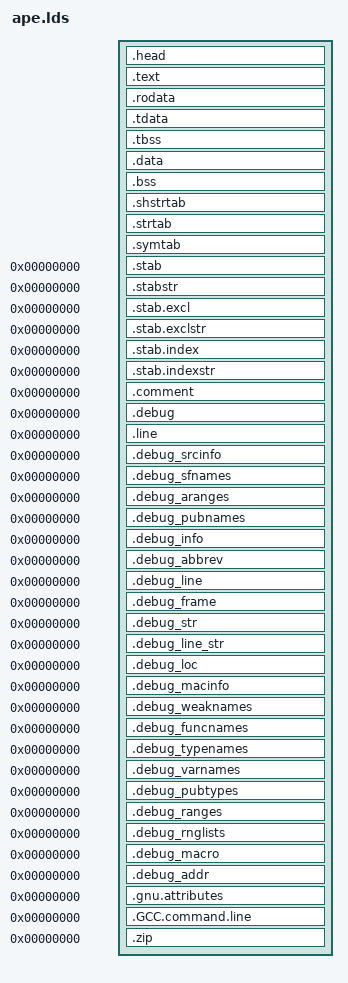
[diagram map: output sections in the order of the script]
ENTRY(_start)
PHDRS {
  Head 1 FLAGS(1|4);
  Cod 1 FLAGS(1|4);
  Rom 1 FLAGS(4);
  Tls 7 FLAGS(2|4);
  Ram 1 FLAGS(2|4);
  stack 0x6474e551 FLAGS(2|4);
}
SECTIONS {
  .head SEGMENT_START("text-segment", 0x400000) + 0 : AT(0x2000) {
    __executable_start = .;
    KEEP(*(.head))
    KEEP(*(.apesh))
    KEEP(*(.text.head))
    . = ALIGN(. != 0 ? 8 : 0);
    ape_phdrs = .;
    KEEP(*(.elf.phdrs))
    ape_phdrs_end = .;
    KEEP(*(.emushprologue))
    KEEP(*(.emush))
    KEEP(*(.emushepilogue))
    . = ALIGN(. != 0 ? 8 : 0);
    ape_note = .;
    KEEP(*(.note.openbsd.ident))
    KEEP(*(.note.netbsd.ident))
    ape_note_end = .;
    KEEP(*(.pe.header))
    ape_pe_sections = .;
    KEEP(*(.pe.sections))
    ape_pe_sections_end = .;
    KEEP(*(.macho))
    . = ALIGN(. != 0 ? 8 : 0);
    ape_macho_end = .;
    KEEP(*(.ape.loader))
    . = ALIGN(. != 0 ? 1 : 0);
    KEEP(*(.ape.pad.head))
    . = ALIGN(. != 0 ? (((255 & 4) == 4) || ((255 & 2) == 2) ? CONSTANT(COMMONPAGESIZE) : 16) : 0);
    _ehead = .;
  } :Head
  .text . : {
    BYTE(0x90)
    *(.text.real)
    KEEP(*(SORT_BY_NAME(.sort.text.real.*)))
    _ereal = .;
    . += 1;
    *(.start)
    KEEP(*(.initprologue))
    KEEP(*(SORT_BY_NAME(.init.*)))
    KEEP(*(.init))
    KEEP(*(.initepilogue))
    KEEP(*(.pltprologue))
    *(.plt)
    KEEP(*(.pltepilogue))
    KEEP(*(.pltgotprologue))
    *(.plt.got)
    KEEP(*(.pltgotepilogue))
    *(.text.startup .text.startup.*)
    *(.text.exit .text.exit.*)
    *(.text.unlikely .text.*_unlikely .text.unlikely.*)
    *(SORT_BY_ALIGNMENT(.text.antiquity))
    *(SORT_BY_ALIGNMENT(.text.antiquity.*))
    KEEP(*(.textwindowsprologue))
    *(.text.windows)
    KEEP(*(.textwindowsepilogue))
    KEEP(*(.blink))
    *(SORT_BY_ALIGNMENT(.text.modernity))
    *(SORT_BY_ALIGNMENT(.text.modernity.*))
    *(SORT_BY_ALIGNMENT(.text.hot))
    *(SORT_BY_ALIGNMENT(.text.hot.*))
    KEEP(*(.keep.text))
    *(.text .stub .text.*)
    KEEP(*(SORT_BY_NAME(.sort.text.*)))
    KEEP(*(.ape.pad.test));
    *(.test.unlikely)
    *(.test .test.*)
    KEEP(*(.ape.pad.privileged));
    . = ALIGN(__privileged_end > __privileged_start ? CONSTANT(COMMONPAGESIZE) : 0);
    __privileged_start = .;
    *(.privileged)
    __privileged_end = .;
    KEEP(*(.ape.pad.text))
    . = ALIGN(. != 0 ? CONSTANT(COMMONPAGESIZE) : 0);
  } :Cod
  .rodata . : {
    KEEP(*(.rodata.pytab.0));
    KEEP(*(.rodata.pytab.1));
    KEEP(*(.rodata.pytab.2));
    *(.rodata .rodata.*)
    *(.ubsan.types)
    *(.ubsan.data)
    KEEP(*(.commentprologue))
    KEEP(*(.comment))
    KEEP(*(.commentepilogue))
    KEEP(*(.idata.ro));
    KEEP(*(SORT_BY_NAME(.idata.ro.*)))
    KEEP(*(.initroprologue))
    KEEP(*(SORT_BY_NAME(.initro.*)))
    KEEP(*(.initroepilogue))
    KEEP(*(SORT_BY_NAME(.sort.rodata.*)))
    . = ALIGN(. != 0 ? CONSTANT(COMMONPAGESIZE) : 0);
  } :Rom
  .tdata . : {
    _tdata_start = .;
    *(SORT_BY_ALIGNMENT(.tdata))
    *(SORT_BY_ALIGNMENT(.tdata.*))
    _tdata_end = .;
    KEEP(*(.ape.pad.rodata))
    . = ALIGN(. != 0 ? CONSTANT(COMMONPAGESIZE) : 0);
    _etext = .;
    PROVIDE(etext = .);
  } :Tls :Rom
  . = ALIGN(CONSTANT(COMMONPAGESIZE));
  .tbss : {
    _tbss_start = .;
    *(SORT_BY_ALIGNMENT(.tbss))
    *(SORT_BY_ALIGNMENT(.tbss.*))
    KEEP(*(.fstls))
    _tbss_end = .;
  } :Tls
  .data . : {
    KEEP(*(SORT_BY_NAME(.piro.data.sort.iat.*)))
    KEEP(*(.dataprologue))
    *(.data .data.*)
    *(.PyRuntime)
    *(.subrs)
    KEEP(*(SORT_BY_NAME(.sort.data.*)))
    . += . > 0 ? 1 : 0;
    KEEP(*(.gotprologue))
    *(.got)
    KEEP(*(.gotepilogue))
    KEEP(*(.gotpltprologue))
    *(.got.plt)
    KEEP(*(.gotpltepilogue))
    . = ALIGN(. != 0 ? 8 : 0);
    __init_array_start = .;
    KEEP(*(SORT_BY_INIT_PRIORITY(.init_array.*)
           SORT_BY_INIT_PRIORITY(.ctors.*)))
    KEEP(*(.ctors))
    KEEP(*(.init_array))
    KEEP(*(.preinit_array))
    __init_array_end = .;
    . = ALIGN(. != 0 ? 8 : 0);
    __fini_array_start = .;
    KEEP(*(SORT_BY_INIT_PRIORITY(.fini_array.*)
           SORT_BY_INIT_PRIORITY(.dtors.*)))
    KEEP(*(.fini_array))
    KEEP(*(.dtors))
    __fini_array_end = .;
    . = ALIGN(. != 0 ? 8 : 0);
    KEEP(*(SORT_BY_NAME(.piro.relo.sort.*)))
    . = ALIGN(. != 0 ? 8 : 0);
    KEEP(*(SORT_BY_NAME(.piro.data.sort.*)))
    KEEP(*(.piro.pad.data))
    KEEP(*(.dataepilogue))
    . = ALIGN(. != 0 ? CONSTANT(COMMONPAGESIZE) : 0);
    _edata = .;
    PROVIDE(edata = .);
    _ezip = .;
  } :Ram
  . = ALIGN(CONSTANT(COMMONPAGESIZE));
  .bss : {
    KEEP(*(.bssprologue))
    KEEP(*(SORT_BY_NAME(.piro.bss.init.*)))
    *(.piro.bss)
    KEEP(*(SORT_BY_NAME(.piro.bss.sort.*)))
    __piro_end = .;
    . += . > 0 ? 1 : 0;
    *(SORT_BY_ALIGNMENT(.bss))
    *(SORT_BY_ALIGNMENT(.bss.*))
    *(COMMON)
    KEEP(*(SORT_BY_NAME(.sort.bss.*)))
    KEEP(*(.bssepilogue))
    . = ALIGN(. != 0 ? CONSTANT(COMMONPAGESIZE) : 0);
  } :Ram
  . = ALIGN(CONSTANT(COMMONPAGESIZE));
  _end = .;
  PROVIDE(end = .);
  .shstrtab : { *(.shstrtab) }
  .strtab : { *(.strtab) }
  .symtab : { *(.symtab) }
  .stab 0 : { *(.stab) }
  .stabstr 0 : { *(.stabstr) }
  .stab.excl 0 : { *(.stab.excl) }
  .stab.exclstr 0 : { *(.stab.exclstr) }
  .stab.index 0 : { *(.stab.index) }
  .stab.indexstr 0 : { *(.stab.indexstr) }
  .comment 0 : { *(.comment) }
  .debug 0 : { *(.debug) }
  .line 0 : { *(.line) }
  .debug_srcinfo 0 : { *(.debug_srcinfo) }
  .debug_sfnames 0 : { *(.debug_sfnames) }
  .debug_aranges 0 : { *(.debug_aranges) }
  .debug_pubnames 0 : { *(.debug_pubnames) }
  .debug_info 0 : { *(.debug_info .gnu.linkonce.wi.*) }
  .debug_abbrev 0 : { *(.debug_abbrev) }
  .debug_line 0 : { *(.debug_line .debug_line.* .debug_line_end ) }
  .debug_frame 0 : { *(.debug_frame) }
  .debug_str 0 : { *(.debug_str) }
  .debug_line_str 0 : { *(.debug_line_str) }
  .debug_loc 0 : { *(.debug_loc) }
  .debug_macinfo 0 : { *(.debug_macinfo) }
  .debug_weaknames 0 : { *(.debug_weaknames) }
  .debug_funcnames 0 : { *(.debug_funcnames) }
  .debug_typenames 0 : { *(.debug_typenames) }
  .debug_varnames 0 : { *(.debug_varnames) }
  .debug_pubtypes 0 : { *(.debug_pubtypes) }
  .debug_ranges 0 : { *(.debug_ranges) }
  .debug_rnglists 0 : { *(.debug_rnglists) }
  .debug_macro 0 : { *(.debug_macro) }
  .debug_addr 0 : { *(.debug_addr) }
  .gnu.attributes 0 : { KEEP(*(.gnu.attributes)) }
  .GCC.command.line 0 : { *(.GCC.command.line) }
  .zip 0 : {
    KEEP(*(.zip.file))
    __zip_cdir_start = .;
    KEEP(*(.zip.cdir))
    __zip_cdir_size = . - __zip_cdir_start;
    KEEP(*(.zip.eocd))
  }
  /DISCARD/ : {
    *(__patchable_function_entries)
    *(__mcount_loc)
    *(.discard)
    *(.yoink)
  }
}
ape_pe_filealignment = 512;
ape_pe_sectionalignment = 4096;
ape_pe_sizeofheaders = SIZEOF(.head);
ape_pe_sizeofimage = (((_end - __executable_start) + (ape_pe_sectionalignment)-1) & -(ape_pe_sectionalignment));
HIDDEN(ape_elf_entry = (_start)); HIDDEN(ape_elf_entry_bcs0 = (((((((_start) >> ((0)*8)) >> 0)&0x7) + 0x30) << 24) | ((((((_start) >> ((0)*8)) >> 3)&0x7) + 0x30) << 16) | (((((((_start) >> ((0)*8))&0xff) >> 6)&0x7) + 0x30) << 8) | 0x5c)); HIDDEN(ape_elf_entry_bcs1 = (((((((_start) >> ((1)*8)) >> 0)&0x7) + 0x30) << 24) | ((((((_start) >> ((1)*8)) >> 3)&0x7) + 0x30) << 16) | (((((((_start) >> ((1)*8))&0xff) >> 6)&0x7) + 0x30) << 8) | 0x5c)); HIDDEN(ape_elf_entry_bcs2 = (((((((_start) >> ((2)*8)) >> 0)&0x7) + 0x30) << 24) | ((((((_start) >> ((2)*8)) >> 3)&0x7) + 0x30) << 16) | (((((((_start) >> ((2)*8))&0xff) >> 6)&0x7) + 0x30) << 8) | 0x5c)); HIDDEN(ape_elf_entry_bcs3 = (((((((_start) >> ((3)*8)) >> 0)&0x7) + 0x30) << 24) | ((((((_start) >> ((3)*8)) >> 3)&0x7) + 0x30) << 16) | (((((((_start) >> ((3)*8))&0xff) >> 6)&0x7) + 0x30) << 8) | 0x5c)); HIDDEN(ape_elf_entry_bcs4 = (((((((_start) >> ((4)*8)) >> 0)&0x7) + 0x30) << 24) | ((((((_start) >> ((4)*8)) >> 3)&0x7) + 0x30) << 16) | (((((((_start) >> ((4)*8))&0xff) >> 6)&0x7) + 0x30) << 8) | 0x5c)); HIDDEN(ape_elf_entry_bcs5 = (((((((_start) >> ((5)*8)) >> 0)&0x7) + 0x30) << 24) | ((((((_start) >> ((5)*8)) >> 3)&0x7) + 0x30) << 16) | (((((((_start) >> ((5)*8))&0xff) >> 6)&0x7) + 0x30) << 8) | 0x5c)); HIDDEN(ape_elf_entry_bcs6 = (((((((_start) >> ((6)*8)) >> 0)&0x7) + 0x30) << 24) | ((((((_start) >> ((6)*8)) >> 3)&0x7) + 0x30) << 16) | (((((((_start) >> ((6)*8))&0xff) >> 6)&0x7) + 0x30) << 8) | 0x5c)); HIDDEN(ape_elf_entry_bcs7 = (((((((_start) >> ((7)*8)) >> 0)&0x7) + 0x30) << 24) | ((((((_start) >> ((7)*8)) >> 3)&0x7) + 0x30) << 16) | (((((((_start) >> ((7)*8))&0xff) >> 6)&0x7) + 0x30) << 8) | 0x5c));
HIDDEN(ape_elf_phoff = (((ape_phdrs) - (0x400000)))); HIDDEN(ape_elf_phoff_bcs0 = (((((((((ape_phdrs) - (0x400000))) >> ((0)*8)) >> 0)&0x7) + 0x30) << 24) | ((((((((ape_phdrs) - (0x400000))) >> ((0)*8)) >> 3)&0x7) + 0x30) << 16) | (((((((((ape_phdrs) - (0x400000))) >> ((0)*8))&0xff) >> 6)&0x7) + 0x30) << 8) | 0x5c)); HIDDEN(ape_elf_phoff_bcs1 = (((((((((ape_phdrs) - (0x400000))) >> ((1)*8)) >> 0)&0x7) + 0x30) << 24) | ((((((((ape_phdrs) - (0x400000))) >> ((1)*8)) >> 3)&0x7) + 0x30) << 16) | (((((((((ape_phdrs) - (0x400000))) >> ((1)*8))&0xff) >> 6)&0x7) + 0x30) << 8) | 0x5c)); HIDDEN(ape_elf_phoff_bcs2 = (((((((((ape_phdrs) - (0x400000))) >> ((2)*8)) >> 0)&0x7) + 0x30) << 24) | ((((((((ape_phdrs) - (0x400000))) >> ((2)*8)) >> 3)&0x7) + 0x30) << 16) | (((((((((ape_phdrs) - (0x400000))) >> ((2)*8))&0xff) >> 6)&0x7) + 0x30) << 8) | 0x5c)); HIDDEN(ape_elf_phoff_bcs3 = (((((((((ape_phdrs) - (0x400000))) >> ((3)*8)) >> 0)&0x7) + 0x30) << 24) | ((((((((ape_phdrs) - (0x400000))) >> ((3)*8)) >> 3)&0x7) + 0x30) << 16) | (((((((((ape_phdrs) - (0x400000))) >> ((3)*8))&0xff) >> 6)&0x7) + 0x30) << 8) | 0x5c)); HIDDEN(ape_elf_phoff_bcs4 = (((((((((ape_phdrs) - (0x400000))) >> ((4)*8)) >> 0)&0x7) + 0x30) << 24) | ((((((((ape_phdrs) - (0x400000))) >> ((4)*8)) >> 3)&0x7) + 0x30) << 16) | (((((((((ape_phdrs) - (0x400000))) >> ((4)*8))&0xff) >> 6)&0x7) + 0x30) << 8) | 0x5c)); HIDDEN(ape_elf_phoff_bcs5 = (((((((((ape_phdrs) - (0x400000))) >> ((5)*8)) >> 0)&0x7) + 0x30) << 24) | ((((((((ape_phdrs) - (0x400000))) >> ((5)*8)) >> 3)&0x7) + 0x30) << 16) | (((((((((ape_phdrs) - (0x400000))) >> ((5)*8))&0xff) >> 6)&0x7) + 0x30) << 8) | 0x5c)); HIDDEN(ape_elf_phoff_bcs6 = (((((((((ape_phdrs) - (0x400000))) >> ((6)*8)) >> 0)&0x7) + 0x30) << 24) | ((((((((ape_phdrs) - (0x400000))) >> ((6)*8)) >> 3)&0x7) + 0x30) << 16) | (((((((((ape_phdrs) - (0x400000))) >> ((6)*8))&0xff) >> 6)&0x7) + 0x30) << 8) | 0x5c)); HIDDEN(ape_elf_phoff_bcs7 = (((((((((ape_phdrs) - (0x400000))) >> ((7)*8)) >> 0)&0x7) + 0x30) << 24) | ((((((((ape_phdrs) - (0x400000))) >> ((7)*8)) >> 3)&0x7) + 0x30) << 16) | (((((((((ape_phdrs) - (0x400000))) >> ((7)*8))&0xff) >> 6)&0x7) + 0x30) << 8) | 0x5c));
HIDDEN(ape_elf_shoff = (0)); HIDDEN(ape_elf_shoff_bcs0 = (((((((0) >> ((0)*8)) >> 0)&0x7) + 0x30) << 24) | ((((((0) >> ((0)*8)) >> 3)&0x7) + 0x30) << 16) | (((((((0) >> ((0)*8))&0xff) >> 6)&0x7) + 0x30) << 8) | 0x5c)); HIDDEN(ape_elf_shoff_bcs1 = (((((((0) >> ((1)*8)) >> 0)&0x7) + 0x30) << 24) | ((((((0) >> ((1)*8)) >> 3)&0x7) + 0x30) << 16) | (((((((0) >> ((1)*8))&0xff) >> 6)&0x7) + 0x30) << 8) | 0x5c)); HIDDEN(ape_elf_shoff_bcs2 = (((((((0) >> ((2)*8)) >> 0)&0x7) + 0x30) << 24) | ((((((0) >> ((2)*8)) >> 3)&0x7) + 0x30) << 16) | (((((((0) >> ((2)*8))&0xff) >> 6)&0x7) + 0x30) << 8) | 0x5c)); HIDDEN(ape_elf_shoff_bcs3 = (((((((0) >> ((3)*8)) >> 0)&0x7) + 0x30) << 24) | ((((((0) >> ((3)*8)) >> 3)&0x7) + 0x30) << 16) | (((((((0) >> ((3)*8))&0xff) >> 6)&0x7) + 0x30) << 8) | 0x5c)); HIDDEN(ape_elf_shoff_bcs4 = (((((((0) >> ((4)*8)) >> 0)&0x7) + 0x30) << 24) | ((((((0) >> ((4)*8)) >> 3)&0x7) + 0x30) << 16) | (((((((0) >> ((4)*8))&0xff) >> 6)&0x7) + 0x30) << 8) | 0x5c)); HIDDEN(ape_elf_shoff_bcs5 = (((((((0) >> ((5)*8)) >> 0)&0x7) + 0x30) << 24) | ((((((0) >> ((5)*8)) >> 3)&0x7) + 0x30) << 16) | (((((((0) >> ((5)*8))&0xff) >> 6)&0x7) + 0x30) << 8) | 0x5c)); HIDDEN(ape_elf_shoff_bcs6 = (((((((0) >> ((6)*8)) >> 0)&0x7) + 0x30) << 24) | ((((((0) >> ((6)*8)) >> 3)&0x7) + 0x30) << 16) | (((((((0) >> ((6)*8))&0xff) >> 6)&0x7) + 0x30) << 8) | 0x5c)); HIDDEN(ape_elf_shoff_bcs7 = (((((((0) >> ((7)*8)) >> 0)&0x7) + 0x30) << 24) | ((((((0) >> ((7)*8)) >> 3)&0x7) + 0x30) << 16) | (((((((0) >> ((7)*8))&0xff) >> 6)&0x7) + 0x30) << 8) | 0x5c));
HIDDEN(ape_elf_phnum = ((ape_phdrs_end - ape_phdrs) / 56)); HIDDEN(ape_elf_phnum_bcs0 = ((((((((ape_phdrs_end - ape_phdrs) / 56) >> ((0)*8)) >> 0)&0x7) + 0x30) << 24) | (((((((ape_phdrs_end - ape_phdrs) / 56) >> ((0)*8)) >> 3)&0x7) + 0x30) << 16) | ((((((((ape_phdrs_end - ape_phdrs) / 56) >> ((0)*8))&0xff) >> 6)&0x7) + 0x30) << 8) | 0x5c)); HIDDEN(ape_elf_phnum_bcs1 = ((((((((ape_phdrs_end - ape_phdrs) / 56) >> ((1)*8)) >> 0)&0x7) + 0x30) << 24) | (((((((ape_phdrs_end - ape_phdrs) / 56) >> ((1)*8)) >> 3)&0x7) + 0x30) << 16) | ((((((((ape_phdrs_end - ape_phdrs) / 56) >> ((1)*8))&0xff) >> 6)&0x7) + 0x30) << 8) | 0x5c)); HIDDEN(ape_elf_phnum_bcs2 = ((((((((ape_phdrs_end - ape_phdrs) / 56) >> ((2)*8)) >> 0)&0x7) + 0x30) << 24) | (((((((ape_phdrs_end - ape_phdrs) / 56) >> ((2)*8)) >> 3)&0x7) + 0x30) << 16) | ((((((((ape_phdrs_end - ape_phdrs) / 56) >> ((2)*8))&0xff) >> 6)&0x7) + 0x30) << 8) | 0x5c)); HIDDEN(ape_elf_phnum_bcs3 = ((((((((ape_phdrs_end - ape_phdrs) / 56) >> ((3)*8)) >> 0)&0x7) + 0x30) << 24) | (((((((ape_phdrs_end - ape_phdrs) / 56) >> ((3)*8)) >> 3)&0x7) + 0x30) << 16) | ((((((((ape_phdrs_end - ape_phdrs) / 56) >> ((3)*8))&0xff) >> 6)&0x7) + 0x30) << 8) | 0x5c));
HIDDEN(ape_elf_shnum = (0)); HIDDEN(ape_elf_shnum_bcs0 = (((((((0) >> ((0)*8)) >> 0)&0x7) + 0x30) << 24) | ((((((0) >> ((0)*8)) >> 3)&0x7) + 0x30) << 16) | (((((((0) >> ((0)*8))&0xff) >> 6)&0x7) + 0x30) << 8) | 0x5c)); HIDDEN(ape_elf_shnum_bcs1 = (((((((0) >> ((1)*8)) >> 0)&0x7) + 0x30) << 24) | ((((((0) >> ((1)*8)) >> 3)&0x7) + 0x30) << 16) | (((((((0) >> ((1)*8))&0xff) >> 6)&0x7) + 0x30) << 8) | 0x5c)); HIDDEN(ape_elf_shnum_bcs2 = (((((((0) >> ((2)*8)) >> 0)&0x7) + 0x30) << 24) | ((((((0) >> ((2)*8)) >> 3)&0x7) + 0x30) << 16) | (((((((0) >> ((2)*8))&0xff) >> 6)&0x7) + 0x30) << 8) | 0x5c)); HIDDEN(ape_elf_shnum_bcs3 = (((((((0) >> ((3)*8)) >> 0)&0x7) + 0x30) << 24) | ((((((0) >> ((3)*8)) >> 3)&0x7) + 0x30) << 16) | (((((((0) >> ((3)*8))&0xff) >> 6)&0x7) + 0x30) << 8) | 0x5c));
HIDDEN(ape_elf_shstrndx = (0)); HIDDEN(ape_elf_shstrndx_bcs0 = (((((((0) >> ((0)*8)) >> 0)&0x7) + 0x30) << 24) | ((((((0) >> ((0)*8)) >> 3)&0x7) + 0x30) << 16) | (((((((0) >> ((0)*8))&0xff) >> 6)&0x7) + 0x30) << 8) | 0x5c)); HIDDEN(ape_elf_shstrndx_bcs1 = (((((((0) >> ((1)*8)) >> 0)&0x7) + 0x30) << 24) | ((((((0) >> ((1)*8)) >> 3)&0x7) + 0x30) << 16) | (((((((0) >> ((1)*8))&0xff) >> 6)&0x7) + 0x30) << 8) | 0x5c)); HIDDEN(ape_elf_shstrndx_bcs2 = (((((((0) >> ((2)*8)) >> 0)&0x7) + 0x30) << 24) | ((((((0) >> ((2)*8)) >> 3)&0x7) + 0x30) << 16) | (((((((0) >> ((2)*8))&0xff) >> 6)&0x7) + 0x30) << 8) | 0x5c)); HIDDEN(ape_elf_shstrndx_bcs3 = (((((((0) >> ((3)*8)) >> 0)&0x7) + 0x30) << 24) | ((((((0) >> ((3)*8)) >> 3)&0x7) + 0x30) << 16) | (((((((0) >> ((3)*8))&0xff) >> 6)&0x7) + 0x30) << 8) | 0x5c));
_tls_size = _tbss_end - _tdata_start;
_tdata_size = _tdata_end - _tdata_start;
_tbss_size = _tbss_end - _tbss_start;
_tbss_offset = _tbss_start - _tdata_start;
_tls_content = (_tdata_end - _tdata_start) + (_tbss_end - _tbss_start);
_tls_align = 1;
ape_cod_offset = 0;
ape_cod_vaddr = ADDR(.head);
ape_cod_paddr = LOADADDR(.head);
ape_cod_filesz = ADDR(.rodata) - ADDR(.head);
ape_cod_memsz = ape_cod_filesz;
ape_cod_align = CONSTANT(COMMONPAGESIZE);
ape_cod_rva = ((ape_cod_vaddr) - (0x400000));
ape_rom_vaddr = ADDR(.rodata);
ape_rom_offset = ape_rom_vaddr - __executable_start;
ape_rom_paddr = LOADADDR(.rodata);
ape_rom_filesz = ADDR(.tbss) - ADDR(.rodata);
ape_rom_memsz = ape_rom_filesz;
ape_rom_align = CONSTANT(COMMONPAGESIZE);
ape_rom_rva = ((ape_rom_vaddr) - (0x400000));
ape_ram_vaddr = ADDR(.data);
ape_ram_offset = ape_ram_vaddr - __executable_start;
ape_ram_paddr = LOADADDR(.data);
ape_ram_filesz = ADDR(.bss) - ADDR(.data);
ape_ram_memsz = _end - ADDR(.data);
ape_ram_align = CONSTANT(COMMONPAGESIZE);
ape_ram_rva = ((ape_ram_vaddr) - (0x400000));
ape_stack_pf = DEFINED(ape_stack_pf) ? ape_stack_pf : 4 | 2;
ape_stack_prot = ((4 & (ape_stack_pf)) >> 2 | (2 & (ape_stack_pf)) | (1 & (ape_stack_pf)) << 2);
ape_stack_offset = 0;
ape_stack_vaddr = DEFINED(ape_stack_vaddr) ? ape_stack_vaddr : 0x700000000000;
ape_stack_paddr = ape_ram_paddr + ape_ram_filesz;
ape_stack_filesz = 0;
ape_stack_memsz = DEFINED(ape_stack_memsz) ? ape_stack_memsz : 8 * 1024 * 1024;
ape_stack_align = DEFINED(ape_stack_align) ? ape_stack_align : 16;
ape_stack_round = -ape_stack_align;
ape_note_offset = ape_cod_offset + (ape_note - ape_cod_vaddr);
ape_note_filesz = ape_note_end - ape_note;
ape_note_memsz = ape_note_filesz;
ape_text_vaddr = ADDR(.text);
ape_text_offset = ape_text_vaddr - __executable_start;
ape_text_paddr = LOADADDR(.text);
ape_text_filesz = ADDR(.rodata) - ADDR(.text);
ape_text_memsz = ape_text_filesz;
ape_text_align = CONSTANT(COMMONPAGESIZE);
ape_text_rva = ((ape_text_vaddr) - (0x400000));
HIDDEN(ape_loader_dd_skip_bcs0 = (((DEFINED(ape_loader) ? ((ape_loader) - (0x400000)) / 64 : 0)) < 10000 ? (((((DEFINED(ape_loader) ? ((ape_loader) - (0x400000)) / 64 : 0) + (DEFINED(ape_loader) ? ((ape_loader) - (0x400000)) / 64 : 0) * 10000))) < 10000 ? 0x20202020 : (((DEFINED(ape_loader) ? ((ape_loader) - (0x400000)) / 64 : 0) + (DEFINED(ape_loader) ? ((ape_loader) - (0x400000)) / 64 : 0) * 10000)) < 100000 ? 0x20202030 + (((DEFINED(ape_loader) ? ((ape_loader) - (0x400000)) / 64 : 0) + (DEFINED(ape_loader) ? ((ape_loader) - (0x400000)) / 64 : 0) * 10000)) % 10 : (((DEFINED(ape_loader) ? ((ape_loader) - (0x400000)) / 64 : 0) + (DEFINED(ape_loader) ? ((ape_loader) - (0x400000)) / 64 : 0) * 10000)) < 1000000 ? 0x20203030 + ((((DEFINED(ape_loader) ? ((ape_loader) - (0x400000)) / 64 : 0) + (DEFINED(ape_loader) ? ((ape_loader) - (0x400000)) / 64 : 0) * 10000)) / 10) % 10 + (((DEFINED(ape_loader) ? ((ape_loader) - (0x400000)) / 64 : 0) + (DEFINED(ape_loader) ? ((ape_loader) - (0x400000)) / 64 : 0) * 10000)) % 10 * 0x100 : (((DEFINED(ape_loader) ? ((ape_loader) - (0x400000)) / 64 : 0) + (DEFINED(ape_loader) ? ((ape_loader) - (0x400000)) / 64 : 0) * 10000)) < 10000000 ? 0x20303030 + ((((DEFINED(ape_loader) ? ((ape_loader) - (0x400000)) / 64 : 0) + (DEFINED(ape_loader) ? ((ape_loader) - (0x400000)) / 64 : 0) * 10000)) / 100) % 10 + ((((DEFINED(ape_loader) ? ((ape_loader) - (0x400000)) / 64 : 0) + (DEFINED(ape_loader) ? ((ape_loader) - (0x400000)) / 64 : 0) * 10000)) / 10) % 10 * 0x100 + (((DEFINED(ape_loader) ? ((ape_loader) - (0x400000)) / 64 : 0) + (DEFINED(ape_loader) ? ((ape_loader) - (0x400000)) / 64 : 0) * 10000)) % 10 * 0x10000 : (((DEFINED(ape_loader) ? ((ape_loader) - (0x400000)) / 64 : 0) + (DEFINED(ape_loader) ? ((ape_loader) - (0x400000)) / 64 : 0) * 10000)) < 100000000 ? 0x30303030 + ((((DEFINED(ape_loader) ? ((ape_loader) - (0x400000)) / 64 : 0) + (DEFINED(ape_loader) ? ((ape_loader) - (0x400000)) / 64 : 0) * 10000)) / 1000) % 10 + ((((DEFINED(ape_loader) ? ((ape_loader) - (0x400000)) / 64 : 0) + (DEFINED(ape_loader) ? ((ape_loader) - (0x400000)) / 64 : 0) * 10000)) / 100) % 10 * 0x100 + ((((DEFINED(ape_loader) ? ((ape_loader) - (0x400000)) / 64 : 0) + (DEFINED(ape_loader) ? ((ape_loader) - (0x400000)) / 64 : 0) * 10000)) / 10) % 10 * 0x10000 + (((DEFINED(ape_loader) ? ((ape_loader) - (0x400000)) / 64 : 0) + (DEFINED(ape_loader) ? ((ape_loader) - (0x400000)) / 64 : 0) * 10000)) % 10 * 0x1000000 : 0xffffffffffffffff) | 0x10 : (DEFINED(ape_loader) ? ((ape_loader) - (0x400000)) / 64 : 0) < 100000 ? ((((((DEFINED(ape_loader) ? ((ape_loader) - (0x400000)) / 64 : 0) / 10) + ((DEFINED(ape_loader) ? ((ape_loader) - (0x400000)) / 64 : 0) / 10) * 10000))) < 10000 ? 0x20202020 : ((((DEFINED(ape_loader) ? ((ape_loader) - (0x400000)) / 64 : 0) / 10) + ((DEFINED(ape_loader) ? ((ape_loader) - (0x400000)) / 64 : 0) / 10) * 10000)) < 100000 ? 0x20202030 + ((((DEFINED(ape_loader) ? ((ape_loader) - (0x400000)) / 64 : 0) / 10) + ((DEFINED(ape_loader) ? ((ape_loader) - (0x400000)) / 64 : 0) / 10) * 10000)) % 10 : ((((DEFINED(ape_loader) ? ((ape_loader) - (0x400000)) / 64 : 0) / 10) + ((DEFINED(ape_loader) ? ((ape_loader) - (0x400000)) / 64 : 0) / 10) * 10000)) < 1000000 ? 0x20203030 + (((((DEFINED(ape_loader) ? ((ape_loader) - (0x400000)) / 64 : 0) / 10) + ((DEFINED(ape_loader) ? ((ape_loader) - (0x400000)) / 64 : 0) / 10) * 10000)) / 10) % 10 + ((((DEFINED(ape_loader) ? ((ape_loader) - (0x400000)) / 64 : 0) / 10) + ((DEFINED(ape_loader) ? ((ape_loader) - (0x400000)) / 64 : 0) / 10) * 10000)) % 10 * 0x100 : ((((DEFINED(ape_loader) ? ((ape_loader) - (0x400000)) / 64 : 0) / 10) + ((DEFINED(ape_loader) ? ((ape_loader) - (0x400000)) / 64 : 0) / 10) * 10000)) < 10000000 ? 0x20303030 + (((((DEFINED(ape_loader) ? ((ape_loader) - (0x400000)) / 64 : 0) / 10) + ((DEFINED(ape_loader) ? ((ape_loader) - (0x400000)) / 64 : 0) / 10) * 10000)) / 100) % 10 + (((((DEFINED(ape_loader) ? ((ape_loader) - (0x400000)) / 64 : 0) / 10) + ((DEFINED(ape_loader) ? ((ape_loader) - (0x400000)) / 64 : 0) / 10) * 10000)) / 10) % 10 * 0x100 + ((((DEFINED(ape_loader) ? ((ape_loader) - (0x400000)) / 64 : 0) / 10) + ((DEFINED(ape_loader) ? ((ape_loader) - (0x400000)) / 64 : 0) / 10) * 10000)) % 10 * 0x10000 : ((((DEFINED(ape_loader) ? ((ape_loader) - (0x400000)) / 64 : 0) / 10) + ((DEFINED(ape_loader) ? ((ape_loader) - (0x400000)) / 64 : 0) / 10) * 10000)) < 100000000 ? 0x30303030 + (((((DEFINED(ape_loader) ? ((ape_loader) - (0x400000)) / 64 : 0) / 10) + ((DEFINED(ape_loader) ? ((ape_loader) - (0x400000)) / 64 : 0) / 10) * 10000)) / 1000) % 10 + (((((DEFINED(ape_loader) ? ((ape_loader) - (0x400000)) / 64 : 0) / 10) + ((DEFINED(ape_loader) ? ((ape_loader) - (0x400000)) / 64 : 0) / 10) * 10000)) / 100) % 10 * 0x100 + (((((DEFINED(ape_loader) ? ((ape_loader) - (0x400000)) / 64 : 0) / 10) + ((DEFINED(ape_loader) ? ((ape_loader) - (0x400000)) / 64 : 0) / 10) * 10000)) / 10) % 10 * 0x10000 + ((((DEFINED(ape_loader) ? ((ape_loader) - (0x400000)) / 64 : 0) / 10) + ((DEFINED(ape_loader) ? ((ape_loader) - (0x400000)) / 64 : 0) / 10) * 10000)) % 10 * 0x1000000 : 0xffffffffffffffff) : (DEFINED(ape_loader) ? ((ape_loader) - (0x400000)) / 64 : 0) < 1000000 ? ((((((DEFINED(ape_loader) ? ((ape_loader) - (0x400000)) / 64 : 0) / 100) + ((DEFINED(ape_loader) ? ((ape_loader) - (0x400000)) / 64 : 0) / 100) * 10000))) < 10000 ? 0x20202020 : ((((DEFINED(ape_loader) ? ((ape_loader) - (0x400000)) / 64 : 0) / 100) + ((DEFINED(ape_loader) ? ((ape_loader) - (0x400000)) / 64 : 0) / 100) * 10000)) < 100000 ? 0x20202030 + ((((DEFINED(ape_loader) ? ((ape_loader) - (0x400000)) / 64 : 0) / 100) + ((DEFINED(ape_loader) ? ((ape_loader) - (0x400000)) / 64 : 0) / 100) * 10000)) % 10 : ((((DEFINED(ape_loader) ? ((ape_loader) - (0x400000)) / 64 : 0) / 100) + ((DEFINED(ape_loader) ? ((ape_loader) - (0x400000)) / 64 : 0) / 100) * 10000)) < 1000000 ? 0x20203030 + (((((DEFINED(ape_loader) ? ((ape_loader) - (0x400000)) / 64 : 0) / 100) + ((DEFINED(ape_loader) ? ((ape_loader) - (0x400000)) / 64 : 0) / 100) * 10000)) / 10) % 10 + ((((DEFINED(ape_loader) ? ((ape_loader) - (0x400000)) / 64 : 0) / 100) + ((DEFINED(ape_loader) ? ((ape_loader) - (0x400000)) / 64 : 0) / 100) * 10000)) % 10 * 0x100 : ((((DEFINED(ape_loader) ? ((ape_loader) - (0x400000)) / 64 : 0) / 100) + ((DEFINED(ape_loader) ? ((ape_loader) - (0x400000)) / 64 : 0) / 100) * 10000)) < 10000000 ? 0x20303030 + (((((DEFINED(ape_loader) ? ((ape_loader) - (0x400000)) / 64 : 0) / 100) + ((DEFINED(ape_loader) ? ((ape_loader) - (0x400000)) / 64 : 0) / 100) * 10000)) / 100) % 10 + (((((DEFINED(ape_loader) ? ((ape_loader) - (0x400000)) / 64 : 0) / 100) + ((DEFINED(ape_loader) ? ((ape_loader) - (0x400000)) / 64 : 0) / 100) * 10000)) / 10) % 10 * 0x100 + ((((DEFINED(ape_loader) ? ((ape_loader) - (0x400000)) / 64 : 0) / 100) + ((DEFINED(ape_loader) ? ((ape_loader) - (0x400000)) / 64 : 0) / 100) * 10000)) % 10 * 0x10000 : ((((DEFINED(ape_loader) ? ((ape_loader) - (0x400000)) / 64 : 0) / 100) + ((DEFINED(ape_loader) ? ((ape_loader) - (0x400000)) / 64 : 0) / 100) * 10000)) < 100000000 ? 0x30303030 + (((((DEFINED(ape_loader) ? ((ape_loader) - (0x400000)) / 64 : 0) / 100) + ((DEFINED(ape_loader) ? ((ape_loader) - (0x400000)) / 64 : 0) / 100) * 10000)) / 1000) % 10 + (((((DEFINED(ape_loader) ? ((ape_loader) - (0x400000)) / 64 : 0) / 100) + ((DEFINED(ape_loader) ? ((ape_loader) - (0x400000)) / 64 : 0) / 100) * 10000)) / 100) % 10 * 0x100 + (((((DEFINED(ape_loader) ? ((ape_loader) - (0x400000)) / 64 : 0) / 100) + ((DEFINED(ape_loader) ? ((ape_loader) - (0x400000)) / 64 : 0) / 100) * 10000)) / 10) % 10 * 0x10000 + ((((DEFINED(ape_loader) ? ((ape_loader) - (0x400000)) / 64 : 0) / 100) + ((DEFINED(ape_loader) ? ((ape_loader) - (0x400000)) / 64 : 0) / 100) * 10000)) % 10 * 0x1000000 : 0xffffffffffffffff) : (DEFINED(ape_loader) ? ((ape_loader) - (0x400000)) / 64 : 0) < 10000000 ? ((((((DEFINED(ape_loader) ? ((ape_loader) - (0x400000)) / 64 : 0) / 1000) + ((DEFINED(ape_loader) ? ((ape_loader) - (0x400000)) / 64 : 0) / 1000) * 10000))) < 10000 ? 0x20202020 : ((((DEFINED(ape_loader) ? ((ape_loader) - (0x400000)) / 64 : 0) / 1000) + ((DEFINED(ape_loader) ? ((ape_loader) - (0x400000)) / 64 : 0) / 1000) * 10000)) < 100000 ? 0x20202030 + ((((DEFINED(ape_loader) ? ((ape_loader) - (0x400000)) / 64 : 0) / 1000) + ((DEFINED(ape_loader) ? ((ape_loader) - (0x400000)) / 64 : 0) / 1000) * 10000)) % 10 : ((((DEFINED(ape_loader) ? ((ape_loader) - (0x400000)) / 64 : 0) / 1000) + ((DEFINED(ape_loader) ? ((ape_loader) - (0x400000)) / 64 : 0) / 1000) * 10000)) < 1000000 ? 0x20203030 + (((((DEFINED(ape_loader) ? ((ape_loader) - (0x400000)) / 64 : 0) / 1000) + ((DEFINED(ape_loader) ? ((ape_loader) - (0x400000)) / 64 : 0) / 1000) * 10000)) / 10) % 10 + ((((DEFINED(ape_loader) ? ((ape_loader) - (0x400000)) / 64 : 0) / 1000) + ((DEFINED(ape_loader) ? ((ape_loader) - (0x400000)) / 64 : 0) / 1000) * 10000)) % 10 * 0x100 : ((((DEFINED(ape_loader) ? ((ape_loader) - (0x400000)) / 64 : 0) / 1000) + ((DEFINED(ape_loader) ? ((ape_loader) - (0x400000)) / 64 : 0) / 1000) * 10000)) < 10000000 ? 0x20303030 + (((((DEFINED(ape_loader) ? ((ape_loader) - (0x400000)) / 64 : 0) / 1000) + ((DEFINED(ape_loader) ? ((ape_loader) - (0x400000)) / 64 : 0) / 1000) * 10000)) / 100) % 10 + (((((DEFINED(ape_loader) ? ((ape_loader) - (0x400000)) / 64 : 0) / 1000) + ((DEFINED(ape_loader) ? ((ape_loader) - (0x400000)) / 64 : 0) / 1000) * 10000)) / 10) % 10 * 0x100 + ((((DEFINED(ape_loader) ? ((ape_loader) - (0x400000)) / 64 : 0) / 1000) + ((DEFINED(ape_loader) ? ((ape_loader) - (0x400000)) / 64 : 0) / 1000) * 10000)) % 10 * 0x10000 : ((((DEFINED(ape_loader) ? ((ape_loader) - (0x400000)) / 64 : 0) / 1000) + ((DEFINED(ape_loader) ? ((ape_loader) - (0x400000)) / 64 : 0) / 1000) * 10000)) < 100000000 ? 0x30303030 + (((((DEFINED(ape_loader) ? ((ape_loader) - (0x400000)) / 64 : 0) / 1000) + ((DEFINED(ape_loader) ? ((ape_loader) - (0x400000)) / 64 : 0) / 1000) * 10000)) / 1000) % 10 + (((((DEFINED(ape_loader) ? ((ape_loader) - (0x400000)) / 64 : 0) / 1000) + ((DEFINED(ape_loader) ? ((ape_loader) - (0x400000)) / 64 : 0) / 1000) * 10000)) / 100) % 10 * 0x100 + (((((DEFINED(ape_loader) ? ((ape_loader) - (0x400000)) / 64 : 0) / 1000) + ((DEFINED(ape_loader) ? ((ape_loader) - (0x400000)) / 64 : 0) / 1000) * 10000)) / 10) % 10 * 0x10000 + ((((DEFINED(ape_loader) ? ((ape_loader) - (0x400000)) / 64 : 0) / 1000) + ((DEFINED(ape_loader) ? ((ape_loader) - (0x400000)) / 64 : 0) / 1000) * 10000)) % 10 * 0x1000000 : 0xffffffffffffffff) : (DEFINED(ape_loader) ? ((ape_loader) - (0x400000)) / 64 : 0) < 100000000 ? ((((((DEFINED(ape_loader) ? ((ape_loader) - (0x400000)) / 64 : 0) / 10000) + ((DEFINED(ape_loader) ? ((ape_loader) - (0x400000)) / 64 : 0) / 10000) * 10000))) < 10000 ? 0x20202020 : ((((DEFINED(ape_loader) ? ((ape_loader) - (0x400000)) / 64 : 0) / 10000) + ((DEFINED(ape_loader) ? ((ape_loader) - (0x400000)) / 64 : 0) / 10000) * 10000)) < 100000 ? 0x20202030 + ((((DEFINED(ape_loader) ? ((ape_loader) - (0x400000)) / 64 : 0) / 10000) + ((DEFINED(ape_loader) ? ((ape_loader) - (0x400000)) / 64 : 0) / 10000) * 10000)) % 10 : ((((DEFINED(ape_loader) ? ((ape_loader) - (0x400000)) / 64 : 0) / 10000) + ((DEFINED(ape_loader) ? ((ape_loader) - (0x400000)) / 64 : 0) / 10000) * 10000)) < 1000000 ? 0x20203030 + (((((DEFINED(ape_loader) ? ((ape_loader) - (0x400000)) / 64 : 0) / 10000) + ((DEFINED(ape_loader) ? ((ape_loader) - (0x400000)) / 64 : 0) / 10000) * 10000)) / 10) % 10 + ((((DEFINED(ape_loader) ? ((ape_loader) - (0x400000)) / 64 : 0) / 10000) + ((DEFINED(ape_loader) ? ((ape_loader) - (0x400000)) / 64 : 0) / 10000) * 10000)) % 10 * 0x100 : ((((DEFINED(ape_loader) ? ((ape_loader) - (0x400000)) / 64 : 0) / 10000) + ((DEFINED(ape_loader) ? ((ape_loader) - (0x400000)) / 64 : 0) / 10000) * 10000)) < 10000000 ? 0x20303030 + (((((DEFINED(ape_loader) ? ((ape_loader) - (0x400000)) / 64 : 0) / 10000) + ((DEFINED(ape_loader) ? ((ape_loader) - (0x400000)) / 64 : 0) / 10000) * 10000)) / 100) % 10 + (((((DEFINED(ape_loader) ? ((ape_loader) - (0x400000)) / 64 : 0) / 10000) + ((DEFINED(ape_loader) ? ((ape_loader) - (0x400000)) / 64 : 0) / 10000) * 10000)) / 10) % 10 * 0x100 + ((((DEFINED(ape_loader) ? ((ape_loader) - (0x400000)) / 64 : 0) / 10000) + ((DEFINED(ape_loader) ? ((ape_loader) - (0x400000)) / 64 : 0) / 10000) * 10000)) % 10 * 0x10000 : ((((DEFINED(ape_loader) ? ((ape_loader) - (0x400000)) / 64 : 0) / 10000) + ((DEFINED(ape_loader) ? ((ape_loader) - (0x400000)) / 64 : 0) / 10000) * 10000)) < 100000000 ? 0x30303030 + (((((DEFINED(ape_loader) ? ((ape_loader) - (0x400000)) / 64 : 0) / 10000) + ((DEFINED(ape_loader) ? ((ape_loader) - (0x400000)) / 64 : 0) / 10000) * 10000)) / 1000) % 10 + (((((DEFINED(ape_loader) ? ((ape_loader) - (0x400000)) / 64 : 0) / 10000) + ((DEFINED(ape_loader) ? ((ape_loader) - (0x400000)) / 64 : 0) / 10000) * 10000)) / 100) % 10 * 0x100 + (((((DEFINED(ape_loader) ? ((ape_loader) - (0x400000)) / 64 : 0) / 10000) + ((DEFINED(ape_loader) ? ((ape_loader) - (0x400000)) / 64 : 0) / 10000) * 10000)) / 10) % 10 * 0x10000 + ((((DEFINED(ape_loader) ? ((ape_loader) - (0x400000)) / 64 : 0) / 10000) + ((DEFINED(ape_loader) ? ((ape_loader) - (0x400000)) / 64 : 0) / 10000) * 10000)) % 10 * 0x1000000 : 0xffffffffffffffff) : 0xffffffffffffffff)); HIDDEN(ape_loader_dd_skip_bcs1 = (((DEFINED(ape_loader) ? ((ape_loader) - (0x400000)) / 64 : 0)) < 10000 ? 0x20202020 : (DEFINED(ape_loader) ? ((ape_loader) - (0x400000)) / 64 : 0) < 100000 ? 0x20202030 + (DEFINED(ape_loader) ? ((ape_loader) - (0x400000)) / 64 : 0) % 10 : (DEFINED(ape_loader) ? ((ape_loader) - (0x400000)) / 64 : 0) < 1000000 ? 0x20203030 + ((DEFINED(ape_loader) ? ((ape_loader) - (0x400000)) / 64 : 0) / 10) % 10 + (DEFINED(ape_loader) ? ((ape_loader) - (0x400000)) / 64 : 0) % 10 * 0x100 : (DEFINED(ape_loader) ? ((ape_loader) - (0x400000)) / 64 : 0) < 10000000 ? 0x20303030 + ((DEFINED(ape_loader) ? ((ape_loader) - (0x400000)) / 64 : 0) / 100) % 10 + ((DEFINED(ape_loader) ? ((ape_loader) - (0x400000)) / 64 : 0) / 10) % 10 * 0x100 + (DEFINED(ape_loader) ? ((ape_loader) - (0x400000)) / 64 : 0) % 10 * 0x10000 : (DEFINED(ape_loader) ? ((ape_loader) - (0x400000)) / 64 : 0) < 100000000 ? 0x30303030 + ((DEFINED(ape_loader) ? ((ape_loader) - (0x400000)) / 64 : 0) / 1000) % 10 + ((DEFINED(ape_loader) ? ((ape_loader) - (0x400000)) / 64 : 0) / 100) % 10 * 0x100 + ((DEFINED(ape_loader) ? ((ape_loader) - (0x400000)) / 64 : 0) / 10) % 10 * 0x10000 + (DEFINED(ape_loader) ? ((ape_loader) - (0x400000)) / 64 : 0) % 10 * 0x1000000 : 0xffffffffffffffff));
HIDDEN(ape_loader_dd_count_bcs0 = (((DEFINED(ape_loader_end) ? (((ape_loader_end - ape_loader) + (CONSTANT(COMMONPAGESIZE))-1) & -(CONSTANT(COMMONPAGESIZE))) / 64 : 0)) < 10000 ? (((((DEFINED(ape_loader_end) ? (((ape_loader_end - ape_loader) + (CONSTANT(COMMONPAGESIZE))-1) & -(CONSTANT(COMMONPAGESIZE))) / 64 : 0) + (DEFINED(ape_loader_end) ? (((ape_loader_end - ape_loader) + (CONSTANT(COMMONPAGESIZE))-1) & -(CONSTANT(COMMONPAGESIZE))) / 64 : 0) * 10000))) < 10000 ? 0x20202020 : (((DEFINED(ape_loader_end) ? (((ape_loader_end - ape_loader) + (CONSTANT(COMMONPAGESIZE))-1) & -(CONSTANT(COMMONPAGESIZE))) / 64 : 0) + (DEFINED(ape_loader_end) ? (((ape_loader_end - ape_loader) + (CONSTANT(COMMONPAGESIZE))-1) & -(CONSTANT(COMMONPAGESIZE))) / 64 : 0) * 10000)) < 100000 ? 0x20202030 + (((DEFINED(ape_loader_end) ? (((ape_loader_end - ape_loader) + (CONSTANT(COMMONPAGESIZE))-1) & -(CONSTANT(COMMONPAGESIZE))) / 64 : 0) + (DEFINED(ape_loader_end) ? (((ape_loader_end - ape_loader) + (CONSTANT(COMMONPAGESIZE))-1) & -(CONSTANT(COMMONPAGESIZE))) / 64 : 0) * 10000)) % 10 : (((DEFINED(ape_loader_end) ? (((ape_loader_end - ape_loader) + (CONSTANT(COMMONPAGESIZE))-1) & -(CONSTANT(COMMONPAGESIZE))) / 64 : 0) + (DEFINED(ape_loader_end) ? (((ape_loader_end - ape_loader) + (CONSTANT(COMMONPAGESIZE))-1) & -(CONSTANT(COMMONPAGESIZE))) / 64 : 0) * 10000)) < 1000000 ? 0x20203030 + ((((DEFINED(ape_loader_end) ? (((ape_loader_end - ape_loader) + (CONSTANT(COMMONPAGESIZE))-1) & -(CONSTANT(COMMONPAGESIZE))) / 64 : 0) + (DEFINED(ape_loader_end) ? (((ape_loader_end - ape_loader) + (CONSTANT(COMMONPAGESIZE))-1) & -(CONSTANT(COMMONPAGESIZE))) / 64 : 0) * 10000)) / 10) % 10 + (((DEFINED(ape_loader_end) ? (((ape_loader_end - ape_loader) + (CONSTANT(COMMONPAGESIZE))-1) & -(CONSTANT(COMMONPAGESIZE))) / 64 : 0) + (DEFINED(ape_loader_end) ? (((ape_loader_end - ape_loader) + (CONSTANT(COMMONPAGESIZE))-1) & -(CONSTANT(COMMONPAGESIZE))) / 64 : 0) * 10000)) % 10 * 0x100 : (((DEFINED(ape_loader_end) ? (((ape_loader_end - ape_loader) + (CONSTANT(COMMONPAGESIZE))-1) & -(CONSTANT(COMMONPAGESIZE))) / 64 : 0) + (DEFINED(ape_loader_end) ? (((ape_loader_end - ape_loader) + (CONSTANT(COMMONPAGESIZE))-1) & -(CONSTANT(COMMONPAGESIZE))) / 64 : 0) * 10000)) < 10000000 ? 0x20303030 + ((((DEFINED(ape_loader_end) ? (((ape_loader_end - ape_loader) + (CONSTANT(COMMONPAGESIZE))-1) & -(CONSTANT(COMMONPAGESIZE))) / 64 : 0) + (DEFINED(ape_loader_end) ? (((ape_loader_end - ape_loader) + (CONSTANT(COMMONPAGESIZE))-1) & -(CONSTANT(COMMONPAGESIZE))) / 64 : 0) * 10000)) / 100) % 10 + ((((DEFINED(ape_loader_end) ? (((ape_loader_end - ape_loader) + (CONSTANT(COMMONPAGESIZE))-1) & -(CONSTANT(COMMONPAGESIZE))) / 64 : 0) + (DEFINED(ape_loader_end) ? (((ape_loader_end - ape_loader) + (CONSTANT(COMMONPAGESIZE))-1) & -(CONSTANT(COMMONPAGESIZE))) / 64 : 0) * 10000)) / 10) % 10 * 0x100 + (((DEFINED(ape_loader_end) ? (((ape_loader_end - ape_loader) + (CONSTANT(COMMONPAGESIZE))-1) & -(CONSTANT(COMMONPAGESIZE))) / 64 : 0) + (DEFINED(ape_loader_end) ? (((ape_loader_end - ape_loader) + (CONSTANT(COMMONPAGESIZE))-1) & -(CONSTANT(COMMONPAGESIZE))) / 64 : 0) * 10000)) % 10 * 0x10000 : (((DEFINED(ape_loader_end) ? (((ape_loader_end - ape_loader) + (CONSTANT(COMMONPAGESIZE))-1) & -(CONSTANT(COMMONPAGESIZE))) / 64 : 0) + (DEFINED(ape_loader_end) ? (((ape_loader_end - ape_loader) + (CONSTANT(COMMONPAGESIZE))-1) & -(CONSTANT(COMMONPAGESIZE))) / 64 : 0) * 10000)) < 100000000 ? 0x30303030 + ((((DEFINED(ape_loader_end) ? (((ape_loader_end - ape_loader) + (CONSTANT(COMMONPAGESIZE))-1) & -(CONSTANT(COMMONPAGESIZE))) / 64 : 0) + (DEFINED(ape_loader_end) ? (((ape_loader_end - ape_loader) + (CONSTANT(COMMONPAGESIZE))-1) & -(CONSTANT(COMMONPAGESIZE))) / 64 : 0) * 10000)) / 1000) % 10 + ((((DEFINED(ape_loader_end) ? (((ape_loader_end - ape_loader) + (CONSTANT(COMMONPAGESIZE))-1) & -(CONSTANT(COMMONPAGESIZE))) / 64 : 0) + (DEFINED(ape_loader_end) ? (((ape_loader_end - ape_loader) + (CONSTANT(COMMONPAGESIZE))-1) & -(CONSTANT(COMMONPAGESIZE))) / 64 : 0) * 10000)) / 100) % 10 * 0x100 + ((((DEFINED(ape_loader_end) ? (((ape_loader_end - ape_loader) + (CONSTANT(COMMONPAGESIZE))-1) & -(CONSTANT(COMMONPAGESIZE))) / 64 : 0) + (DEFINED(ape_loader_end) ? (((ape_loader_end - ape_loader) + (CONSTANT(COMMONPAGESIZE))-1) & -(CONSTANT(COMMONPAGESIZE))) / 64 : 0) * 10000)) / 10) % 10 * 0x10000 + (((DEFINED(ape_loader_end) ? (((ape_loader_end - ape_loader) + (CONSTANT(COMMONPAGESIZE))-1) & -(CONSTANT(COMMONPAGESIZE))) / 64 : 0) + (DEFINED(ape_loader_end) ? (((ape_loader_end - ape_loader) + (CONSTANT(COMMONPAGESIZE))-1) & -(CONSTANT(COMMONPAGESIZE))) / 64 : 0) * 10000)) % 10 * 0x1000000 : 0xffffffffffffffff) | 0x10 : (DEFINED(ape_loader_end) ? (((ape_loader_end - ape_loader) + (CONSTANT(COMMONPAGESIZE))-1) & -(CONSTANT(COMMONPAGESIZE))) / 64 : 0) < 100000 ? ((((((DEFINED(ape_loader_end) ? (((ape_loader_end - ape_loader) + (CONSTANT(COMMONPAGESIZE))-1) & -(CONSTANT(COMMONPAGESIZE))) / 64 : 0) / 10) + ((DEFINED(ape_loader_end) ? (((ape_loader_end - ape_loader) + (CONSTANT(COMMONPAGESIZE))-1) & -(CONSTANT(COMMONPAGESIZE))) / 64 : 0) / 10) * 10000))) < 10000 ? 0x20202020 : ((((DEFINED(ape_loader_end) ? (((ape_loader_end - ape_loader) + (CONSTANT(COMMONPAGESIZE))-1) & -(CONSTANT(COMMONPAGESIZE))) / 64 : 0) / 10) + ((DEFINED(ape_loader_end) ? (((ape_loader_end - ape_loader) + (CONSTANT(COMMONPAGESIZE))-1) & -(CONSTANT(COMMONPAGESIZE))) / 64 : 0) / 10) * 10000)) < 100000 ? 0x20202030 + ((((DEFINED(ape_loader_end) ? (((ape_loader_end - ape_loader) + (CONSTANT(COMMONPAGESIZE))-1) & -(CONSTANT(COMMONPAGESIZE))) / 64 : 0) / 10) + ((DEFINED(ape_loader_end) ? (((ape_loader_end - ape_loader) + (CONSTANT(COMMONPAGESIZE))-1) & -(CONSTANT(COMMONPAGESIZE))) / 64 : 0) / 10) * 10000)) % 10 : ((((DEFINED(ape_loader_end) ? (((ape_loader_end - ape_loader) + (CONSTANT(COMMONPAGESIZE))-1) & -(CONSTANT(COMMONPAGESIZE))) / 64 : 0) / 10) + ((DEFINED(ape_loader_end) ? (((ape_loader_end - ape_loader) + (CONSTANT(COMMONPAGESIZE))-1) & -(CONSTANT(COMMONPAGESIZE))) / 64 : 0) / 10) * 10000)) < 1000000 ? 0x20203030 + (((((DEFINED(ape_loader_end) ? (((ape_loader_end - ape_loader) + (CONSTANT(COMMONPAGESIZE))-1) & -(CONSTANT(COMMONPAGESIZE))) / 64 : 0) / 10) + ((DEFINED(ape_loader_end) ? (((ape_loader_end - ape_loader) + (CONSTANT(COMMONPAGESIZE))-1) & -(CONSTANT(COMMONPAGESIZE))) / 64 : 0) / 10) * 10000)) / 10) % 10 + ((((DEFINED(ape_loader_end) ? (((ape_loader_end - ape_loader) + (CONSTANT(COMMONPAGESIZE))-1) & -(CONSTANT(COMMONPAGESIZE))) / 64 : 0) / 10) + ((DEFINED(ape_loader_end) ? (((ape_loader_end - ape_loader) + (CONSTANT(COMMONPAGESIZE))-1) & -(CONSTANT(COMMONPAGESIZE))) / 64 : 0) / 10) * 10000)) % 10 * 0x100 : ((((DEFINED(ape_loader_end) ? (((ape_loader_end - ape_loader) + (CONSTANT(COMMONPAGESIZE))-1) & -(CONSTANT(COMMONPAGESIZE))) / 64 : 0) / 10) + ((DEFINED(ape_loader_end) ? (((ape_loader_end - ape_loader) + (CONSTANT(COMMONPAGESIZE))-1) & -(CONSTANT(COMMONPAGESIZE))) / 64 : 0) / 10) * 10000)) < 10000000 ? 0x20303030 + (((((DEFINED(ape_loader_end) ? (((ape_loader_end - ape_loader) + (CONSTANT(COMMONPAGESIZE))-1) & -(CONSTANT(COMMONPAGESIZE))) / 64 : 0) / 10) + ((DEFINED(ape_loader_end) ? (((ape_loader_end - ape_loader) + (CONSTANT(COMMONPAGESIZE))-1) & -(CONSTANT(COMMONPAGESIZE))) / 64 : 0) / 10) * 10000)) / 100) % 10 + (((((DEFINED(ape_loader_end) ? (((ape_loader_end - ape_loader) + (CONSTANT(COMMONPAGESIZE))-1) & -(CONSTANT(COMMONPAGESIZE))) / 64 : 0) / 10) + ((DEFINED(ape_loader_end) ? (((ape_loader_end - ape_loader) + (CONSTANT(COMMONPAGESIZE))-1) & -(CONSTANT(COMMONPAGESIZE))) / 64 : 0) / 10) * 10000)) / 10) % 10 * 0x100 + ((((DEFINED(ape_loader_end) ? (((ape_loader_end - ape_loader) + (CONSTANT(COMMONPAGESIZE))-1) & -(CONSTANT(COMMONPAGESIZE))) / 64 : 0) / 10) + ((DEFINED(ape_loader_end) ? (((ape_loader_end - ape_loader) + (CONSTANT(COMMONPAGESIZE))-1) & -(CONSTANT(COMMONPAGESIZE))) / 64 : 0) / 10) * 10000)) % 10 * 0x10000 : ((((DEFINED(ape_loader_end) ? (((ape_loader_end - ape_loader) + (CONSTANT(COMMONPAGESIZE))-1) & -(CONSTANT(COMMONPAGESIZE))) / 64 : 0) / 10) + ((DEFINED(ape_loader_end) ? (((ape_loader_end - ape_loader) + (CONSTANT(COMMONPAGESIZE))-1) & -(CONSTANT(COMMONPAGESIZE))) / 64 : 0) / 10) * 10000)) < 100000000 ? 0x30303030 + (((((DEFINED(ape_loader_end) ? (((ape_loader_end - ape_loader) + (CONSTANT(COMMONPAGESIZE))-1) & -(CONSTANT(COMMONPAGESIZE))) / 64 : 0) / 10) + ((DEFINED(ape_loader_end) ? (((ape_loader_end - ape_loader) + (CONSTANT(COMMONPAGESIZE))-1) & -(CONSTANT(COMMONPAGESIZE))) / 64 : 0) / 10) * 10000)) / 1000) % 10 + (((((DEFINED(ape_loader_end) ? (((ape_loader_end - ape_loader) + (CONSTANT(COMMONPAGESIZE))-1) & -(CONSTANT(COMMONPAGESIZE))) / 64 : 0) / 10) + ((DEFINED(ape_loader_end) ? (((ape_loader_end - ape_loader) + (CONSTANT(COMMONPAGESIZE))-1) & -(CONSTANT(COMMONPAGESIZE))) / 64 : 0) / 10) * 10000)) / 100) % 10 * 0x100 + (((((DEFINED(ape_loader_end) ? (((ape_loader_end - ape_loader) + (CONSTANT(COMMONPAGESIZE))-1) & -(CONSTANT(COMMONPAGESIZE))) / 64 : 0) / 10) + ((DEFINED(ape_loader_end) ? (((ape_loader_end - ape_loader) + (CONSTANT(COMMONPAGESIZE))-1) & -(CONSTANT(COMMONPAGESIZE))) / 64 : 0) / 10) * 10000)) / 10) % 10 * 0x10000 + ((((DEFINED(ape_loader_end) ? (((ape_loader_end - ape_loader) + (CONSTANT(COMMONPAGESIZE))-1) & -(CONSTANT(COMMONPAGESIZE))) / 64 : 0) / 10) + ((DEFINED(ape_loader_end) ? (((ape_loader_end - ape_loader) + (CONSTANT(COMMONPAGESIZE))-1) & -(CONSTANT(COMMONPAGESIZE))) / 64 : 0) / 10) * 10000)) % 10 * 0x1000000 : 0xffffffffffffffff) : (DEFINED(ape_loader_end) ? (((ape_loader_end - ape_loader) + (CONSTANT(COMMONPAGESIZE))-1) & -(CONSTANT(COMMONPAGESIZE))) / 64 : 0) < 1000000 ? ((((((DEFINED(ape_loader_end) ? (((ape_loader_end - ape_loader) + (CONSTANT(COMMONPAGESIZE))-1) & -(CONSTANT(COMMONPAGESIZE))) / 64 : 0) / 100) + ((DEFINED(ape_loader_end) ? (((ape_loader_end - ape_loader) + (CONSTANT(COMMONPAGESIZE))-1) & -(CONSTANT(COMMONPAGESIZE))) / 64 : 0) / 100) * 10000))) < 10000 ? 0x20202020 : ((((DEFINED(ape_loader_end) ? (((ape_loader_end - ape_loader) + (CONSTANT(COMMONPAGESIZE))-1) & -(CONSTANT(COMMONPAGESIZE))) / 64 : 0) / 100) + ((DEFINED(ape_loader_end) ? (((ape_loader_end - ape_loader) + (CONSTANT(COMMONPAGESIZE))-1) & -(CONSTANT(COMMONPAGESIZE))) / 64 : 0) / 100) * 10000)) < 100000 ? 0x20202030 + ((((DEFINED(ape_loader_end) ? (((ape_loader_end - ape_loader) + (CONSTANT(COMMONPAGESIZE))-1) & -(CONSTANT(COMMONPAGESIZE))) / 64 : 0) / 100) + ((DEFINED(ape_loader_end) ? (((ape_loader_end - ape_loader) + (CONSTANT(COMMONPAGESIZE))-1) & -(CONSTANT(COMMONPAGESIZE))) / 64 : 0) / 100) * 10000)) % 10 : ((((DEFINED(ape_loader_end) ? (((ape_loader_end - ape_loader) + (CONSTANT(COMMONPAGESIZE))-1) & -(CONSTANT(COMMONPAGESIZE))) / 64 : 0) / 100) + ((DEFINED(ape_loader_end) ? (((ape_loader_end - ape_loader) + (CONSTANT(COMMONPAGESIZE))-1) & -(CONSTANT(COMMONPAGESIZE))) / 64 : 0) / 100) * 10000)) < 1000000 ? 0x20203030 + (((((DEFINED(ape_loader_end) ? (((ape_loader_end - ape_loader) + (CONSTANT(COMMONPAGESIZE))-1) & -(CONSTANT(COMMONPAGESIZE))) / 64 : 0) / 100) + ((DEFINED(ape_loader_end) ? (((ape_loader_end - ape_loader) + (CONSTANT(COMMONPAGESIZE))-1) & -(CONSTANT(COMMONPAGESIZE))) / 64 : 0) / 100) * 10000)) / 10) % 10 + ((((DEFINED(ape_loader_end) ? (((ape_loader_end - ape_loader) + (CONSTANT(COMMONPAGESIZE))-1) & -(CONSTANT(COMMONPAGESIZE))) / 64 : 0) / 100) + ((DEFINED(ape_loader_end) ? (((ape_loader_end - ape_loader) + (CONSTANT(COMMONPAGESIZE))-1) & -(CONSTANT(COMMONPAGESIZE))) / 64 : 0) / 100) * 10000)) % 10 * 0x100 : ((((DEFINED(ape_loader_end) ? (((ape_loader_end - ape_loader) + (CONSTANT(COMMONPAGESIZE))-1) & -(CONSTANT(COMMONPAGESIZE))) / 64 : 0) / 100) + ((DEFINED(ape_loader_end) ? (((ape_loader_end - ape_loader) + (CONSTANT(COMMONPAGESIZE))-1) & -(CONSTANT(COMMONPAGESIZE))) / 64 : 0) / 100) * 10000)) < 10000000 ? 0x20303030 + (((((DEFINED(ape_loader_end) ? (((ape_loader_end - ape_loader) + (CONSTANT(COMMONPAGESIZE))-1) & -(CONSTANT(COMMONPAGESIZE))) / 64 : 0) / 100) + ((DEFINED(ape_loader_end) ? (((ape_loader_end - ape_loader) + (CONSTANT(COMMONPAGESIZE))-1) & -(CONSTANT(COMMONPAGESIZE))) / 64 : 0) / 100) * 10000)) / 100) % 10 + (((((DEFINED(ape_loader_end) ? (((ape_loader_end - ape_loader) + (CONSTANT(COMMONPAGESIZE))-1) & -(CONSTANT(COMMONPAGESIZE))) / 64 : 0) / 100) + ((DEFINED(ape_loader_end) ? (((ape_loader_end - ape_loader) + (CONSTANT(COMMONPAGESIZE))-1) & -(CONSTANT(COMMONPAGESIZE))) / 64 : 0) / 100) * 10000)) / 10) % 10 * 0x100 + ((((DEFINED(ape_loader_end) ? (((ape_loader_end - ape_loader) + (CONSTANT(COMMONPAGESIZE))-1) & -(CONSTANT(COMMONPAGESIZE))) / 64 : 0) / 100) + ((DEFINED(ape_loader_end) ? (((ape_loader_end - ape_loader) + (CONSTANT(COMMONPAGESIZE))-1) & -(CONSTANT(COMMONPAGESIZE))) / 64 : 0) / 100) * 10000)) % 10 * 0x10000 : ((((DEFINED(ape_loader_end) ? (((ape_loader_end - ape_loader) + (CONSTANT(COMMONPAGESIZE))-1) & -(CONSTANT(COMMONPAGESIZE))) / 64 : 0) / 100) + ((DEFINED(ape_loader_end) ? (((ape_loader_end - ape_loader) + (CONSTANT(COMMONPAGESIZE))-1) & -(CONSTANT(COMMONPAGESIZE))) / 64 : 0) / 100) * 10000)) < 100000000 ? 0x30303030 + (((((DEFINED(ape_loader_end) ? (((ape_loader_end - ape_loader) + (CONSTANT(COMMONPAGESIZE))-1) & -(CONSTANT(COMMONPAGESIZE))) / 64 : 0) / 100) + ((DEFINED(ape_loader_end) ? (((ape_loader_end - ape_loader) + (CONSTANT(COMMONPAGESIZE))-1) & -(CONSTANT(COMMONPAGESIZE))) / 64 : 0) / 100) * 10000)) / 1000) % 10 + (((((DEFINED(ape_loader_end) ? (((ape_loader_end - ape_loader) + (CONSTANT(COMMONPAGESIZE))-1) & -(CONSTANT(COMMONPAGESIZE))) / 64 : 0) / 100) + ((DEFINED(ape_loader_end) ? (((ape_loader_end - ape_loader) + (CONSTANT(COMMONPAGESIZE))-1) & -(CONSTANT(COMMONPAGESIZE))) / 64 : 0) / 100) * 10000)) / 100) % 10 * 0x100 + (((((DEFINED(ape_loader_end) ? (((ape_loader_end - ape_loader) + (CONSTANT(COMMONPAGESIZE))-1) & -(CONSTANT(COMMONPAGESIZE))) / 64 : 0) / 100) + ((DEFINED(ape_loader_end) ? (((ape_loader_end - ape_loader) + (CONSTANT(COMMONPAGESIZE))-1) & -(CONSTANT(COMMONPAGESIZE))) / 64 : 0) / 100) * 10000)) / 10) % 10 * 0x10000 + ((((DEFINED(ape_loader_end) ? (((ape_loader_end - ape_loader) + (CONSTANT(COMMONPAGESIZE))-1) & -(CONSTANT(COMMONPAGESIZE))) / 64 : 0) / 100) + ((DEFINED(ape_loader_end) ? (((ape_loader_end - ape_loader) + (CONSTANT(COMMONPAGESIZE))-1) & -(CONSTANT(COMMONPAGESIZE))) / 64 : 0) / 100) * 10000)) % 10 * 0x1000000 : 0xffffffffffffffff) : (DEFINED(ape_loader_end) ? (((ape_loader_end - ape_loader) + (CONSTANT(COMMONPAGESIZE))-1) & -(CONSTANT(COMMONPAGESIZE))) / 64 : 0) < 10000000 ? ((((((DEFINED(ape_loader_end) ? (((ape_loader_end - ape_loader) + (CONSTANT(COMMONPAGESIZE))-1) & -(CONSTANT(COMMONPAGESIZE))) / 64 : 0) / 1000) + ((DEFINED(ape_loader_end) ? (((ape_loader_end - ape_loader) + (CONSTANT(COMMONPAGESIZE))-1) & -(CONSTANT(COMMONPAGESIZE))) / 64 : 0) / 1000) * 10000))) < 10000 ? 0x20202020 : ((((DEFINED(ape_loader_end) ? (((ape_loader_end - ape_loader) + (CONSTANT(COMMONPAGESIZE))-1) & -(CONSTANT(COMMONPAGESIZE))) / 64 : 0) / 1000) + ((DEFINED(ape_loader_end) ? (((ape_loader_end - ape_loader) + (CONSTANT(COMMONPAGESIZE))-1) & -(CONSTANT(COMMONPAGESIZE))) / 64 : 0) / 1000) * 10000)) < 100000 ? 0x20202030 + ((((DEFINED(ape_loader_end) ? (((ape_loader_end - ape_loader) + (CONSTANT(COMMONPAGESIZE))-1) & -(CONSTANT(COMMONPAGESIZE))) / 64 : 0) / 1000) + ((DEFINED(ape_loader_end) ? (((ape_loader_end - ape_loader) + (CONSTANT(COMMONPAGESIZE))-1) & -(CONSTANT(COMMONPAGESIZE))) / 64 : 0) / 1000) * 10000)) % 10 : ((((DEFINED(ape_loader_end) ? (((ape_loader_end - ape_loader) + (CONSTANT(COMMONPAGESIZE))-1) & -(CONSTANT(COMMONPAGESIZE))) / 64 : 0) / 1000) + ((DEFINED(ape_loader_end) ? (((ape_loader_end - ape_loader) + (CONSTANT(COMMONPAGESIZE))-1) & -(CONSTANT(COMMONPAGESIZE))) / 64 : 0) / 1000) * 10000)) < 1000000 ? 0x20203030 + (((((DEFINED(ape_loader_end) ? (((ape_loader_end - ape_loader) + (CONSTANT(COMMONPAGESIZE))-1) & -(CONSTANT(COMMONPAGESIZE))) / 64 : 0) / 1000) + ((DEFINED(ape_loader_end) ? (((ape_loader_end - ape_loader) + (CONSTANT(COMMONPAGESIZE))-1) & -(CONSTANT(COMMONPAGESIZE))) / 64 : 0) / 1000) * 10000)) / 10) % 10 + ((((DEFINED(ape_loader_end) ? (((ape_loader_end - ape_loader) + (CONSTANT(COMMONPAGESIZE))-1) & -(CONSTANT(COMMONPAGESIZE))) / 64 : 0) / 1000) + ((DEFINED(ape_loader_end) ? (((ape_loader_end - ape_loader) + (CONSTANT(COMMONPAGESIZE))-1) & -(CONSTANT(COMMONPAGESIZE))) / 64 : 0) / 1000) * 10000)) % 10 * 0x100 : ((((DEFINED(ape_loader_end) ? (((ape_loader_end - ape_loader) + (CONSTANT(COMMONPAGESIZE))-1) & -(CONSTANT(COMMONPAGESIZE))) / 64 : 0) / 1000) + ((DEFINED(ape_loader_end) ? (((ape_loader_end - ape_loader) + (CONSTANT(COMMONPAGESIZE))-1) & -(CONSTANT(COMMONPAGESIZE))) / 64 : 0) / 1000) * 10000)) < 10000000 ? 0x20303030 + (((((DEFINED(ape_loader_end) ? (((ape_loader_end - ape_loader) + (CONSTANT(COMMONPAGESIZE))-1) & -(CONSTANT(COMMONPAGESIZE))) / 64 : 0) / 1000) + ((DEFINED(ape_loader_end) ? (((ape_loader_end - ape_loader) + (CONSTANT(COMMONPAGESIZE))-1) & -(CONSTANT(COMMONPAGESIZE))) / 64 : 0) / 1000) * 10000)) / 100) % 10 + (((((DEFINED(ape_loader_end) ? (((ape_loader_end - ape_loader) + (CONSTANT(COMMONPAGESIZE))-1) & -(CONSTANT(COMMONPAGESIZE))) / 64 : 0) / 1000) + ((DEFINED(ape_loader_end) ? (((ape_loader_end - ape_loader) + (CONSTANT(COMMONPAGESIZE))-1) & -(CONSTANT(COMMONPAGESIZE))) / 64 : 0) / 1000) * 10000)) / 10) % 10 * 0x100 + ((((DEFINED(ape_loader_end) ? (((ape_loader_end - ape_loader) + (CONSTANT(COMMONPAGESIZE))-1) & -(CONSTANT(COMMONPAGESIZE))) / 64 : 0) / 1000) + ((DEFINED(ape_loader_end) ? (((ape_loader_end - ape_loader) + (CONSTANT(COMMONPAGESIZE))-1) & -(CONSTANT(COMMONPAGESIZE))) / 64 : 0) / 1000) * 10000)) % 10 * 0x10000 : ((((DEFINED(ape_loader_end) ? (((ape_loader_end - ape_loader) + (CONSTANT(COMMONPAGESIZE))-1) & -(CONSTANT(COMMONPAGESIZE))) / 64 : 0) / 1000) + ((DEFINED(ape_loader_end) ? (((ape_loader_end - ape_loader) + (CONSTANT(COMMONPAGESIZE))-1) & -(CONSTANT(COMMONPAGESIZE))) / 64 : 0) / 1000) * 10000)) < 100000000 ? 0x30303030 + (((((DEFINED(ape_loader_end) ? (((ape_loader_end - ape_loader) + (CONSTANT(COMMONPAGESIZE))-1) & -(CONSTANT(COMMONPAGESIZE))) / 64 : 0) / 1000) + ((DEFINED(ape_loader_end) ? (((ape_loader_end - ape_loader) + (CONSTANT(COMMONPAGESIZE))-1) & -(CONSTANT(COMMONPAGESIZE))) / 64 : 0) / 1000) * 10000)) / 1000) % 10 + (((((DEFINED(ape_loader_end) ? (((ape_loader_end - ape_loader) + (CONSTANT(COMMONPAGESIZE))-1) & -(CONSTANT(COMMONPAGESIZE))) / 64 : 0) / 1000) + ((DEFINED(ape_loader_end) ? (((ape_loader_end - ape_loader) + (CONSTANT(COMMONPAGESIZE))-1) & -(CONSTANT(COMMONPAGESIZE))) / 64 : 0) / 1000) * 10000)) / 100) % 10 * 0x100 + (((((DEFINED(ape_loader_end) ? (((ape_loader_end - ape_loader) + (CONSTANT(COMMONPAGESIZE))-1) & -(CONSTANT(COMMONPAGESIZE))) / 64 : 0) / 1000) + ((DEFINED(ape_loader_end) ? (((ape_loader_end - ape_loader) + (CONSTANT(COMMONPAGESIZE))-1) & -(CONSTANT(COMMONPAGESIZE))) / 64 : 0) / 1000) * 10000)) / 10) % 10 * 0x10000 + ((((DEFINED(ape_loader_end) ? (((ape_loader_end - ape_loader) + (CONSTANT(COMMONPAGESIZE))-1) & -(CONSTANT(COMMONPAGESIZE))) / 64 : 0) / 1000) + ((DEFINED(ape_loader_end) ? (((ape_loader_end - ape_loader) + (CONSTANT(COMMONPAGESIZE))-1) & -(CONSTANT(COMMONPAGESIZE))) / 64 : 0) / 1000) * 10000)) % 10 * 0x1000000 : 0xffffffffffffffff) : (DEFINED(ape_loader_end) ? (((ape_loader_end - ape_loader) + (CONSTANT(COMMONPAGESIZE))-1) & -(CONSTANT(COMMONPAGESIZE))) / 64 : 0) < 100000000 ? ((((((DEFINED(ape_loader_end) ? (((ape_loader_end - ape_loader) + (CONSTANT(COMMONPAGESIZE))-1) & -(CONSTANT(COMMONPAGESIZE))) / 64 : 0) / 10000) + ((DEFINED(ape_loader_end) ? (((ape_loader_end - ape_loader) + (CONSTANT(COMMONPAGESIZE))-1) & -(CONSTANT(COMMONPAGESIZE))) / 64 : 0) / 10000) * 10000))) < 10000 ? 0x20202020 : ((((DEFINED(ape_loader_end) ? (((ape_loader_end - ape_loader) + (CONSTANT(COMMONPAGESIZE))-1) & -(CONSTANT(COMMONPAGESIZE))) / 64 : 0) / 10000) + ((DEFINED(ape_loader_end) ? (((ape_loader_end - ape_loader) + (CONSTANT(COMMONPAGESIZE))-1) & -(CONSTANT(COMMONPAGESIZE))) / 64 : 0) / 10000) * 10000)) < 100000 ? 0x20202030 + ((((DEFINED(ape_loader_end) ? (((ape_loader_end - ape_loader) + (CONSTANT(COMMONPAGESIZE))-1) & -(CONSTANT(COMMONPAGESIZE))) / 64 : 0) / 10000) + ((DEFINED(ape_loader_end) ? (((ape_loader_end - ape_loader) + (CONSTANT(COMMONPAGESIZE))-1) & -(CONSTANT(COMMONPAGESIZE))) / 64 : 0) / 10000) * 10000)) % 10 : ((((DEFINED(ape_loader_end) ? (((ape_loader_end - ape_loader) + (CONSTANT(COMMONPAGESIZE))-1) & -(CONSTANT(COMMONPAGESIZE))) / 64 : 0) / 10000) + ((DEFINED(ape_loader_end) ? (((ape_loader_end - ape_loader) + (CONSTANT(COMMONPAGESIZE))-1) & -(CONSTANT(COMMONPAGESIZE))) / 64 : 0) / 10000) * 10000)) < 1000000 ? 0x20203030 + (((((DEFINED(ape_loader_end) ? (((ape_loader_end - ape_loader) + (CONSTANT(COMMONPAGESIZE))-1) & -(CONSTANT(COMMONPAGESIZE))) / 64 : 0) / 10000) + ((DEFINED(ape_loader_end) ? (((ape_loader_end - ape_loader) + (CONSTANT(COMMONPAGESIZE))-1) & -(CONSTANT(COMMONPAGESIZE))) / 64 : 0) / 10000) * 10000)) / 10) % 10 + ((((DEFINED(ape_loader_end) ? (((ape_loader_end - ape_loader) + (CONSTANT(COMMONPAGESIZE))-1) & -(CONSTANT(COMMONPAGESIZE))) / 64 : 0) / 10000) + ((DEFINED(ape_loader_end) ? (((ape_loader_end - ape_loader) + (CONSTANT(COMMONPAGESIZE))-1) & -(CONSTANT(COMMONPAGESIZE))) / 64 : 0) / 10000) * 10000)) % 10 * 0x100 : ((((DEFINED(ape_loader_end) ? (((ape_loader_end - ape_loader) + (CONSTANT(COMMONPAGESIZE))-1) & -(CONSTANT(COMMONPAGESIZE))) / 64 : 0) / 10000) + ((DEFINED(ape_loader_end) ? (((ape_loader_end - ape_loader) + (CONSTANT(COMMONPAGESIZE))-1) & -(CONSTANT(COMMONPAGESIZE))) / 64 : 0) / 10000) * 10000)) < 10000000 ? 0x20303030 + (((((DEFINED(ape_loader_end) ? (((ape_loader_end - ape_loader) + (CONSTANT(COMMONPAGESIZE))-1) & -(CONSTANT(COMMONPAGESIZE))) / 64 : 0) / 10000) + ((DEFINED(ape_loader_end) ? (((ape_loader_end - ape_loader) + (CONSTANT(COMMONPAGESIZE))-1) & -(CONSTANT(COMMONPAGESIZE))) / 64 : 0) / 10000) * 10000)) / 100) % 10 + (((((DEFINED(ape_loader_end) ? (((ape_loader_end - ape_loader) + (CONSTANT(COMMONPAGESIZE))-1) & -(CONSTANT(COMMONPAGESIZE))) / 64 : 0) / 10000) + ((DEFINED(ape_loader_end) ? (((ape_loader_end - ape_loader) + (CONSTANT(COMMONPAGESIZE))-1) & -(CONSTANT(COMMONPAGESIZE))) / 64 : 0) / 10000) * 10000)) / 10) % 10 * 0x100 + ((((DEFINED(ape_loader_end) ? (((ape_loader_end - ape_loader) + (CONSTANT(COMMONPAGESIZE))-1) & -(CONSTANT(COMMONPAGESIZE))) / 64 : 0) / 10000) + ((DEFINED(ape_loader_end) ? (((ape_loader_end - ape_loader) + (CONSTANT(COMMONPAGESIZE))-1) & -(CONSTANT(COMMONPAGESIZE))) / 64 : 0) / 10000) * 10000)) % 10 * 0x10000 : ((((DEFINED(ape_loader_end) ? (((ape_loader_end - ape_loader) + (CONSTANT(COMMONPAGESIZE))-1) & -(CONSTANT(COMMONPAGESIZE))) / 64 : 0) / 10000) + ((DEFINED(ape_loader_end) ? (((ape_loader_end - ape_loader) + (CONSTANT(COMMONPAGESIZE))-1) & -(CONSTANT(COMMONPAGESIZE))) / 64 : 0) / 10000) * 10000)) < 100000000 ? 0x30303030 + (((((DEFINED(ape_loader_end) ? (((ape_loader_end - ape_loader) + (CONSTANT(COMMONPAGESIZE))-1) & -(CONSTANT(COMMONPAGESIZE))) / 64 : 0) / 10000) + ((DEFINED(ape_loader_end) ? (((ape_loader_end - ape_loader) + (CONSTANT(COMMONPAGESIZE))-1) & -(CONSTANT(COMMONPAGESIZE))) / 64 : 0) / 10000) * 10000)) / 1000) % 10 + (((((DEFINED(ape_loader_end) ? (((ape_loader_end - ape_loader) + (CONSTANT(COMMONPAGESIZE))-1) & -(CONSTANT(COMMONPAGESIZE))) / 64 : 0) / 10000) + ((DEFINED(ape_loader_end) ? (((ape_loader_end - ape_loader) + (CONSTANT(COMMONPAGESIZE))-1) & -(CONSTANT(COMMONPAGESIZE))) / 64 : 0) / 10000) * 10000)) / 100) % 10 * 0x100 + (((((DEFINED(ape_loader_end) ? (((ape_loader_end - ape_loader) + (CONSTANT(COMMONPAGESIZE))-1) & -(CONSTANT(COMMONPAGESIZE))) / 64 : 0) / 10000) + ((DEFINED(ape_loader_end) ? (((ape_loader_end - ape_loader) + (CONSTANT(COMMONPAGESIZE))-1) & -(CONSTANT(COMMONPAGESIZE))) / 64 : 0) / 10000) * 10000)) / 10) % 10 * 0x10000 + ((((DEFINED(ape_loader_end) ? (((ape_loader_end - ape_loader) + (CONSTANT(COMMONPAGESIZE))-1) & -(CONSTANT(COMMONPAGESIZE))) / 64 : 0) / 10000) + ((DEFINED(ape_loader_end) ? (((ape_loader_end - ape_loader) + (CONSTANT(COMMONPAGESIZE))-1) & -(CONSTANT(COMMONPAGESIZE))) / 64 : 0) / 10000) * 10000)) % 10 * 0x1000000 : 0xffffffffffffffff) : 0xffffffffffffffff)); HIDDEN(ape_loader_dd_count_bcs1 = (((DEFINED(ape_loader_end) ? (((ape_loader_end - ape_loader) + (CONSTANT(COMMONPAGESIZE))-1) & -(CONSTANT(COMMONPAGESIZE))) / 64 : 0)) < 10000 ? 0x20202020 : (DEFINED(ape_loader_end) ? (((ape_loader_end - ape_loader) + (CONSTANT(COMMONPAGESIZE))-1) & -(CONSTANT(COMMONPAGESIZE))) / 64 : 0) < 100000 ? 0x20202030 + (DEFINED(ape_loader_end) ? (((ape_loader_end - ape_loader) + (CONSTANT(COMMONPAGESIZE))-1) & -(CONSTANT(COMMONPAGESIZE))) / 64 : 0) % 10 : (DEFINED(ape_loader_end) ? (((ape_loader_end - ape_loader) + (CONSTANT(COMMONPAGESIZE))-1) & -(CONSTANT(COMMONPAGESIZE))) / 64 : 0) < 1000000 ? 0x20203030 + ((DEFINED(ape_loader_end) ? (((ape_loader_end - ape_loader) + (CONSTANT(COMMONPAGESIZE))-1) & -(CONSTANT(COMMONPAGESIZE))) / 64 : 0) / 10) % 10 + (DEFINED(ape_loader_end) ? (((ape_loader_end - ape_loader) + (CONSTANT(COMMONPAGESIZE))-1) & -(CONSTANT(COMMONPAGESIZE))) / 64 : 0) % 10 * 0x100 : (DEFINED(ape_loader_end) ? (((ape_loader_end - ape_loader) + (CONSTANT(COMMONPAGESIZE))-1) & -(CONSTANT(COMMONPAGESIZE))) / 64 : 0) < 10000000 ? 0x20303030 + ((DEFINED(ape_loader_end) ? (((ape_loader_end - ape_loader) + (CONSTANT(COMMONPAGESIZE))-1) & -(CONSTANT(COMMONPAGESIZE))) / 64 : 0) / 100) % 10 + ((DEFINED(ape_loader_end) ? (((ape_loader_end - ape_loader) + (CONSTANT(COMMONPAGESIZE))-1) & -(CONSTANT(COMMONPAGESIZE))) / 64 : 0) / 10) % 10 * 0x100 + (DEFINED(ape_loader_end) ? (((ape_loader_end - ape_loader) + (CONSTANT(COMMONPAGESIZE))-1) & -(CONSTANT(COMMONPAGESIZE))) / 64 : 0) % 10 * 0x10000 : (DEFINED(ape_loader_end) ? (((ape_loader_end - ape_loader) + (CONSTANT(COMMONPAGESIZE))-1) & -(CONSTANT(COMMONPAGESIZE))) / 64 : 0) < 100000000 ? 0x30303030 + ((DEFINED(ape_loader_end) ? (((ape_loader_end - ape_loader) + (CONSTANT(COMMONPAGESIZE))-1) & -(CONSTANT(COMMONPAGESIZE))) / 64 : 0) / 1000) % 10 + ((DEFINED(ape_loader_end) ? (((ape_loader_end - ape_loader) + (CONSTANT(COMMONPAGESIZE))-1) & -(CONSTANT(COMMONPAGESIZE))) / 64 : 0) / 100) % 10 * 0x100 + ((DEFINED(ape_loader_end) ? (((ape_loader_end - ape_loader) + (CONSTANT(COMMONPAGESIZE))-1) & -(CONSTANT(COMMONPAGESIZE))) / 64 : 0) / 10) % 10 * 0x10000 + (DEFINED(ape_loader_end) ? (((ape_loader_end - ape_loader) + (CONSTANT(COMMONPAGESIZE))-1) & -(CONSTANT(COMMONPAGESIZE))) / 64 : 0) % 10 * 0x1000000 : 0xffffffffffffffff));
blink_linux_aarch64_quad = DEFINED(blink_linux_aarch64) ? ((((blink_linux_aarch64) - (0x400000)) < 1000000000 ? 32 : ((blink_linux_aarch64) - (0x400000)) / 1000000000 % 10 + 48) << 000 | (((blink_linux_aarch64) - (0x400000)) < 100000000 ? 32 : ((blink_linux_aarch64) - (0x400000)) / 100000000 % 10 + 48) << 010 | (((blink_linux_aarch64) - (0x400000)) < 10000000 ? 32 : ((blink_linux_aarch64) - (0x400000)) / 10000000 % 10 + 48) << 020 | (((blink_linux_aarch64) - (0x400000)) < 1000000 ? 32 : ((blink_linux_aarch64) - (0x400000)) / 1000000 % 10 + 48) << 030 | (((blink_linux_aarch64) - (0x400000)) < 100000 ? 32 : ((blink_linux_aarch64) - (0x400000)) / 100000 % 10 + 48) << 040 | (((blink_linux_aarch64) - (0x400000)) < 10000 ? 32 : ((blink_linux_aarch64) - (0x400000)) / 10000 % 10 + 48) << 050 | (((blink_linux_aarch64) - (0x400000)) < 1000 ? 32 : ((blink_linux_aarch64) - (0x400000)) / 1000 % 10 + 48) << 060 | (((blink_linux_aarch64) - (0x400000)) < 100 ? 32 : ((blink_linux_aarch64) - (0x400000)) / 100 % 10 + 48) << 070) : 0; blink_linux_aarch64_short = DEFINED(blink_linux_aarch64) ? ((((blink_linux_aarch64) - (0x400000)) < 10 ? 32 : ((blink_linux_aarch64) - (0x400000)) / 10 % 10 + 48) << 000 | (((blink_linux_aarch64) - (0x400000)) % 10 + 48) << 010) : 0;
blink_linux_aarch64_size_quad = DEFINED(blink_linux_aarch64_size) ? ((blink_linux_aarch64_size < 1000000000 ? 32 : blink_linux_aarch64_size / 1000000000 % 10 + 48) << 000 | (blink_linux_aarch64_size < 100000000 ? 32 : blink_linux_aarch64_size / 100000000 % 10 + 48) << 010 | (blink_linux_aarch64_size < 10000000 ? 32 : blink_linux_aarch64_size / 10000000 % 10 + 48) << 020 | (blink_linux_aarch64_size < 1000000 ? 32 : blink_linux_aarch64_size / 1000000 % 10 + 48) << 030 | (blink_linux_aarch64_size < 100000 ? 32 : blink_linux_aarch64_size / 100000 % 10 + 48) << 040 | (blink_linux_aarch64_size < 10000 ? 32 : blink_linux_aarch64_size / 10000 % 10 + 48) << 050 | (blink_linux_aarch64_size < 1000 ? 32 : blink_linux_aarch64_size / 1000 % 10 + 48) << 060 | (blink_linux_aarch64_size < 100 ? 32 : blink_linux_aarch64_size / 100 % 10 + 48) << 070) : 0; blink_linux_aarch64_size_short = DEFINED(blink_linux_aarch64_size) ? ((blink_linux_aarch64_size < 10 ? 32 : blink_linux_aarch64_size / 10 % 10 + 48) << 000 | (blink_linux_aarch64_size % 10 + 48) << 010) : 0;
blink_xnu_aarch64_quad = DEFINED(blink_xnu_aarch64) ? ((((blink_xnu_aarch64) - (0x400000)) < 1000000000 ? 32 : ((blink_xnu_aarch64) - (0x400000)) / 1000000000 % 10 + 48) << 000 | (((blink_xnu_aarch64) - (0x400000)) < 100000000 ? 32 : ((blink_xnu_aarch64) - (0x400000)) / 100000000 % 10 + 48) << 010 | (((blink_xnu_aarch64) - (0x400000)) < 10000000 ? 32 : ((blink_xnu_aarch64) - (0x400000)) / 10000000 % 10 + 48) << 020 | (((blink_xnu_aarch64) - (0x400000)) < 1000000 ? 32 : ((blink_xnu_aarch64) - (0x400000)) / 1000000 % 10 + 48) << 030 | (((blink_xnu_aarch64) - (0x400000)) < 100000 ? 32 : ((blink_xnu_aarch64) - (0x400000)) / 100000 % 10 + 48) << 040 | (((blink_xnu_aarch64) - (0x400000)) < 10000 ? 32 : ((blink_xnu_aarch64) - (0x400000)) / 10000 % 10 + 48) << 050 | (((blink_xnu_aarch64) - (0x400000)) < 1000 ? 32 : ((blink_xnu_aarch64) - (0x400000)) / 1000 % 10 + 48) << 060 | (((blink_xnu_aarch64) - (0x400000)) < 100 ? 32 : ((blink_xnu_aarch64) - (0x400000)) / 100 % 10 + 48) << 070) : 0; blink_xnu_aarch64_short = DEFINED(blink_xnu_aarch64) ? ((((blink_xnu_aarch64) - (0x400000)) < 10 ? 32 : ((blink_xnu_aarch64) - (0x400000)) / 10 % 10 + 48) << 000 | (((blink_xnu_aarch64) - (0x400000)) % 10 + 48) << 010) : 0;
blink_xnu_aarch64_size_quad = DEFINED(blink_xnu_aarch64_size) ? ((blink_xnu_aarch64_size < 1000000000 ? 32 : blink_xnu_aarch64_size / 1000000000 % 10 + 48) << 000 | (blink_xnu_aarch64_size < 100000000 ? 32 : blink_xnu_aarch64_size / 100000000 % 10 + 48) << 010 | (blink_xnu_aarch64_size < 10000000 ? 32 : blink_xnu_aarch64_size / 10000000 % 10 + 48) << 020 | (blink_xnu_aarch64_size < 1000000 ? 32 : blink_xnu_aarch64_size / 1000000 % 10 + 48) << 030 | (blink_xnu_aarch64_size < 100000 ? 32 : blink_xnu_aarch64_size / 100000 % 10 + 48) << 040 | (blink_xnu_aarch64_size < 10000 ? 32 : blink_xnu_aarch64_size / 10000 % 10 + 48) << 050 | (blink_xnu_aarch64_size < 1000 ? 32 : blink_xnu_aarch64_size / 1000 % 10 + 48) << 060 | (blink_xnu_aarch64_size < 100 ? 32 : blink_xnu_aarch64_size / 100 % 10 + 48) << 070) : 0; blink_xnu_aarch64_size_short = DEFINED(blink_xnu_aarch64_size) ? ((blink_xnu_aarch64_size < 10 ? 32 : blink_xnu_aarch64_size / 10 % 10 + 48) << 000 | (blink_xnu_aarch64_size % 10 + 48) << 010) : 0;
v_ape_realsectors = (((((((_ezip) - (0x400000))) + (512)-1) & -(512))) > (0x70000 - 0x2000) ? (0x70000 - 0x2000) : ((((((_ezip) - (0x400000))) + (512)-1) & -(512)))) / 512;
v_ape_realbytes = v_ape_realsectors * 512;
v_ape_realdwords = v_ape_realsectors * (512 / 4);
v_ape_allsectors = (((((_ezip) - (0x400000))) + (512)-1) & -(512)) / 512;
v_ape_allbytes = v_ape_allsectors * 512;
v_ape_highsectors = ((v_ape_allsectors - v_ape_realsectors) > (0xffff) ? (0xffff) : (v_ape_allsectors - v_ape_realsectors));
HIDDEN(_tss_desc_ent0 = (((_tss_end ? _tss_end - _tss - 1 : 0) << 0 & 0x000000000000ffff) | ((_tss) << 16 & 0x000000ffffff0000) | 0x89 << 40 | ((_tss_end ? _tss_end - _tss - 1 : 0) >> 16 << 48 & 0x000f000000000000) | 0x2 << 52 | ((_tss) >> 24 << 56 & 0xff00000000000000))); HIDDEN(_tss_desc_ent1 = ((_tss) >> 32 << 0 & 0x00000000ffffffff)); ASSERT((_tss_end ? _tss_end - _tss - 1 : 0) >= 0 && (_tss_end ? _tss_end - _tss - 1 : 0) <= 0xffff, "bare metal TSS is suspiciously fat");
ape_uuid1 = 88172645463325252;
ape_uuid2 = 88172645463325252;
ape_uuid1 = ((ape_uuid1 | (ape_elf_entry >> 12)) - (ape_uuid1 & (ape_elf_entry >> 12))); ape_uuid1 = ((ape_uuid1 | (ape_elf_entry << 25)) - (ape_uuid1 & (ape_elf_entry << 25))); ape_uuid1 = ((ape_uuid1 | (ape_elf_entry >> 27)) - (ape_uuid1 & (ape_elf_entry >> 27))); ape_uuid1 = (ape_uuid1 + (ape_elf_entry >> 000) & 0xFF) * 0x9e3779b9925d4c17; ape_uuid1 = (ape_uuid1 + (ape_elf_entry >> 010) & 0xFF) * 0x9e3779b9925d4c17; ape_uuid1 = (ape_uuid1 + (ape_elf_entry >> 020) & 0xFF) * 0x9e3779b9925d4c17; ape_uuid1 = (ape_uuid1 + (ape_elf_entry >> 030) & 0xFF) * 0x9e3779b9925d4c17; ape_uuid2 = ((ape_uuid2 | (ape_elf_entry >> 12)) - (ape_uuid2 & (ape_elf_entry >> 12))); ape_uuid2 = ((ape_uuid2 | (ape_elf_entry << 25)) - (ape_uuid2 & (ape_elf_entry << 25))); ape_uuid2 = ((ape_uuid2 | (ape_elf_entry >> 27)) - (ape_uuid2 & (ape_elf_entry >> 27))); ape_uuid2 = (ape_uuid2 + (ape_elf_entry >> 000) & 0xFF) * 0x9e3779b9925d4c17; ape_uuid2 = (ape_uuid2 + (ape_elf_entry >> 010) & 0xFF) * 0x9e3779b9925d4c17; ape_uuid2 = (ape_uuid2 + (ape_elf_entry >> 020) & 0xFF) * 0x9e3779b9925d4c17; ape_uuid2 = (ape_uuid2 + (ape_elf_entry >> 030) & 0xFF) * 0x9e3779b9925d4c17;
ape_uuid1 = ((ape_uuid1 | (ape_elf_phnum >> 12)) - (ape_uuid1 & (ape_elf_phnum >> 12))); ape_uuid1 = ((ape_uuid1 | (ape_elf_phnum << 25)) - (ape_uuid1 & (ape_elf_phnum << 25))); ape_uuid1 = ((ape_uuid1 | (ape_elf_phnum >> 27)) - (ape_uuid1 & (ape_elf_phnum >> 27))); ape_uuid1 = (ape_uuid1 + (ape_elf_phnum >> 000) & 0xFF) * 0x9e3779b9925d4c17; ape_uuid1 = (ape_uuid1 + (ape_elf_phnum >> 010) & 0xFF) * 0x9e3779b9925d4c17; ape_uuid1 = (ape_uuid1 + (ape_elf_phnum >> 020) & 0xFF) * 0x9e3779b9925d4c17; ape_uuid1 = (ape_uuid1 + (ape_elf_phnum >> 030) & 0xFF) * 0x9e3779b9925d4c17; ape_uuid2 = ((ape_uuid2 | (ape_elf_phnum >> 12)) - (ape_uuid2 & (ape_elf_phnum >> 12))); ape_uuid2 = ((ape_uuid2 | (ape_elf_phnum << 25)) - (ape_uuid2 & (ape_elf_phnum << 25))); ape_uuid2 = ((ape_uuid2 | (ape_elf_phnum >> 27)) - (ape_uuid2 & (ape_elf_phnum >> 27))); ape_uuid2 = (ape_uuid2 + (ape_elf_phnum >> 000) & 0xFF) * 0x9e3779b9925d4c17; ape_uuid2 = (ape_uuid2 + (ape_elf_phnum >> 010) & 0xFF) * 0x9e3779b9925d4c17; ape_uuid2 = (ape_uuid2 + (ape_elf_phnum >> 020) & 0xFF) * 0x9e3779b9925d4c17; ape_uuid2 = (ape_uuid2 + (ape_elf_phnum >> 030) & 0xFF) * 0x9e3779b9925d4c17;
ape_uuid1 = ((ape_uuid1 | (ape_elf_phoff >> 12)) - (ape_uuid1 & (ape_elf_phoff >> 12))); ape_uuid1 = ((ape_uuid1 | (ape_elf_phoff << 25)) - (ape_uuid1 & (ape_elf_phoff << 25))); ape_uuid1 = ((ape_uuid1 | (ape_elf_phoff >> 27)) - (ape_uuid1 & (ape_elf_phoff >> 27))); ape_uuid1 = (ape_uuid1 + (ape_elf_phoff >> 000) & 0xFF) * 0x9e3779b9925d4c17; ape_uuid1 = (ape_uuid1 + (ape_elf_phoff >> 010) & 0xFF) * 0x9e3779b9925d4c17; ape_uuid1 = (ape_uuid1 + (ape_elf_phoff >> 020) & 0xFF) * 0x9e3779b9925d4c17; ape_uuid1 = (ape_uuid1 + (ape_elf_phoff >> 030) & 0xFF) * 0x9e3779b9925d4c17; ape_uuid2 = ((ape_uuid2 | (ape_elf_phoff >> 12)) - (ape_uuid2 & (ape_elf_phoff >> 12))); ape_uuid2 = ((ape_uuid2 | (ape_elf_phoff << 25)) - (ape_uuid2 & (ape_elf_phoff << 25))); ape_uuid2 = ((ape_uuid2 | (ape_elf_phoff >> 27)) - (ape_uuid2 & (ape_elf_phoff >> 27))); ape_uuid2 = (ape_uuid2 + (ape_elf_phoff >> 000) & 0xFF) * 0x9e3779b9925d4c17; ape_uuid2 = (ape_uuid2 + (ape_elf_phoff >> 010) & 0xFF) * 0x9e3779b9925d4c17; ape_uuid2 = (ape_uuid2 + (ape_elf_phoff >> 020) & 0xFF) * 0x9e3779b9925d4c17; ape_uuid2 = (ape_uuid2 + (ape_elf_phoff >> 030) & 0xFF) * 0x9e3779b9925d4c17;
ape_uuid1 = ((ape_uuid1 | (ape_elf_shnum >> 12)) - (ape_uuid1 & (ape_elf_shnum >> 12))); ape_uuid1 = ((ape_uuid1 | (ape_elf_shnum << 25)) - (ape_uuid1 & (ape_elf_shnum << 25))); ape_uuid1 = ((ape_uuid1 | (ape_elf_shnum >> 27)) - (ape_uuid1 & (ape_elf_shnum >> 27))); ape_uuid1 = (ape_uuid1 + (ape_elf_shnum >> 000) & 0xFF) * 0x9e3779b9925d4c17; ape_uuid1 = (ape_uuid1 + (ape_elf_shnum >> 010) & 0xFF) * 0x9e3779b9925d4c17; ape_uuid1 = (ape_uuid1 + (ape_elf_shnum >> 020) & 0xFF) * 0x9e3779b9925d4c17; ape_uuid1 = (ape_uuid1 + (ape_elf_shnum >> 030) & 0xFF) * 0x9e3779b9925d4c17; ape_uuid2 = ((ape_uuid2 | (ape_elf_shnum >> 12)) - (ape_uuid2 & (ape_elf_shnum >> 12))); ape_uuid2 = ((ape_uuid2 | (ape_elf_shnum << 25)) - (ape_uuid2 & (ape_elf_shnum << 25))); ape_uuid2 = ((ape_uuid2 | (ape_elf_shnum >> 27)) - (ape_uuid2 & (ape_elf_shnum >> 27))); ape_uuid2 = (ape_uuid2 + (ape_elf_shnum >> 000) & 0xFF) * 0x9e3779b9925d4c17; ape_uuid2 = (ape_uuid2 + (ape_elf_shnum >> 010) & 0xFF) * 0x9e3779b9925d4c17; ape_uuid2 = (ape_uuid2 + (ape_elf_shnum >> 020) & 0xFF) * 0x9e3779b9925d4c17; ape_uuid2 = (ape_uuid2 + (ape_elf_shnum >> 030) & 0xFF) * 0x9e3779b9925d4c17;
ape_uuid1 = ((ape_uuid1 | (ape_elf_shoff >> 12)) - (ape_uuid1 & (ape_elf_shoff >> 12))); ape_uuid1 = ((ape_uuid1 | (ape_elf_shoff << 25)) - (ape_uuid1 & (ape_elf_shoff << 25))); ape_uuid1 = ((ape_uuid1 | (ape_elf_shoff >> 27)) - (ape_uuid1 & (ape_elf_shoff >> 27))); ape_uuid1 = (ape_uuid1 + (ape_elf_shoff >> 000) & 0xFF) * 0x9e3779b9925d4c17; ape_uuid1 = (ape_uuid1 + (ape_elf_shoff >> 010) & 0xFF) * 0x9e3779b9925d4c17; ape_uuid1 = (ape_uuid1 + (ape_elf_shoff >> 020) & 0xFF) * 0x9e3779b9925d4c17; ape_uuid1 = (ape_uuid1 + (ape_elf_shoff >> 030) & 0xFF) * 0x9e3779b9925d4c17; ape_uuid2 = ((ape_uuid2 | (ape_elf_shoff >> 12)) - (ape_uuid2 & (ape_elf_shoff >> 12))); ape_uuid2 = ((ape_uuid2 | (ape_elf_shoff << 25)) - (ape_uuid2 & (ape_elf_shoff << 25))); ape_uuid2 = ((ape_uuid2 | (ape_elf_shoff >> 27)) - (ape_uuid2 & (ape_elf_shoff >> 27))); ape_uuid2 = (ape_uuid2 + (ape_elf_shoff >> 000) & 0xFF) * 0x9e3779b9925d4c17; ape_uuid2 = (ape_uuid2 + (ape_elf_shoff >> 010) & 0xFF) * 0x9e3779b9925d4c17; ape_uuid2 = (ape_uuid2 + (ape_elf_shoff >> 020) & 0xFF) * 0x9e3779b9925d4c17; ape_uuid2 = (ape_uuid2 + (ape_elf_shoff >> 030) & 0xFF) * 0x9e3779b9925d4c17;
ape_uuid1 = ((ape_uuid1 | (ape_elf_shstrndx >> 12)) - (ape_uuid1 & (ape_elf_shstrndx >> 12))); ape_uuid1 = ((ape_uuid1 | (ape_elf_shstrndx << 25)) - (ape_uuid1 & (ape_elf_shstrndx << 25))); ape_uuid1 = ((ape_uuid1 | (ape_elf_shstrndx >> 27)) - (ape_uuid1 & (ape_elf_shstrndx >> 27))); ape_uuid1 = (ape_uuid1 + (ape_elf_shstrndx >> 000) & 0xFF) * 0x9e3779b9925d4c17; ape_uuid1 = (ape_uuid1 + (ape_elf_shstrndx >> 010) & 0xFF) * 0x9e3779b9925d4c17; ape_uuid1 = (ape_uuid1 + (ape_elf_shstrndx >> 020) & 0xFF) * 0x9e3779b9925d4c17; ape_uuid1 = (ape_uuid1 + (ape_elf_shstrndx >> 030) & 0xFF) * 0x9e3779b9925d4c17; ape_uuid2 = ((ape_uuid2 | (ape_elf_shstrndx >> 12)) - (ape_uuid2 & (ape_elf_shstrndx >> 12))); ape_uuid2 = ((ape_uuid2 | (ape_elf_shstrndx << 25)) - (ape_uuid2 & (ape_elf_shstrndx << 25))); ape_uuid2 = ((ape_uuid2 | (ape_elf_shstrndx >> 27)) - (ape_uuid2 & (ape_elf_shstrndx >> 27))); ape_uuid2 = (ape_uuid2 + (ape_elf_shstrndx >> 000) & 0xFF) * 0x9e3779b9925d4c17; ape_uuid2 = (ape_uuid2 + (ape_elf_shstrndx >> 010) & 0xFF) * 0x9e3779b9925d4c17; ape_uuid2 = (ape_uuid2 + (ape_elf_shstrndx >> 020) & 0xFF) * 0x9e3779b9925d4c17; ape_uuid2 = (ape_uuid2 + (ape_elf_shstrndx >> 030) & 0xFF) * 0x9e3779b9925d4c17;
ape_uuid1 = ((ape_uuid1 | (ape_macho_end >> 12)) - (ape_uuid1 & (ape_macho_end >> 12))); ape_uuid1 = ((ape_uuid1 | (ape_macho_end << 25)) - (ape_uuid1 & (ape_macho_end << 25))); ape_uuid1 = ((ape_uuid1 | (ape_macho_end >> 27)) - (ape_uuid1 & (ape_macho_end >> 27))); ape_uuid1 = (ape_uuid1 + (ape_macho_end >> 000) & 0xFF) * 0x9e3779b9925d4c17; ape_uuid1 = (ape_uuid1 + (ape_macho_end >> 010) & 0xFF) * 0x9e3779b9925d4c17; ape_uuid1 = (ape_uuid1 + (ape_macho_end >> 020) & 0xFF) * 0x9e3779b9925d4c17; ape_uuid1 = (ape_uuid1 + (ape_macho_end >> 030) & 0xFF) * 0x9e3779b9925d4c17; ape_uuid2 = ((ape_uuid2 | (ape_macho_end >> 12)) - (ape_uuid2 & (ape_macho_end >> 12))); ape_uuid2 = ((ape_uuid2 | (ape_macho_end << 25)) - (ape_uuid2 & (ape_macho_end << 25))); ape_uuid2 = ((ape_uuid2 | (ape_macho_end >> 27)) - (ape_uuid2 & (ape_macho_end >> 27))); ape_uuid2 = (ape_uuid2 + (ape_macho_end >> 000) & 0xFF) * 0x9e3779b9925d4c17; ape_uuid2 = (ape_uuid2 + (ape_macho_end >> 010) & 0xFF) * 0x9e3779b9925d4c17; ape_uuid2 = (ape_uuid2 + (ape_macho_end >> 020) & 0xFF) * 0x9e3779b9925d4c17; ape_uuid2 = (ape_uuid2 + (ape_macho_end >> 030) & 0xFF) * 0x9e3779b9925d4c17;
ape_uuid1 = ((ape_uuid1 | (ape_note >> 12)) - (ape_uuid1 & (ape_note >> 12))); ape_uuid1 = ((ape_uuid1 | (ape_note << 25)) - (ape_uuid1 & (ape_note << 25))); ape_uuid1 = ((ape_uuid1 | (ape_note >> 27)) - (ape_uuid1 & (ape_note >> 27))); ape_uuid1 = (ape_uuid1 + (ape_note >> 000) & 0xFF) * 0x9e3779b9925d4c17; ape_uuid1 = (ape_uuid1 + (ape_note >> 010) & 0xFF) * 0x9e3779b9925d4c17; ape_uuid1 = (ape_uuid1 + (ape_note >> 020) & 0xFF) * 0x9e3779b9925d4c17; ape_uuid1 = (ape_uuid1 + (ape_note >> 030) & 0xFF) * 0x9e3779b9925d4c17; ape_uuid2 = ((ape_uuid2 | (ape_note >> 12)) - (ape_uuid2 & (ape_note >> 12))); ape_uuid2 = ((ape_uuid2 | (ape_note << 25)) - (ape_uuid2 & (ape_note << 25))); ape_uuid2 = ((ape_uuid2 | (ape_note >> 27)) - (ape_uuid2 & (ape_note >> 27))); ape_uuid2 = (ape_uuid2 + (ape_note >> 000) & 0xFF) * 0x9e3779b9925d4c17; ape_uuid2 = (ape_uuid2 + (ape_note >> 010) & 0xFF) * 0x9e3779b9925d4c17; ape_uuid2 = (ape_uuid2 + (ape_note >> 020) & 0xFF) * 0x9e3779b9925d4c17; ape_uuid2 = (ape_uuid2 + (ape_note >> 030) & 0xFF) * 0x9e3779b9925d4c17;
ape_uuid1 = ((ape_uuid1 | (ape_note_end >> 12)) - (ape_uuid1 & (ape_note_end >> 12))); ape_uuid1 = ((ape_uuid1 | (ape_note_end << 25)) - (ape_uuid1 & (ape_note_end << 25))); ape_uuid1 = ((ape_uuid1 | (ape_note_end >> 27)) - (ape_uuid1 & (ape_note_end >> 27))); ape_uuid1 = (ape_uuid1 + (ape_note_end >> 000) & 0xFF) * 0x9e3779b9925d4c17; ape_uuid1 = (ape_uuid1 + (ape_note_end >> 010) & 0xFF) * 0x9e3779b9925d4c17; ape_uuid1 = (ape_uuid1 + (ape_note_end >> 020) & 0xFF) * 0x9e3779b9925d4c17; ape_uuid1 = (ape_uuid1 + (ape_note_end >> 030) & 0xFF) * 0x9e3779b9925d4c17; ape_uuid2 = ((ape_uuid2 | (ape_note_end >> 12)) - (ape_uuid2 & (ape_note_end >> 12))); ape_uuid2 = ((ape_uuid2 | (ape_note_end << 25)) - (ape_uuid2 & (ape_note_end << 25))); ape_uuid2 = ((ape_uuid2 | (ape_note_end >> 27)) - (ape_uuid2 & (ape_note_end >> 27))); ape_uuid2 = (ape_uuid2 + (ape_note_end >> 000) & 0xFF) * 0x9e3779b9925d4c17; ape_uuid2 = (ape_uuid2 + (ape_note_end >> 010) & 0xFF) * 0x9e3779b9925d4c17; ape_uuid2 = (ape_uuid2 + (ape_note_end >> 020) & 0xFF) * 0x9e3779b9925d4c17; ape_uuid2 = (ape_uuid2 + (ape_note_end >> 030) & 0xFF) * 0x9e3779b9925d4c17;
ape_uuid1 = ((ape_uuid1 | (ape_note_filesz >> 12)) - (ape_uuid1 & (ape_note_filesz >> 12))); ape_uuid1 = ((ape_uuid1 | (ape_note_filesz << 25)) - (ape_uuid1 & (ape_note_filesz << 25))); ape_uuid1 = ((ape_uuid1 | (ape_note_filesz >> 27)) - (ape_uuid1 & (ape_note_filesz >> 27))); ape_uuid1 = (ape_uuid1 + (ape_note_filesz >> 000) & 0xFF) * 0x9e3779b9925d4c17; ape_uuid1 = (ape_uuid1 + (ape_note_filesz >> 010) & 0xFF) * 0x9e3779b9925d4c17; ape_uuid1 = (ape_uuid1 + (ape_note_filesz >> 020) & 0xFF) * 0x9e3779b9925d4c17; ape_uuid1 = (ape_uuid1 + (ape_note_filesz >> 030) & 0xFF) * 0x9e3779b9925d4c17; ape_uuid2 = ((ape_uuid2 | (ape_note_filesz >> 12)) - (ape_uuid2 & (ape_note_filesz >> 12))); ape_uuid2 = ((ape_uuid2 | (ape_note_filesz << 25)) - (ape_uuid2 & (ape_note_filesz << 25))); ape_uuid2 = ((ape_uuid2 | (ape_note_filesz >> 27)) - (ape_uuid2 & (ape_note_filesz >> 27))); ape_uuid2 = (ape_uuid2 + (ape_note_filesz >> 000) & 0xFF) * 0x9e3779b9925d4c17; ape_uuid2 = (ape_uuid2 + (ape_note_filesz >> 010) & 0xFF) * 0x9e3779b9925d4c17; ape_uuid2 = (ape_uuid2 + (ape_note_filesz >> 020) & 0xFF) * 0x9e3779b9925d4c17; ape_uuid2 = (ape_uuid2 + (ape_note_filesz >> 030) & 0xFF) * 0x9e3779b9925d4c17;
ape_uuid1 = ((ape_uuid1 | (ape_note_memsz >> 12)) - (ape_uuid1 & (ape_note_memsz >> 12))); ape_uuid1 = ((ape_uuid1 | (ape_note_memsz << 25)) - (ape_uuid1 & (ape_note_memsz << 25))); ape_uuid1 = ((ape_uuid1 | (ape_note_memsz >> 27)) - (ape_uuid1 & (ape_note_memsz >> 27))); ape_uuid1 = (ape_uuid1 + (ape_note_memsz >> 000) & 0xFF) * 0x9e3779b9925d4c17; ape_uuid1 = (ape_uuid1 + (ape_note_memsz >> 010) & 0xFF) * 0x9e3779b9925d4c17; ape_uuid1 = (ape_uuid1 + (ape_note_memsz >> 020) & 0xFF) * 0x9e3779b9925d4c17; ape_uuid1 = (ape_uuid1 + (ape_note_memsz >> 030) & 0xFF) * 0x9e3779b9925d4c17; ape_uuid2 = ((ape_uuid2 | (ape_note_memsz >> 12)) - (ape_uuid2 & (ape_note_memsz >> 12))); ape_uuid2 = ((ape_uuid2 | (ape_note_memsz << 25)) - (ape_uuid2 & (ape_note_memsz << 25))); ape_uuid2 = ((ape_uuid2 | (ape_note_memsz >> 27)) - (ape_uuid2 & (ape_note_memsz >> 27))); ape_uuid2 = (ape_uuid2 + (ape_note_memsz >> 000) & 0xFF) * 0x9e3779b9925d4c17; ape_uuid2 = (ape_uuid2 + (ape_note_memsz >> 010) & 0xFF) * 0x9e3779b9925d4c17; ape_uuid2 = (ape_uuid2 + (ape_note_memsz >> 020) & 0xFF) * 0x9e3779b9925d4c17; ape_uuid2 = (ape_uuid2 + (ape_note_memsz >> 030) & 0xFF) * 0x9e3779b9925d4c17;
ape_uuid1 = ((ape_uuid1 | (ape_note_offset >> 12)) - (ape_uuid1 & (ape_note_offset >> 12))); ape_uuid1 = ((ape_uuid1 | (ape_note_offset << 25)) - (ape_uuid1 & (ape_note_offset << 25))); ape_uuid1 = ((ape_uuid1 | (ape_note_offset >> 27)) - (ape_uuid1 & (ape_note_offset >> 27))); ape_uuid1 = (ape_uuid1 + (ape_note_offset >> 000) & 0xFF) * 0x9e3779b9925d4c17; ape_uuid1 = (ape_uuid1 + (ape_note_offset >> 010) & 0xFF) * 0x9e3779b9925d4c17; ape_uuid1 = (ape_uuid1 + (ape_note_offset >> 020) & 0xFF) * 0x9e3779b9925d4c17; ape_uuid1 = (ape_uuid1 + (ape_note_offset >> 030) & 0xFF) * 0x9e3779b9925d4c17; ape_uuid2 = ((ape_uuid2 | (ape_note_offset >> 12)) - (ape_uuid2 & (ape_note_offset >> 12))); ape_uuid2 = ((ape_uuid2 | (ape_note_offset << 25)) - (ape_uuid2 & (ape_note_offset << 25))); ape_uuid2 = ((ape_uuid2 | (ape_note_offset >> 27)) - (ape_uuid2 & (ape_note_offset >> 27))); ape_uuid2 = (ape_uuid2 + (ape_note_offset >> 000) & 0xFF) * 0x9e3779b9925d4c17; ape_uuid2 = (ape_uuid2 + (ape_note_offset >> 010) & 0xFF) * 0x9e3779b9925d4c17; ape_uuid2 = (ape_uuid2 + (ape_note_offset >> 020) & 0xFF) * 0x9e3779b9925d4c17; ape_uuid2 = (ape_uuid2 + (ape_note_offset >> 030) & 0xFF) * 0x9e3779b9925d4c17;
ape_uuid1 = ((ape_uuid1 | (ape_ram_align >> 12)) - (ape_uuid1 & (ape_ram_align >> 12))); ape_uuid1 = ((ape_uuid1 | (ape_ram_align << 25)) - (ape_uuid1 & (ape_ram_align << 25))); ape_uuid1 = ((ape_uuid1 | (ape_ram_align >> 27)) - (ape_uuid1 & (ape_ram_align >> 27))); ape_uuid1 = (ape_uuid1 + (ape_ram_align >> 000) & 0xFF) * 0x9e3779b9925d4c17; ape_uuid1 = (ape_uuid1 + (ape_ram_align >> 010) & 0xFF) * 0x9e3779b9925d4c17; ape_uuid1 = (ape_uuid1 + (ape_ram_align >> 020) & 0xFF) * 0x9e3779b9925d4c17; ape_uuid1 = (ape_uuid1 + (ape_ram_align >> 030) & 0xFF) * 0x9e3779b9925d4c17; ape_uuid2 = ((ape_uuid2 | (ape_ram_align >> 12)) - (ape_uuid2 & (ape_ram_align >> 12))); ape_uuid2 = ((ape_uuid2 | (ape_ram_align << 25)) - (ape_uuid2 & (ape_ram_align << 25))); ape_uuid2 = ((ape_uuid2 | (ape_ram_align >> 27)) - (ape_uuid2 & (ape_ram_align >> 27))); ape_uuid2 = (ape_uuid2 + (ape_ram_align >> 000) & 0xFF) * 0x9e3779b9925d4c17; ape_uuid2 = (ape_uuid2 + (ape_ram_align >> 010) & 0xFF) * 0x9e3779b9925d4c17; ape_uuid2 = (ape_uuid2 + (ape_ram_align >> 020) & 0xFF) * 0x9e3779b9925d4c17; ape_uuid2 = (ape_uuid2 + (ape_ram_align >> 030) & 0xFF) * 0x9e3779b9925d4c17;
ape_uuid1 = ((ape_uuid1 | (ape_ram_filesz >> 12)) - (ape_uuid1 & (ape_ram_filesz >> 12))); ape_uuid1 = ((ape_uuid1 | (ape_ram_filesz << 25)) - (ape_uuid1 & (ape_ram_filesz << 25))); ape_uuid1 = ((ape_uuid1 | (ape_ram_filesz >> 27)) - (ape_uuid1 & (ape_ram_filesz >> 27))); ape_uuid1 = (ape_uuid1 + (ape_ram_filesz >> 000) & 0xFF) * 0x9e3779b9925d4c17; ape_uuid1 = (ape_uuid1 + (ape_ram_filesz >> 010) & 0xFF) * 0x9e3779b9925d4c17; ape_uuid1 = (ape_uuid1 + (ape_ram_filesz >> 020) & 0xFF) * 0x9e3779b9925d4c17; ape_uuid1 = (ape_uuid1 + (ape_ram_filesz >> 030) & 0xFF) * 0x9e3779b9925d4c17; ape_uuid2 = ((ape_uuid2 | (ape_ram_filesz >> 12)) - (ape_uuid2 & (ape_ram_filesz >> 12))); ape_uuid2 = ((ape_uuid2 | (ape_ram_filesz << 25)) - (ape_uuid2 & (ape_ram_filesz << 25))); ape_uuid2 = ((ape_uuid2 | (ape_ram_filesz >> 27)) - (ape_uuid2 & (ape_ram_filesz >> 27))); ape_uuid2 = (ape_uuid2 + (ape_ram_filesz >> 000) & 0xFF) * 0x9e3779b9925d4c17; ape_uuid2 = (ape_uuid2 + (ape_ram_filesz >> 010) & 0xFF) * 0x9e3779b9925d4c17; ape_uuid2 = (ape_uuid2 + (ape_ram_filesz >> 020) & 0xFF) * 0x9e3779b9925d4c17; ape_uuid2 = (ape_uuid2 + (ape_ram_filesz >> 030) & 0xFF) * 0x9e3779b9925d4c17;
ape_uuid1 = ((ape_uuid1 | (ape_ram_memsz >> 12)) - (ape_uuid1 & (ape_ram_memsz >> 12))); ape_uuid1 = ((ape_uuid1 | (ape_ram_memsz << 25)) - (ape_uuid1 & (ape_ram_memsz << 25))); ape_uuid1 = ((ape_uuid1 | (ape_ram_memsz >> 27)) - (ape_uuid1 & (ape_ram_memsz >> 27))); ape_uuid1 = (ape_uuid1 + (ape_ram_memsz >> 000) & 0xFF) * 0x9e3779b9925d4c17; ape_uuid1 = (ape_uuid1 + (ape_ram_memsz >> 010) & 0xFF) * 0x9e3779b9925d4c17; ape_uuid1 = (ape_uuid1 + (ape_ram_memsz >> 020) & 0xFF) * 0x9e3779b9925d4c17; ape_uuid1 = (ape_uuid1 + (ape_ram_memsz >> 030) & 0xFF) * 0x9e3779b9925d4c17; ape_uuid2 = ((ape_uuid2 | (ape_ram_memsz >> 12)) - (ape_uuid2 & (ape_ram_memsz >> 12))); ape_uuid2 = ((ape_uuid2 | (ape_ram_memsz << 25)) - (ape_uuid2 & (ape_ram_memsz << 25))); ape_uuid2 = ((ape_uuid2 | (ape_ram_memsz >> 27)) - (ape_uuid2 & (ape_ram_memsz >> 27))); ape_uuid2 = (ape_uuid2 + (ape_ram_memsz >> 000) & 0xFF) * 0x9e3779b9925d4c17; ape_uuid2 = (ape_uuid2 + (ape_ram_memsz >> 010) & 0xFF) * 0x9e3779b9925d4c17; ape_uuid2 = (ape_uuid2 + (ape_ram_memsz >> 020) & 0xFF) * 0x9e3779b9925d4c17; ape_uuid2 = (ape_uuid2 + (ape_ram_memsz >> 030) & 0xFF) * 0x9e3779b9925d4c17;
ape_uuid1 = ((ape_uuid1 | (ape_ram_offset >> 12)) - (ape_uuid1 & (ape_ram_offset >> 12))); ape_uuid1 = ((ape_uuid1 | (ape_ram_offset << 25)) - (ape_uuid1 & (ape_ram_offset << 25))); ape_uuid1 = ((ape_uuid1 | (ape_ram_offset >> 27)) - (ape_uuid1 & (ape_ram_offset >> 27))); ape_uuid1 = (ape_uuid1 + (ape_ram_offset >> 000) & 0xFF) * 0x9e3779b9925d4c17; ape_uuid1 = (ape_uuid1 + (ape_ram_offset >> 010) & 0xFF) * 0x9e3779b9925d4c17; ape_uuid1 = (ape_uuid1 + (ape_ram_offset >> 020) & 0xFF) * 0x9e3779b9925d4c17; ape_uuid1 = (ape_uuid1 + (ape_ram_offset >> 030) & 0xFF) * 0x9e3779b9925d4c17; ape_uuid2 = ((ape_uuid2 | (ape_ram_offset >> 12)) - (ape_uuid2 & (ape_ram_offset >> 12))); ape_uuid2 = ((ape_uuid2 | (ape_ram_offset << 25)) - (ape_uuid2 & (ape_ram_offset << 25))); ape_uuid2 = ((ape_uuid2 | (ape_ram_offset >> 27)) - (ape_uuid2 & (ape_ram_offset >> 27))); ape_uuid2 = (ape_uuid2 + (ape_ram_offset >> 000) & 0xFF) * 0x9e3779b9925d4c17; ape_uuid2 = (ape_uuid2 + (ape_ram_offset >> 010) & 0xFF) * 0x9e3779b9925d4c17; ape_uuid2 = (ape_uuid2 + (ape_ram_offset >> 020) & 0xFF) * 0x9e3779b9925d4c17; ape_uuid2 = (ape_uuid2 + (ape_ram_offset >> 030) & 0xFF) * 0x9e3779b9925d4c17;
ape_uuid1 = ((ape_uuid1 | (ape_ram_paddr >> 12)) - (ape_uuid1 & (ape_ram_paddr >> 12))); ape_uuid1 = ((ape_uuid1 | (ape_ram_paddr << 25)) - (ape_uuid1 & (ape_ram_paddr << 25))); ape_uuid1 = ((ape_uuid1 | (ape_ram_paddr >> 27)) - (ape_uuid1 & (ape_ram_paddr >> 27))); ape_uuid1 = (ape_uuid1 + (ape_ram_paddr >> 000) & 0xFF) * 0x9e3779b9925d4c17; ape_uuid1 = (ape_uuid1 + (ape_ram_paddr >> 010) & 0xFF) * 0x9e3779b9925d4c17; ape_uuid1 = (ape_uuid1 + (ape_ram_paddr >> 020) & 0xFF) * 0x9e3779b9925d4c17; ape_uuid1 = (ape_uuid1 + (ape_ram_paddr >> 030) & 0xFF) * 0x9e3779b9925d4c17; ape_uuid2 = ((ape_uuid2 | (ape_ram_paddr >> 12)) - (ape_uuid2 & (ape_ram_paddr >> 12))); ape_uuid2 = ((ape_uuid2 | (ape_ram_paddr << 25)) - (ape_uuid2 & (ape_ram_paddr << 25))); ape_uuid2 = ((ape_uuid2 | (ape_ram_paddr >> 27)) - (ape_uuid2 & (ape_ram_paddr >> 27))); ape_uuid2 = (ape_uuid2 + (ape_ram_paddr >> 000) & 0xFF) * 0x9e3779b9925d4c17; ape_uuid2 = (ape_uuid2 + (ape_ram_paddr >> 010) & 0xFF) * 0x9e3779b9925d4c17; ape_uuid2 = (ape_uuid2 + (ape_ram_paddr >> 020) & 0xFF) * 0x9e3779b9925d4c17; ape_uuid2 = (ape_uuid2 + (ape_ram_paddr >> 030) & 0xFF) * 0x9e3779b9925d4c17;
ape_uuid1 = ((ape_uuid1 | (ape_ram_rva >> 12)) - (ape_uuid1 & (ape_ram_rva >> 12))); ape_uuid1 = ((ape_uuid1 | (ape_ram_rva << 25)) - (ape_uuid1 & (ape_ram_rva << 25))); ape_uuid1 = ((ape_uuid1 | (ape_ram_rva >> 27)) - (ape_uuid1 & (ape_ram_rva >> 27))); ape_uuid1 = (ape_uuid1 + (ape_ram_rva >> 000) & 0xFF) * 0x9e3779b9925d4c17; ape_uuid1 = (ape_uuid1 + (ape_ram_rva >> 010) & 0xFF) * 0x9e3779b9925d4c17; ape_uuid1 = (ape_uuid1 + (ape_ram_rva >> 020) & 0xFF) * 0x9e3779b9925d4c17; ape_uuid1 = (ape_uuid1 + (ape_ram_rva >> 030) & 0xFF) * 0x9e3779b9925d4c17; ape_uuid2 = ((ape_uuid2 | (ape_ram_rva >> 12)) - (ape_uuid2 & (ape_ram_rva >> 12))); ape_uuid2 = ((ape_uuid2 | (ape_ram_rva << 25)) - (ape_uuid2 & (ape_ram_rva << 25))); ape_uuid2 = ((ape_uuid2 | (ape_ram_rva >> 27)) - (ape_uuid2 & (ape_ram_rva >> 27))); ape_uuid2 = (ape_uuid2 + (ape_ram_rva >> 000) & 0xFF) * 0x9e3779b9925d4c17; ape_uuid2 = (ape_uuid2 + (ape_ram_rva >> 010) & 0xFF) * 0x9e3779b9925d4c17; ape_uuid2 = (ape_uuid2 + (ape_ram_rva >> 020) & 0xFF) * 0x9e3779b9925d4c17; ape_uuid2 = (ape_uuid2 + (ape_ram_rva >> 030) & 0xFF) * 0x9e3779b9925d4c17;
ape_uuid1 = ((ape_uuid1 | (ape_ram_vaddr >> 12)) - (ape_uuid1 & (ape_ram_vaddr >> 12))); ape_uuid1 = ((ape_uuid1 | (ape_ram_vaddr << 25)) - (ape_uuid1 & (ape_ram_vaddr << 25))); ape_uuid1 = ((ape_uuid1 | (ape_ram_vaddr >> 27)) - (ape_uuid1 & (ape_ram_vaddr >> 27))); ape_uuid1 = (ape_uuid1 + (ape_ram_vaddr >> 000) & 0xFF) * 0x9e3779b9925d4c17; ape_uuid1 = (ape_uuid1 + (ape_ram_vaddr >> 010) & 0xFF) * 0x9e3779b9925d4c17; ape_uuid1 = (ape_uuid1 + (ape_ram_vaddr >> 020) & 0xFF) * 0x9e3779b9925d4c17; ape_uuid1 = (ape_uuid1 + (ape_ram_vaddr >> 030) & 0xFF) * 0x9e3779b9925d4c17; ape_uuid2 = ((ape_uuid2 | (ape_ram_vaddr >> 12)) - (ape_uuid2 & (ape_ram_vaddr >> 12))); ape_uuid2 = ((ape_uuid2 | (ape_ram_vaddr << 25)) - (ape_uuid2 & (ape_ram_vaddr << 25))); ape_uuid2 = ((ape_uuid2 | (ape_ram_vaddr >> 27)) - (ape_uuid2 & (ape_ram_vaddr >> 27))); ape_uuid2 = (ape_uuid2 + (ape_ram_vaddr >> 000) & 0xFF) * 0x9e3779b9925d4c17; ape_uuid2 = (ape_uuid2 + (ape_ram_vaddr >> 010) & 0xFF) * 0x9e3779b9925d4c17; ape_uuid2 = (ape_uuid2 + (ape_ram_vaddr >> 020) & 0xFF) * 0x9e3779b9925d4c17; ape_uuid2 = (ape_uuid2 + (ape_ram_vaddr >> 030) & 0xFF) * 0x9e3779b9925d4c17;
ape_uuid1 = ((ape_uuid1 | (ape_rom_align >> 12)) - (ape_uuid1 & (ape_rom_align >> 12))); ape_uuid1 = ((ape_uuid1 | (ape_rom_align << 25)) - (ape_uuid1 & (ape_rom_align << 25))); ape_uuid1 = ((ape_uuid1 | (ape_rom_align >> 27)) - (ape_uuid1 & (ape_rom_align >> 27))); ape_uuid1 = (ape_uuid1 + (ape_rom_align >> 000) & 0xFF) * 0x9e3779b9925d4c17; ape_uuid1 = (ape_uuid1 + (ape_rom_align >> 010) & 0xFF) * 0x9e3779b9925d4c17; ape_uuid1 = (ape_uuid1 + (ape_rom_align >> 020) & 0xFF) * 0x9e3779b9925d4c17; ape_uuid1 = (ape_uuid1 + (ape_rom_align >> 030) & 0xFF) * 0x9e3779b9925d4c17; ape_uuid2 = ((ape_uuid2 | (ape_rom_align >> 12)) - (ape_uuid2 & (ape_rom_align >> 12))); ape_uuid2 = ((ape_uuid2 | (ape_rom_align << 25)) - (ape_uuid2 & (ape_rom_align << 25))); ape_uuid2 = ((ape_uuid2 | (ape_rom_align >> 27)) - (ape_uuid2 & (ape_rom_align >> 27))); ape_uuid2 = (ape_uuid2 + (ape_rom_align >> 000) & 0xFF) * 0x9e3779b9925d4c17; ape_uuid2 = (ape_uuid2 + (ape_rom_align >> 010) & 0xFF) * 0x9e3779b9925d4c17; ape_uuid2 = (ape_uuid2 + (ape_rom_align >> 020) & 0xFF) * 0x9e3779b9925d4c17; ape_uuid2 = (ape_uuid2 + (ape_rom_align >> 030) & 0xFF) * 0x9e3779b9925d4c17;
ape_uuid1 = ((ape_uuid1 | (ape_rom_filesz >> 12)) - (ape_uuid1 & (ape_rom_filesz >> 12))); ape_uuid1 = ((ape_uuid1 | (ape_rom_filesz << 25)) - (ape_uuid1 & (ape_rom_filesz << 25))); ape_uuid1 = ((ape_uuid1 | (ape_rom_filesz >> 27)) - (ape_uuid1 & (ape_rom_filesz >> 27))); ape_uuid1 = (ape_uuid1 + (ape_rom_filesz >> 000) & 0xFF) * 0x9e3779b9925d4c17; ape_uuid1 = (ape_uuid1 + (ape_rom_filesz >> 010) & 0xFF) * 0x9e3779b9925d4c17; ape_uuid1 = (ape_uuid1 + (ape_rom_filesz >> 020) & 0xFF) * 0x9e3779b9925d4c17; ape_uuid1 = (ape_uuid1 + (ape_rom_filesz >> 030) & 0xFF) * 0x9e3779b9925d4c17; ape_uuid2 = ((ape_uuid2 | (ape_rom_filesz >> 12)) - (ape_uuid2 & (ape_rom_filesz >> 12))); ape_uuid2 = ((ape_uuid2 | (ape_rom_filesz << 25)) - (ape_uuid2 & (ape_rom_filesz << 25))); ape_uuid2 = ((ape_uuid2 | (ape_rom_filesz >> 27)) - (ape_uuid2 & (ape_rom_filesz >> 27))); ape_uuid2 = (ape_uuid2 + (ape_rom_filesz >> 000) & 0xFF) * 0x9e3779b9925d4c17; ape_uuid2 = (ape_uuid2 + (ape_rom_filesz >> 010) & 0xFF) * 0x9e3779b9925d4c17; ape_uuid2 = (ape_uuid2 + (ape_rom_filesz >> 020) & 0xFF) * 0x9e3779b9925d4c17; ape_uuid2 = (ape_uuid2 + (ape_rom_filesz >> 030) & 0xFF) * 0x9e3779b9925d4c17;
ape_uuid1 = ((ape_uuid1 | (ape_rom_memsz >> 12)) - (ape_uuid1 & (ape_rom_memsz >> 12))); ape_uuid1 = ((ape_uuid1 | (ape_rom_memsz << 25)) - (ape_uuid1 & (ape_rom_memsz << 25))); ape_uuid1 = ((ape_uuid1 | (ape_rom_memsz >> 27)) - (ape_uuid1 & (ape_rom_memsz >> 27))); ape_uuid1 = (ape_uuid1 + (ape_rom_memsz >> 000) & 0xFF) * 0x9e3779b9925d4c17; ape_uuid1 = (ape_uuid1 + (ape_rom_memsz >> 010) & 0xFF) * 0x9e3779b9925d4c17; ape_uuid1 = (ape_uuid1 + (ape_rom_memsz >> 020) & 0xFF) * 0x9e3779b9925d4c17; ape_uuid1 = (ape_uuid1 + (ape_rom_memsz >> 030) & 0xFF) * 0x9e3779b9925d4c17; ape_uuid2 = ((ape_uuid2 | (ape_rom_memsz >> 12)) - (ape_uuid2 & (ape_rom_memsz >> 12))); ape_uuid2 = ((ape_uuid2 | (ape_rom_memsz << 25)) - (ape_uuid2 & (ape_rom_memsz << 25))); ape_uuid2 = ((ape_uuid2 | (ape_rom_memsz >> 27)) - (ape_uuid2 & (ape_rom_memsz >> 27))); ape_uuid2 = (ape_uuid2 + (ape_rom_memsz >> 000) & 0xFF) * 0x9e3779b9925d4c17; ape_uuid2 = (ape_uuid2 + (ape_rom_memsz >> 010) & 0xFF) * 0x9e3779b9925d4c17; ape_uuid2 = (ape_uuid2 + (ape_rom_memsz >> 020) & 0xFF) * 0x9e3779b9925d4c17; ape_uuid2 = (ape_uuid2 + (ape_rom_memsz >> 030) & 0xFF) * 0x9e3779b9925d4c17;
ape_uuid1 = ((ape_uuid1 | (ape_rom_offset >> 12)) - (ape_uuid1 & (ape_rom_offset >> 12))); ape_uuid1 = ((ape_uuid1 | (ape_rom_offset << 25)) - (ape_uuid1 & (ape_rom_offset << 25))); ape_uuid1 = ((ape_uuid1 | (ape_rom_offset >> 27)) - (ape_uuid1 & (ape_rom_offset >> 27))); ape_uuid1 = (ape_uuid1 + (ape_rom_offset >> 000) & 0xFF) * 0x9e3779b9925d4c17; ape_uuid1 = (ape_uuid1 + (ape_rom_offset >> 010) & 0xFF) * 0x9e3779b9925d4c17; ape_uuid1 = (ape_uuid1 + (ape_rom_offset >> 020) & 0xFF) * 0x9e3779b9925d4c17; ape_uuid1 = (ape_uuid1 + (ape_rom_offset >> 030) & 0xFF) * 0x9e3779b9925d4c17; ape_uuid2 = ((ape_uuid2 | (ape_rom_offset >> 12)) - (ape_uuid2 & (ape_rom_offset >> 12))); ape_uuid2 = ((ape_uuid2 | (ape_rom_offset << 25)) - (ape_uuid2 & (ape_rom_offset << 25))); ape_uuid2 = ((ape_uuid2 | (ape_rom_offset >> 27)) - (ape_uuid2 & (ape_rom_offset >> 27))); ape_uuid2 = (ape_uuid2 + (ape_rom_offset >> 000) & 0xFF) * 0x9e3779b9925d4c17; ape_uuid2 = (ape_uuid2 + (ape_rom_offset >> 010) & 0xFF) * 0x9e3779b9925d4c17; ape_uuid2 = (ape_uuid2 + (ape_rom_offset >> 020) & 0xFF) * 0x9e3779b9925d4c17; ape_uuid2 = (ape_uuid2 + (ape_rom_offset >> 030) & 0xFF) * 0x9e3779b9925d4c17;
ape_uuid1 = ((ape_uuid1 | (ape_rom_paddr >> 12)) - (ape_uuid1 & (ape_rom_paddr >> 12))); ape_uuid1 = ((ape_uuid1 | (ape_rom_paddr << 25)) - (ape_uuid1 & (ape_rom_paddr << 25))); ape_uuid1 = ((ape_uuid1 | (ape_rom_paddr >> 27)) - (ape_uuid1 & (ape_rom_paddr >> 27))); ape_uuid1 = (ape_uuid1 + (ape_rom_paddr >> 000) & 0xFF) * 0x9e3779b9925d4c17; ape_uuid1 = (ape_uuid1 + (ape_rom_paddr >> 010) & 0xFF) * 0x9e3779b9925d4c17; ape_uuid1 = (ape_uuid1 + (ape_rom_paddr >> 020) & 0xFF) * 0x9e3779b9925d4c17; ape_uuid1 = (ape_uuid1 + (ape_rom_paddr >> 030) & 0xFF) * 0x9e3779b9925d4c17; ape_uuid2 = ((ape_uuid2 | (ape_rom_paddr >> 12)) - (ape_uuid2 & (ape_rom_paddr >> 12))); ape_uuid2 = ((ape_uuid2 | (ape_rom_paddr << 25)) - (ape_uuid2 & (ape_rom_paddr << 25))); ape_uuid2 = ((ape_uuid2 | (ape_rom_paddr >> 27)) - (ape_uuid2 & (ape_rom_paddr >> 27))); ape_uuid2 = (ape_uuid2 + (ape_rom_paddr >> 000) & 0xFF) * 0x9e3779b9925d4c17; ape_uuid2 = (ape_uuid2 + (ape_rom_paddr >> 010) & 0xFF) * 0x9e3779b9925d4c17; ape_uuid2 = (ape_uuid2 + (ape_rom_paddr >> 020) & 0xFF) * 0x9e3779b9925d4c17; ape_uuid2 = (ape_uuid2 + (ape_rom_paddr >> 030) & 0xFF) * 0x9e3779b9925d4c17;
ape_uuid1 = ((ape_uuid1 | (ape_rom_rva >> 12)) - (ape_uuid1 & (ape_rom_rva >> 12))); ape_uuid1 = ((ape_uuid1 | (ape_rom_rva << 25)) - (ape_uuid1 & (ape_rom_rva << 25))); ape_uuid1 = ((ape_uuid1 | (ape_rom_rva >> 27)) - (ape_uuid1 & (ape_rom_rva >> 27))); ape_uuid1 = (ape_uuid1 + (ape_rom_rva >> 000) & 0xFF) * 0x9e3779b9925d4c17; ape_uuid1 = (ape_uuid1 + (ape_rom_rva >> 010) & 0xFF) * 0x9e3779b9925d4c17; ape_uuid1 = (ape_uuid1 + (ape_rom_rva >> 020) & 0xFF) * 0x9e3779b9925d4c17; ape_uuid1 = (ape_uuid1 + (ape_rom_rva >> 030) & 0xFF) * 0x9e3779b9925d4c17; ape_uuid2 = ((ape_uuid2 | (ape_rom_rva >> 12)) - (ape_uuid2 & (ape_rom_rva >> 12))); ape_uuid2 = ((ape_uuid2 | (ape_rom_rva << 25)) - (ape_uuid2 & (ape_rom_rva << 25))); ape_uuid2 = ((ape_uuid2 | (ape_rom_rva >> 27)) - (ape_uuid2 & (ape_rom_rva >> 27))); ape_uuid2 = (ape_uuid2 + (ape_rom_rva >> 000) & 0xFF) * 0x9e3779b9925d4c17; ape_uuid2 = (ape_uuid2 + (ape_rom_rva >> 010) & 0xFF) * 0x9e3779b9925d4c17; ape_uuid2 = (ape_uuid2 + (ape_rom_rva >> 020) & 0xFF) * 0x9e3779b9925d4c17; ape_uuid2 = (ape_uuid2 + (ape_rom_rva >> 030) & 0xFF) * 0x9e3779b9925d4c17;
ape_uuid1 = ((ape_uuid1 | (ape_cod_vaddr >> 12)) - (ape_uuid1 & (ape_cod_vaddr >> 12))); ape_uuid1 = ((ape_uuid1 | (ape_cod_vaddr << 25)) - (ape_uuid1 & (ape_cod_vaddr << 25))); ape_uuid1 = ((ape_uuid1 | (ape_cod_vaddr >> 27)) - (ape_uuid1 & (ape_cod_vaddr >> 27))); ape_uuid1 = (ape_uuid1 + (ape_cod_vaddr >> 000) & 0xFF) * 0x9e3779b9925d4c17; ape_uuid1 = (ape_uuid1 + (ape_cod_vaddr >> 010) & 0xFF) * 0x9e3779b9925d4c17; ape_uuid1 = (ape_uuid1 + (ape_cod_vaddr >> 020) & 0xFF) * 0x9e3779b9925d4c17; ape_uuid1 = (ape_uuid1 + (ape_cod_vaddr >> 030) & 0xFF) * 0x9e3779b9925d4c17; ape_uuid2 = ((ape_uuid2 | (ape_cod_vaddr >> 12)) - (ape_uuid2 & (ape_cod_vaddr >> 12))); ape_uuid2 = ((ape_uuid2 | (ape_cod_vaddr << 25)) - (ape_uuid2 & (ape_cod_vaddr << 25))); ape_uuid2 = ((ape_uuid2 | (ape_cod_vaddr >> 27)) - (ape_uuid2 & (ape_cod_vaddr >> 27))); ape_uuid2 = (ape_uuid2 + (ape_cod_vaddr >> 000) & 0xFF) * 0x9e3779b9925d4c17; ape_uuid2 = (ape_uuid2 + (ape_cod_vaddr >> 010) & 0xFF) * 0x9e3779b9925d4c17; ape_uuid2 = (ape_uuid2 + (ape_cod_vaddr >> 020) & 0xFF) * 0x9e3779b9925d4c17; ape_uuid2 = (ape_uuid2 + (ape_cod_vaddr >> 030) & 0xFF) * 0x9e3779b9925d4c17;
ape_uuid1 = ((ape_uuid1 | (ape_cod_align >> 12)) - (ape_uuid1 & (ape_cod_align >> 12))); ape_uuid1 = ((ape_uuid1 | (ape_cod_align << 25)) - (ape_uuid1 & (ape_cod_align << 25))); ape_uuid1 = ((ape_uuid1 | (ape_cod_align >> 27)) - (ape_uuid1 & (ape_cod_align >> 27))); ape_uuid1 = (ape_uuid1 + (ape_cod_align >> 000) & 0xFF) * 0x9e3779b9925d4c17; ape_uuid1 = (ape_uuid1 + (ape_cod_align >> 010) & 0xFF) * 0x9e3779b9925d4c17; ape_uuid1 = (ape_uuid1 + (ape_cod_align >> 020) & 0xFF) * 0x9e3779b9925d4c17; ape_uuid1 = (ape_uuid1 + (ape_cod_align >> 030) & 0xFF) * 0x9e3779b9925d4c17; ape_uuid2 = ((ape_uuid2 | (ape_cod_align >> 12)) - (ape_uuid2 & (ape_cod_align >> 12))); ape_uuid2 = ((ape_uuid2 | (ape_cod_align << 25)) - (ape_uuid2 & (ape_cod_align << 25))); ape_uuid2 = ((ape_uuid2 | (ape_cod_align >> 27)) - (ape_uuid2 & (ape_cod_align >> 27))); ape_uuid2 = (ape_uuid2 + (ape_cod_align >> 000) & 0xFF) * 0x9e3779b9925d4c17; ape_uuid2 = (ape_uuid2 + (ape_cod_align >> 010) & 0xFF) * 0x9e3779b9925d4c17; ape_uuid2 = (ape_uuid2 + (ape_cod_align >> 020) & 0xFF) * 0x9e3779b9925d4c17; ape_uuid2 = (ape_uuid2 + (ape_cod_align >> 030) & 0xFF) * 0x9e3779b9925d4c17;
ape_uuid1 = ((ape_uuid1 | (ape_cod_filesz >> 12)) - (ape_uuid1 & (ape_cod_filesz >> 12))); ape_uuid1 = ((ape_uuid1 | (ape_cod_filesz << 25)) - (ape_uuid1 & (ape_cod_filesz << 25))); ape_uuid1 = ((ape_uuid1 | (ape_cod_filesz >> 27)) - (ape_uuid1 & (ape_cod_filesz >> 27))); ape_uuid1 = (ape_uuid1 + (ape_cod_filesz >> 000) & 0xFF) * 0x9e3779b9925d4c17; ape_uuid1 = (ape_uuid1 + (ape_cod_filesz >> 010) & 0xFF) * 0x9e3779b9925d4c17; ape_uuid1 = (ape_uuid1 + (ape_cod_filesz >> 020) & 0xFF) * 0x9e3779b9925d4c17; ape_uuid1 = (ape_uuid1 + (ape_cod_filesz >> 030) & 0xFF) * 0x9e3779b9925d4c17; ape_uuid2 = ((ape_uuid2 | (ape_cod_filesz >> 12)) - (ape_uuid2 & (ape_cod_filesz >> 12))); ape_uuid2 = ((ape_uuid2 | (ape_cod_filesz << 25)) - (ape_uuid2 & (ape_cod_filesz << 25))); ape_uuid2 = ((ape_uuid2 | (ape_cod_filesz >> 27)) - (ape_uuid2 & (ape_cod_filesz >> 27))); ape_uuid2 = (ape_uuid2 + (ape_cod_filesz >> 000) & 0xFF) * 0x9e3779b9925d4c17; ape_uuid2 = (ape_uuid2 + (ape_cod_filesz >> 010) & 0xFF) * 0x9e3779b9925d4c17; ape_uuid2 = (ape_uuid2 + (ape_cod_filesz >> 020) & 0xFF) * 0x9e3779b9925d4c17; ape_uuid2 = (ape_uuid2 + (ape_cod_filesz >> 030) & 0xFF) * 0x9e3779b9925d4c17;
ape_uuid1 = ((ape_uuid1 | (ape_cod_memsz >> 12)) - (ape_uuid1 & (ape_cod_memsz >> 12))); ape_uuid1 = ((ape_uuid1 | (ape_cod_memsz << 25)) - (ape_uuid1 & (ape_cod_memsz << 25))); ape_uuid1 = ((ape_uuid1 | (ape_cod_memsz >> 27)) - (ape_uuid1 & (ape_cod_memsz >> 27))); ape_uuid1 = (ape_uuid1 + (ape_cod_memsz >> 000) & 0xFF) * 0x9e3779b9925d4c17; ape_uuid1 = (ape_uuid1 + (ape_cod_memsz >> 010) & 0xFF) * 0x9e3779b9925d4c17; ape_uuid1 = (ape_uuid1 + (ape_cod_memsz >> 020) & 0xFF) * 0x9e3779b9925d4c17; ape_uuid1 = (ape_uuid1 + (ape_cod_memsz >> 030) & 0xFF) * 0x9e3779b9925d4c17; ape_uuid2 = ((ape_uuid2 | (ape_cod_memsz >> 12)) - (ape_uuid2 & (ape_cod_memsz >> 12))); ape_uuid2 = ((ape_uuid2 | (ape_cod_memsz << 25)) - (ape_uuid2 & (ape_cod_memsz << 25))); ape_uuid2 = ((ape_uuid2 | (ape_cod_memsz >> 27)) - (ape_uuid2 & (ape_cod_memsz >> 27))); ape_uuid2 = (ape_uuid2 + (ape_cod_memsz >> 000) & 0xFF) * 0x9e3779b9925d4c17; ape_uuid2 = (ape_uuid2 + (ape_cod_memsz >> 010) & 0xFF) * 0x9e3779b9925d4c17; ape_uuid2 = (ape_uuid2 + (ape_cod_memsz >> 020) & 0xFF) * 0x9e3779b9925d4c17; ape_uuid2 = (ape_uuid2 + (ape_cod_memsz >> 030) & 0xFF) * 0x9e3779b9925d4c17;
ape_uuid1 = ((ape_uuid1 | (ape_cod_offset >> 12)) - (ape_uuid1 & (ape_cod_offset >> 12))); ape_uuid1 = ((ape_uuid1 | (ape_cod_offset << 25)) - (ape_uuid1 & (ape_cod_offset << 25))); ape_uuid1 = ((ape_uuid1 | (ape_cod_offset >> 27)) - (ape_uuid1 & (ape_cod_offset >> 27))); ape_uuid1 = (ape_uuid1 + (ape_cod_offset >> 000) & 0xFF) * 0x9e3779b9925d4c17; ape_uuid1 = (ape_uuid1 + (ape_cod_offset >> 010) & 0xFF) * 0x9e3779b9925d4c17; ape_uuid1 = (ape_uuid1 + (ape_cod_offset >> 020) & 0xFF) * 0x9e3779b9925d4c17; ape_uuid1 = (ape_uuid1 + (ape_cod_offset >> 030) & 0xFF) * 0x9e3779b9925d4c17; ape_uuid2 = ((ape_uuid2 | (ape_cod_offset >> 12)) - (ape_uuid2 & (ape_cod_offset >> 12))); ape_uuid2 = ((ape_uuid2 | (ape_cod_offset << 25)) - (ape_uuid2 & (ape_cod_offset << 25))); ape_uuid2 = ((ape_uuid2 | (ape_cod_offset >> 27)) - (ape_uuid2 & (ape_cod_offset >> 27))); ape_uuid2 = (ape_uuid2 + (ape_cod_offset >> 000) & 0xFF) * 0x9e3779b9925d4c17; ape_uuid2 = (ape_uuid2 + (ape_cod_offset >> 010) & 0xFF) * 0x9e3779b9925d4c17; ape_uuid2 = (ape_uuid2 + (ape_cod_offset >> 020) & 0xFF) * 0x9e3779b9925d4c17; ape_uuid2 = (ape_uuid2 + (ape_cod_offset >> 030) & 0xFF) * 0x9e3779b9925d4c17;
ape_uuid1 = ((ape_uuid1 | (ape_cod_paddr >> 12)) - (ape_uuid1 & (ape_cod_paddr >> 12))); ape_uuid1 = ((ape_uuid1 | (ape_cod_paddr << 25)) - (ape_uuid1 & (ape_cod_paddr << 25))); ape_uuid1 = ((ape_uuid1 | (ape_cod_paddr >> 27)) - (ape_uuid1 & (ape_cod_paddr >> 27))); ape_uuid1 = (ape_uuid1 + (ape_cod_paddr >> 000) & 0xFF) * 0x9e3779b9925d4c17; ape_uuid1 = (ape_uuid1 + (ape_cod_paddr >> 010) & 0xFF) * 0x9e3779b9925d4c17; ape_uuid1 = (ape_uuid1 + (ape_cod_paddr >> 020) & 0xFF) * 0x9e3779b9925d4c17; ape_uuid1 = (ape_uuid1 + (ape_cod_paddr >> 030) & 0xFF) * 0x9e3779b9925d4c17; ape_uuid2 = ((ape_uuid2 | (ape_cod_paddr >> 12)) - (ape_uuid2 & (ape_cod_paddr >> 12))); ape_uuid2 = ((ape_uuid2 | (ape_cod_paddr << 25)) - (ape_uuid2 & (ape_cod_paddr << 25))); ape_uuid2 = ((ape_uuid2 | (ape_cod_paddr >> 27)) - (ape_uuid2 & (ape_cod_paddr >> 27))); ape_uuid2 = (ape_uuid2 + (ape_cod_paddr >> 000) & 0xFF) * 0x9e3779b9925d4c17; ape_uuid2 = (ape_uuid2 + (ape_cod_paddr >> 010) & 0xFF) * 0x9e3779b9925d4c17; ape_uuid2 = (ape_uuid2 + (ape_cod_paddr >> 020) & 0xFF) * 0x9e3779b9925d4c17; ape_uuid2 = (ape_uuid2 + (ape_cod_paddr >> 030) & 0xFF) * 0x9e3779b9925d4c17;
ape_uuid1 = ((ape_uuid1 | (ape_cod_rva >> 12)) - (ape_uuid1 & (ape_cod_rva >> 12))); ape_uuid1 = ((ape_uuid1 | (ape_cod_rva << 25)) - (ape_uuid1 & (ape_cod_rva << 25))); ape_uuid1 = ((ape_uuid1 | (ape_cod_rva >> 27)) - (ape_uuid1 & (ape_cod_rva >> 27))); ape_uuid1 = (ape_uuid1 + (ape_cod_rva >> 000) & 0xFF) * 0x9e3779b9925d4c17; ape_uuid1 = (ape_uuid1 + (ape_cod_rva >> 010) & 0xFF) * 0x9e3779b9925d4c17; ape_uuid1 = (ape_uuid1 + (ape_cod_rva >> 020) & 0xFF) * 0x9e3779b9925d4c17; ape_uuid1 = (ape_uuid1 + (ape_cod_rva >> 030) & 0xFF) * 0x9e3779b9925d4c17; ape_uuid2 = ((ape_uuid2 | (ape_cod_rva >> 12)) - (ape_uuid2 & (ape_cod_rva >> 12))); ape_uuid2 = ((ape_uuid2 | (ape_cod_rva << 25)) - (ape_uuid2 & (ape_cod_rva << 25))); ape_uuid2 = ((ape_uuid2 | (ape_cod_rva >> 27)) - (ape_uuid2 & (ape_cod_rva >> 27))); ape_uuid2 = (ape_uuid2 + (ape_cod_rva >> 000) & 0xFF) * 0x9e3779b9925d4c17; ape_uuid2 = (ape_uuid2 + (ape_cod_rva >> 010) & 0xFF) * 0x9e3779b9925d4c17; ape_uuid2 = (ape_uuid2 + (ape_cod_rva >> 020) & 0xFF) * 0x9e3779b9925d4c17; ape_uuid2 = (ape_uuid2 + (ape_cod_rva >> 030) & 0xFF) * 0x9e3779b9925d4c17;
ape_uuid1 = ((ape_uuid1 | (ape_cod_vaddr >> 12)) - (ape_uuid1 & (ape_cod_vaddr >> 12))); ape_uuid1 = ((ape_uuid1 | (ape_cod_vaddr << 25)) - (ape_uuid1 & (ape_cod_vaddr << 25))); ape_uuid1 = ((ape_uuid1 | (ape_cod_vaddr >> 27)) - (ape_uuid1 & (ape_cod_vaddr >> 27))); ape_uuid1 = (ape_uuid1 + (ape_cod_vaddr >> 000) & 0xFF) * 0x9e3779b9925d4c17; ape_uuid1 = (ape_uuid1 + (ape_cod_vaddr >> 010) & 0xFF) * 0x9e3779b9925d4c17; ape_uuid1 = (ape_uuid1 + (ape_cod_vaddr >> 020) & 0xFF) * 0x9e3779b9925d4c17; ape_uuid1 = (ape_uuid1 + (ape_cod_vaddr >> 030) & 0xFF) * 0x9e3779b9925d4c17; ape_uuid2 = ((ape_uuid2 | (ape_cod_vaddr >> 12)) - (ape_uuid2 & (ape_cod_vaddr >> 12))); ape_uuid2 = ((ape_uuid2 | (ape_cod_vaddr << 25)) - (ape_uuid2 & (ape_cod_vaddr << 25))); ape_uuid2 = ((ape_uuid2 | (ape_cod_vaddr >> 27)) - (ape_uuid2 & (ape_cod_vaddr >> 27))); ape_uuid2 = (ape_uuid2 + (ape_cod_vaddr >> 000) & 0xFF) * 0x9e3779b9925d4c17; ape_uuid2 = (ape_uuid2 + (ape_cod_vaddr >> 010) & 0xFF) * 0x9e3779b9925d4c17; ape_uuid2 = (ape_uuid2 + (ape_cod_vaddr >> 020) & 0xFF) * 0x9e3779b9925d4c17; ape_uuid2 = (ape_uuid2 + (ape_cod_vaddr >> 030) & 0xFF) * 0x9e3779b9925d4c17;
ape_uuid1 = ((ape_uuid1 | (ape_text_align >> 12)) - (ape_uuid1 & (ape_text_align >> 12))); ape_uuid1 = ((ape_uuid1 | (ape_text_align << 25)) - (ape_uuid1 & (ape_text_align << 25))); ape_uuid1 = ((ape_uuid1 | (ape_text_align >> 27)) - (ape_uuid1 & (ape_text_align >> 27))); ape_uuid1 = (ape_uuid1 + (ape_text_align >> 000) & 0xFF) * 0x9e3779b9925d4c17; ape_uuid1 = (ape_uuid1 + (ape_text_align >> 010) & 0xFF) * 0x9e3779b9925d4c17; ape_uuid1 = (ape_uuid1 + (ape_text_align >> 020) & 0xFF) * 0x9e3779b9925d4c17; ape_uuid1 = (ape_uuid1 + (ape_text_align >> 030) & 0xFF) * 0x9e3779b9925d4c17; ape_uuid2 = ((ape_uuid2 | (ape_text_align >> 12)) - (ape_uuid2 & (ape_text_align >> 12))); ape_uuid2 = ((ape_uuid2 | (ape_text_align << 25)) - (ape_uuid2 & (ape_text_align << 25))); ape_uuid2 = ((ape_uuid2 | (ape_text_align >> 27)) - (ape_uuid2 & (ape_text_align >> 27))); ape_uuid2 = (ape_uuid2 + (ape_text_align >> 000) & 0xFF) * 0x9e3779b9925d4c17; ape_uuid2 = (ape_uuid2 + (ape_text_align >> 010) & 0xFF) * 0x9e3779b9925d4c17; ape_uuid2 = (ape_uuid2 + (ape_text_align >> 020) & 0xFF) * 0x9e3779b9925d4c17; ape_uuid2 = (ape_uuid2 + (ape_text_align >> 030) & 0xFF) * 0x9e3779b9925d4c17;
ape_uuid1 = ((ape_uuid1 | (ape_text_filesz >> 12)) - (ape_uuid1 & (ape_text_filesz >> 12))); ape_uuid1 = ((ape_uuid1 | (ape_text_filesz << 25)) - (ape_uuid1 & (ape_text_filesz << 25))); ape_uuid1 = ((ape_uuid1 | (ape_text_filesz >> 27)) - (ape_uuid1 & (ape_text_filesz >> 27))); ape_uuid1 = (ape_uuid1 + (ape_text_filesz >> 000) & 0xFF) * 0x9e3779b9925d4c17; ape_uuid1 = (ape_uuid1 + (ape_text_filesz >> 010) & 0xFF) * 0x9e3779b9925d4c17; ape_uuid1 = (ape_uuid1 + (ape_text_filesz >> 020) & 0xFF) * 0x9e3779b9925d4c17; ape_uuid1 = (ape_uuid1 + (ape_text_filesz >> 030) & 0xFF) * 0x9e3779b9925d4c17; ape_uuid2 = ((ape_uuid2 | (ape_text_filesz >> 12)) - (ape_uuid2 & (ape_text_filesz >> 12))); ape_uuid2 = ((ape_uuid2 | (ape_text_filesz << 25)) - (ape_uuid2 & (ape_text_filesz << 25))); ape_uuid2 = ((ape_uuid2 | (ape_text_filesz >> 27)) - (ape_uuid2 & (ape_text_filesz >> 27))); ape_uuid2 = (ape_uuid2 + (ape_text_filesz >> 000) & 0xFF) * 0x9e3779b9925d4c17; ape_uuid2 = (ape_uuid2 + (ape_text_filesz >> 010) & 0xFF) * 0x9e3779b9925d4c17; ape_uuid2 = (ape_uuid2 + (ape_text_filesz >> 020) & 0xFF) * 0x9e3779b9925d4c17; ape_uuid2 = (ape_uuid2 + (ape_text_filesz >> 030) & 0xFF) * 0x9e3779b9925d4c17;
ape_uuid1 = ((ape_uuid1 | (ape_text_memsz >> 12)) - (ape_uuid1 & (ape_text_memsz >> 12))); ape_uuid1 = ((ape_uuid1 | (ape_text_memsz << 25)) - (ape_uuid1 & (ape_text_memsz << 25))); ape_uuid1 = ((ape_uuid1 | (ape_text_memsz >> 27)) - (ape_uuid1 & (ape_text_memsz >> 27))); ape_uuid1 = (ape_uuid1 + (ape_text_memsz >> 000) & 0xFF) * 0x9e3779b9925d4c17; ape_uuid1 = (ape_uuid1 + (ape_text_memsz >> 010) & 0xFF) * 0x9e3779b9925d4c17; ape_uuid1 = (ape_uuid1 + (ape_text_memsz >> 020) & 0xFF) * 0x9e3779b9925d4c17; ape_uuid1 = (ape_uuid1 + (ape_text_memsz >> 030) & 0xFF) * 0x9e3779b9925d4c17; ape_uuid2 = ((ape_uuid2 | (ape_text_memsz >> 12)) - (ape_uuid2 & (ape_text_memsz >> 12))); ape_uuid2 = ((ape_uuid2 | (ape_text_memsz << 25)) - (ape_uuid2 & (ape_text_memsz << 25))); ape_uuid2 = ((ape_uuid2 | (ape_text_memsz >> 27)) - (ape_uuid2 & (ape_text_memsz >> 27))); ape_uuid2 = (ape_uuid2 + (ape_text_memsz >> 000) & 0xFF) * 0x9e3779b9925d4c17; ape_uuid2 = (ape_uuid2 + (ape_text_memsz >> 010) & 0xFF) * 0x9e3779b9925d4c17; ape_uuid2 = (ape_uuid2 + (ape_text_memsz >> 020) & 0xFF) * 0x9e3779b9925d4c17; ape_uuid2 = (ape_uuid2 + (ape_text_memsz >> 030) & 0xFF) * 0x9e3779b9925d4c17;
ape_uuid1 = ((ape_uuid1 | (ape_text_offset >> 12)) - (ape_uuid1 & (ape_text_offset >> 12))); ape_uuid1 = ((ape_uuid1 | (ape_text_offset << 25)) - (ape_uuid1 & (ape_text_offset << 25))); ape_uuid1 = ((ape_uuid1 | (ape_text_offset >> 27)) - (ape_uuid1 & (ape_text_offset >> 27))); ape_uuid1 = (ape_uuid1 + (ape_text_offset >> 000) & 0xFF) * 0x9e3779b9925d4c17; ape_uuid1 = (ape_uuid1 + (ape_text_offset >> 010) & 0xFF) * 0x9e3779b9925d4c17; ape_uuid1 = (ape_uuid1 + (ape_text_offset >> 020) & 0xFF) * 0x9e3779b9925d4c17; ape_uuid1 = (ape_uuid1 + (ape_text_offset >> 030) & 0xFF) * 0x9e3779b9925d4c17; ape_uuid2 = ((ape_uuid2 | (ape_text_offset >> 12)) - (ape_uuid2 & (ape_text_offset >> 12))); ape_uuid2 = ((ape_uuid2 | (ape_text_offset << 25)) - (ape_uuid2 & (ape_text_offset << 25))); ape_uuid2 = ((ape_uuid2 | (ape_text_offset >> 27)) - (ape_uuid2 & (ape_text_offset >> 27))); ape_uuid2 = (ape_uuid2 + (ape_text_offset >> 000) & 0xFF) * 0x9e3779b9925d4c17; ape_uuid2 = (ape_uuid2 + (ape_text_offset >> 010) & 0xFF) * 0x9e3779b9925d4c17; ape_uuid2 = (ape_uuid2 + (ape_text_offset >> 020) & 0xFF) * 0x9e3779b9925d4c17; ape_uuid2 = (ape_uuid2 + (ape_text_offset >> 030) & 0xFF) * 0x9e3779b9925d4c17;
ape_uuid1 = ((ape_uuid1 | (ape_text_paddr >> 12)) - (ape_uuid1 & (ape_text_paddr >> 12))); ape_uuid1 = ((ape_uuid1 | (ape_text_paddr << 25)) - (ape_uuid1 & (ape_text_paddr << 25))); ape_uuid1 = ((ape_uuid1 | (ape_text_paddr >> 27)) - (ape_uuid1 & (ape_text_paddr >> 27))); ape_uuid1 = (ape_uuid1 + (ape_text_paddr >> 000) & 0xFF) * 0x9e3779b9925d4c17; ape_uuid1 = (ape_uuid1 + (ape_text_paddr >> 010) & 0xFF) * 0x9e3779b9925d4c17; ape_uuid1 = (ape_uuid1 + (ape_text_paddr >> 020) & 0xFF) * 0x9e3779b9925d4c17; ape_uuid1 = (ape_uuid1 + (ape_text_paddr >> 030) & 0xFF) * 0x9e3779b9925d4c17; ape_uuid2 = ((ape_uuid2 | (ape_text_paddr >> 12)) - (ape_uuid2 & (ape_text_paddr >> 12))); ape_uuid2 = ((ape_uuid2 | (ape_text_paddr << 25)) - (ape_uuid2 & (ape_text_paddr << 25))); ape_uuid2 = ((ape_uuid2 | (ape_text_paddr >> 27)) - (ape_uuid2 & (ape_text_paddr >> 27))); ape_uuid2 = (ape_uuid2 + (ape_text_paddr >> 000) & 0xFF) * 0x9e3779b9925d4c17; ape_uuid2 = (ape_uuid2 + (ape_text_paddr >> 010) & 0xFF) * 0x9e3779b9925d4c17; ape_uuid2 = (ape_uuid2 + (ape_text_paddr >> 020) & 0xFF) * 0x9e3779b9925d4c17; ape_uuid2 = (ape_uuid2 + (ape_text_paddr >> 030) & 0xFF) * 0x9e3779b9925d4c17;
ape_uuid1 = ((ape_uuid1 | (ape_text_rva >> 12)) - (ape_uuid1 & (ape_text_rva >> 12))); ape_uuid1 = ((ape_uuid1 | (ape_text_rva << 25)) - (ape_uuid1 & (ape_text_rva << 25))); ape_uuid1 = ((ape_uuid1 | (ape_text_rva >> 27)) - (ape_uuid1 & (ape_text_rva >> 27))); ape_uuid1 = (ape_uuid1 + (ape_text_rva >> 000) & 0xFF) * 0x9e3779b9925d4c17; ape_uuid1 = (ape_uuid1 + (ape_text_rva >> 010) & 0xFF) * 0x9e3779b9925d4c17; ape_uuid1 = (ape_uuid1 + (ape_text_rva >> 020) & 0xFF) * 0x9e3779b9925d4c17; ape_uuid1 = (ape_uuid1 + (ape_text_rva >> 030) & 0xFF) * 0x9e3779b9925d4c17; ape_uuid2 = ((ape_uuid2 | (ape_text_rva >> 12)) - (ape_uuid2 & (ape_text_rva >> 12))); ape_uuid2 = ((ape_uuid2 | (ape_text_rva << 25)) - (ape_uuid2 & (ape_text_rva << 25))); ape_uuid2 = ((ape_uuid2 | (ape_text_rva >> 27)) - (ape_uuid2 & (ape_text_rva >> 27))); ape_uuid2 = (ape_uuid2 + (ape_text_rva >> 000) & 0xFF) * 0x9e3779b9925d4c17; ape_uuid2 = (ape_uuid2 + (ape_text_rva >> 010) & 0xFF) * 0x9e3779b9925d4c17; ape_uuid2 = (ape_uuid2 + (ape_text_rva >> 020) & 0xFF) * 0x9e3779b9925d4c17; ape_uuid2 = (ape_uuid2 + (ape_text_rva >> 030) & 0xFF) * 0x9e3779b9925d4c17;
ape_uuid1 = ((ape_uuid1 | (ape_text_vaddr >> 12)) - (ape_uuid1 & (ape_text_vaddr >> 12))); ape_uuid1 = ((ape_uuid1 | (ape_text_vaddr << 25)) - (ape_uuid1 & (ape_text_vaddr << 25))); ape_uuid1 = ((ape_uuid1 | (ape_text_vaddr >> 27)) - (ape_uuid1 & (ape_text_vaddr >> 27))); ape_uuid1 = (ape_uuid1 + (ape_text_vaddr >> 000) & 0xFF) * 0x9e3779b9925d4c17; ape_uuid1 = (ape_uuid1 + (ape_text_vaddr >> 010) & 0xFF) * 0x9e3779b9925d4c17; ape_uuid1 = (ape_uuid1 + (ape_text_vaddr >> 020) & 0xFF) * 0x9e3779b9925d4c17; ape_uuid1 = (ape_uuid1 + (ape_text_vaddr >> 030) & 0xFF) * 0x9e3779b9925d4c17; ape_uuid2 = ((ape_uuid2 | (ape_text_vaddr >> 12)) - (ape_uuid2 & (ape_text_vaddr >> 12))); ape_uuid2 = ((ape_uuid2 | (ape_text_vaddr << 25)) - (ape_uuid2 & (ape_text_vaddr << 25))); ape_uuid2 = ((ape_uuid2 | (ape_text_vaddr >> 27)) - (ape_uuid2 & (ape_text_vaddr >> 27))); ape_uuid2 = (ape_uuid2 + (ape_text_vaddr >> 000) & 0xFF) * 0x9e3779b9925d4c17; ape_uuid2 = (ape_uuid2 + (ape_text_vaddr >> 010) & 0xFF) * 0x9e3779b9925d4c17; ape_uuid2 = (ape_uuid2 + (ape_text_vaddr >> 020) & 0xFF) * 0x9e3779b9925d4c17; ape_uuid2 = (ape_uuid2 + (ape_text_vaddr >> 030) & 0xFF) * 0x9e3779b9925d4c17;
ape_uuid1 = ((ape_uuid1 | (ADDR(.bss) >> 12)) - (ape_uuid1 & (ADDR(.bss) >> 12))); ape_uuid1 = ((ape_uuid1 | (ADDR(.bss) << 25)) - (ape_uuid1 & (ADDR(.bss) << 25))); ape_uuid1 = ((ape_uuid1 | (ADDR(.bss) >> 27)) - (ape_uuid1 & (ADDR(.bss) >> 27))); ape_uuid1 = (ape_uuid1 + (ADDR(.bss) >> 000) & 0xFF) * 0x9e3779b9925d4c17; ape_uuid1 = (ape_uuid1 + (ADDR(.bss) >> 010) & 0xFF) * 0x9e3779b9925d4c17; ape_uuid1 = (ape_uuid1 + (ADDR(.bss) >> 020) & 0xFF) * 0x9e3779b9925d4c17; ape_uuid1 = (ape_uuid1 + (ADDR(.bss) >> 030) & 0xFF) * 0x9e3779b9925d4c17; ape_uuid2 = ((ape_uuid2 | (ADDR(.bss) >> 12)) - (ape_uuid2 & (ADDR(.bss) >> 12))); ape_uuid2 = ((ape_uuid2 | (ADDR(.bss) << 25)) - (ape_uuid2 & (ADDR(.bss) << 25))); ape_uuid2 = ((ape_uuid2 | (ADDR(.bss) >> 27)) - (ape_uuid2 & (ADDR(.bss) >> 27))); ape_uuid2 = (ape_uuid2 + (ADDR(.bss) >> 000) & 0xFF) * 0x9e3779b9925d4c17; ape_uuid2 = (ape_uuid2 + (ADDR(.bss) >> 010) & 0xFF) * 0x9e3779b9925d4c17; ape_uuid2 = (ape_uuid2 + (ADDR(.bss) >> 020) & 0xFF) * 0x9e3779b9925d4c17; ape_uuid2 = (ape_uuid2 + (ADDR(.bss) >> 030) & 0xFF) * 0x9e3779b9925d4c17;
ape_uuid1 = ((ape_uuid1 | (_start >> 12)) - (ape_uuid1 & (_start >> 12))); ape_uuid1 = ((ape_uuid1 | (_start << 25)) - (ape_uuid1 & (_start << 25))); ape_uuid1 = ((ape_uuid1 | (_start >> 27)) - (ape_uuid1 & (_start >> 27))); ape_uuid1 = (ape_uuid1 + (_start >> 000) & 0xFF) * 0x9e3779b9925d4c17; ape_uuid1 = (ape_uuid1 + (_start >> 010) & 0xFF) * 0x9e3779b9925d4c17; ape_uuid1 = (ape_uuid1 + (_start >> 020) & 0xFF) * 0x9e3779b9925d4c17; ape_uuid1 = (ape_uuid1 + (_start >> 030) & 0xFF) * 0x9e3779b9925d4c17; ape_uuid2 = ((ape_uuid2 | (_start >> 12)) - (ape_uuid2 & (_start >> 12))); ape_uuid2 = ((ape_uuid2 | (_start << 25)) - (ape_uuid2 & (_start << 25))); ape_uuid2 = ((ape_uuid2 | (_start >> 27)) - (ape_uuid2 & (_start >> 27))); ape_uuid2 = (ape_uuid2 + (_start >> 000) & 0xFF) * 0x9e3779b9925d4c17; ape_uuid2 = (ape_uuid2 + (_start >> 010) & 0xFF) * 0x9e3779b9925d4c17; ape_uuid2 = (ape_uuid2 + (_start >> 020) & 0xFF) * 0x9e3779b9925d4c17; ape_uuid2 = (ape_uuid2 + (_start >> 030) & 0xFF) * 0x9e3779b9925d4c17;
ape_uuid1 = ((ape_uuid1 | (ape_phdrs >> 12)) - (ape_uuid1 & (ape_phdrs >> 12))); ape_uuid1 = ((ape_uuid1 | (ape_phdrs << 25)) - (ape_uuid1 & (ape_phdrs << 25))); ape_uuid1 = ((ape_uuid1 | (ape_phdrs >> 27)) - (ape_uuid1 & (ape_phdrs >> 27))); ape_uuid1 = (ape_uuid1 + (ape_phdrs >> 000) & 0xFF) * 0x9e3779b9925d4c17; ape_uuid1 = (ape_uuid1 + (ape_phdrs >> 010) & 0xFF) * 0x9e3779b9925d4c17; ape_uuid1 = (ape_uuid1 + (ape_phdrs >> 020) & 0xFF) * 0x9e3779b9925d4c17; ape_uuid1 = (ape_uuid1 + (ape_phdrs >> 030) & 0xFF) * 0x9e3779b9925d4c17; ape_uuid2 = ((ape_uuid2 | (ape_phdrs >> 12)) - (ape_uuid2 & (ape_phdrs >> 12))); ape_uuid2 = ((ape_uuid2 | (ape_phdrs << 25)) - (ape_uuid2 & (ape_phdrs << 25))); ape_uuid2 = ((ape_uuid2 | (ape_phdrs >> 27)) - (ape_uuid2 & (ape_phdrs >> 27))); ape_uuid2 = (ape_uuid2 + (ape_phdrs >> 000) & 0xFF) * 0x9e3779b9925d4c17; ape_uuid2 = (ape_uuid2 + (ape_phdrs >> 010) & 0xFF) * 0x9e3779b9925d4c17; ape_uuid2 = (ape_uuid2 + (ape_phdrs >> 020) & 0xFF) * 0x9e3779b9925d4c17; ape_uuid2 = (ape_uuid2 + (ape_phdrs >> 030) & 0xFF) * 0x9e3779b9925d4c17;
ape_uuid1 = ((ape_uuid1 | (v_ape_allsectors >> 12)) - (ape_uuid1 & (v_ape_allsectors >> 12))); ape_uuid1 = ((ape_uuid1 | (v_ape_allsectors << 25)) - (ape_uuid1 & (v_ape_allsectors << 25))); ape_uuid1 = ((ape_uuid1 | (v_ape_allsectors >> 27)) - (ape_uuid1 & (v_ape_allsectors >> 27))); ape_uuid1 = (ape_uuid1 + (v_ape_allsectors >> 000) & 0xFF) * 0x9e3779b9925d4c17; ape_uuid1 = (ape_uuid1 + (v_ape_allsectors >> 010) & 0xFF) * 0x9e3779b9925d4c17; ape_uuid1 = (ape_uuid1 + (v_ape_allsectors >> 020) & 0xFF) * 0x9e3779b9925d4c17; ape_uuid1 = (ape_uuid1 + (v_ape_allsectors >> 030) & 0xFF) * 0x9e3779b9925d4c17; ape_uuid2 = ((ape_uuid2 | (v_ape_allsectors >> 12)) - (ape_uuid2 & (v_ape_allsectors >> 12))); ape_uuid2 = ((ape_uuid2 | (v_ape_allsectors << 25)) - (ape_uuid2 & (v_ape_allsectors << 25))); ape_uuid2 = ((ape_uuid2 | (v_ape_allsectors >> 27)) - (ape_uuid2 & (v_ape_allsectors >> 27))); ape_uuid2 = (ape_uuid2 + (v_ape_allsectors >> 000) & 0xFF) * 0x9e3779b9925d4c17; ape_uuid2 = (ape_uuid2 + (v_ape_allsectors >> 010) & 0xFF) * 0x9e3779b9925d4c17; ape_uuid2 = (ape_uuid2 + (v_ape_allsectors >> 020) & 0xFF) * 0x9e3779b9925d4c17; ape_uuid2 = (ape_uuid2 + (v_ape_allsectors >> 030) & 0xFF) * 0x9e3779b9925d4c17;
ape_uuid1 = ((ape_uuid1 | (ape_macho >> 12)) - (ape_uuid1 & (ape_macho >> 12))); ape_uuid1 = ((ape_uuid1 | (ape_macho << 25)) - (ape_uuid1 & (ape_macho << 25))); ape_uuid1 = ((ape_uuid1 | (ape_macho >> 27)) - (ape_uuid1 & (ape_macho >> 27))); ape_uuid1 = (ape_uuid1 + (ape_macho >> 000) & 0xFF) * 0x9e3779b9925d4c17; ape_uuid1 = (ape_uuid1 + (ape_macho >> 010) & 0xFF) * 0x9e3779b9925d4c17; ape_uuid1 = (ape_uuid1 + (ape_macho >> 020) & 0xFF) * 0x9e3779b9925d4c17; ape_uuid1 = (ape_uuid1 + (ape_macho >> 030) & 0xFF) * 0x9e3779b9925d4c17; ape_uuid2 = ((ape_uuid2 | (ape_macho >> 12)) - (ape_uuid2 & (ape_macho >> 12))); ape_uuid2 = ((ape_uuid2 | (ape_macho << 25)) - (ape_uuid2 & (ape_macho << 25))); ape_uuid2 = ((ape_uuid2 | (ape_macho >> 27)) - (ape_uuid2 & (ape_macho >> 27))); ape_uuid2 = (ape_uuid2 + (ape_macho >> 000) & 0xFF) * 0x9e3779b9925d4c17; ape_uuid2 = (ape_uuid2 + (ape_macho >> 010) & 0xFF) * 0x9e3779b9925d4c17; ape_uuid2 = (ape_uuid2 + (ape_macho >> 020) & 0xFF) * 0x9e3779b9925d4c17; ape_uuid2 = (ape_uuid2 + (ape_macho >> 030) & 0xFF) * 0x9e3779b9925d4c17;
ape_uuid1 = ((ape_uuid1 | (ape_mz >> 12)) - (ape_uuid1 & (ape_mz >> 12))); ape_uuid1 = ((ape_uuid1 | (ape_mz << 25)) - (ape_uuid1 & (ape_mz << 25))); ape_uuid1 = ((ape_uuid1 | (ape_mz >> 27)) - (ape_uuid1 & (ape_mz >> 27))); ape_uuid1 = (ape_uuid1 + (ape_mz >> 000) & 0xFF) * 0x9e3779b9925d4c17; ape_uuid1 = (ape_uuid1 + (ape_mz >> 010) & 0xFF) * 0x9e3779b9925d4c17; ape_uuid1 = (ape_uuid1 + (ape_mz >> 020) & 0xFF) * 0x9e3779b9925d4c17; ape_uuid1 = (ape_uuid1 + (ape_mz >> 030) & 0xFF) * 0x9e3779b9925d4c17; ape_uuid2 = ((ape_uuid2 | (ape_mz >> 12)) - (ape_uuid2 & (ape_mz >> 12))); ape_uuid2 = ((ape_uuid2 | (ape_mz << 25)) - (ape_uuid2 & (ape_mz << 25))); ape_uuid2 = ((ape_uuid2 | (ape_mz >> 27)) - (ape_uuid2 & (ape_mz >> 27))); ape_uuid2 = (ape_uuid2 + (ape_mz >> 000) & 0xFF) * 0x9e3779b9925d4c17; ape_uuid2 = (ape_uuid2 + (ape_mz >> 010) & 0xFF) * 0x9e3779b9925d4c17; ape_uuid2 = (ape_uuid2 + (ape_mz >> 020) & 0xFF) * 0x9e3779b9925d4c17; ape_uuid2 = (ape_uuid2 + (ape_mz >> 030) & 0xFF) * 0x9e3779b9925d4c17;
ape_uuid1 = ((ape_uuid1 | (ape_pe >> 12)) - (ape_uuid1 & (ape_pe >> 12))); ape_uuid1 = ((ape_uuid1 | (ape_pe << 25)) - (ape_uuid1 & (ape_pe << 25))); ape_uuid1 = ((ape_uuid1 | (ape_pe >> 27)) - (ape_uuid1 & (ape_pe >> 27))); ape_uuid1 = (ape_uuid1 + (ape_pe >> 000) & 0xFF) * 0x9e3779b9925d4c17; ape_uuid1 = (ape_uuid1 + (ape_pe >> 010) & 0xFF) * 0x9e3779b9925d4c17; ape_uuid1 = (ape_uuid1 + (ape_pe >> 020) & 0xFF) * 0x9e3779b9925d4c17; ape_uuid1 = (ape_uuid1 + (ape_pe >> 030) & 0xFF) * 0x9e3779b9925d4c17; ape_uuid2 = ((ape_uuid2 | (ape_pe >> 12)) - (ape_uuid2 & (ape_pe >> 12))); ape_uuid2 = ((ape_uuid2 | (ape_pe << 25)) - (ape_uuid2 & (ape_pe << 25))); ape_uuid2 = ((ape_uuid2 | (ape_pe >> 27)) - (ape_uuid2 & (ape_pe >> 27))); ape_uuid2 = (ape_uuid2 + (ape_pe >> 000) & 0xFF) * 0x9e3779b9925d4c17; ape_uuid2 = (ape_uuid2 + (ape_pe >> 010) & 0xFF) * 0x9e3779b9925d4c17; ape_uuid2 = (ape_uuid2 + (ape_pe >> 020) & 0xFF) * 0x9e3779b9925d4c17; ape_uuid2 = (ape_uuid2 + (ape_pe >> 030) & 0xFF) * 0x9e3779b9925d4c17;
ape_uuid1 = ((ape_uuid1 | (ape_pe_offset >> 12)) - (ape_uuid1 & (ape_pe_offset >> 12))); ape_uuid1 = ((ape_uuid1 | (ape_pe_offset << 25)) - (ape_uuid1 & (ape_pe_offset << 25))); ape_uuid1 = ((ape_uuid1 | (ape_pe_offset >> 27)) - (ape_uuid1 & (ape_pe_offset >> 27))); ape_uuid1 = (ape_uuid1 + (ape_pe_offset >> 000) & 0xFF) * 0x9e3779b9925d4c17; ape_uuid1 = (ape_uuid1 + (ape_pe_offset >> 010) & 0xFF) * 0x9e3779b9925d4c17; ape_uuid1 = (ape_uuid1 + (ape_pe_offset >> 020) & 0xFF) * 0x9e3779b9925d4c17; ape_uuid1 = (ape_uuid1 + (ape_pe_offset >> 030) & 0xFF) * 0x9e3779b9925d4c17; ape_uuid2 = ((ape_uuid2 | (ape_pe_offset >> 12)) - (ape_uuid2 & (ape_pe_offset >> 12))); ape_uuid2 = ((ape_uuid2 | (ape_pe_offset << 25)) - (ape_uuid2 & (ape_pe_offset << 25))); ape_uuid2 = ((ape_uuid2 | (ape_pe_offset >> 27)) - (ape_uuid2 & (ape_pe_offset >> 27))); ape_uuid2 = (ape_uuid2 + (ape_pe_offset >> 000) & 0xFF) * 0x9e3779b9925d4c17; ape_uuid2 = (ape_uuid2 + (ape_pe_offset >> 010) & 0xFF) * 0x9e3779b9925d4c17; ape_uuid2 = (ape_uuid2 + (ape_pe_offset >> 020) & 0xFF) * 0x9e3779b9925d4c17; ape_uuid2 = (ape_uuid2 + (ape_pe_offset >> 030) & 0xFF) * 0x9e3779b9925d4c17;
ape_uuid1 = ((ape_uuid1 | (ape_pe_optsz >> 12)) - (ape_uuid1 & (ape_pe_optsz >> 12))); ape_uuid1 = ((ape_uuid1 | (ape_pe_optsz << 25)) - (ape_uuid1 & (ape_pe_optsz << 25))); ape_uuid1 = ((ape_uuid1 | (ape_pe_optsz >> 27)) - (ape_uuid1 & (ape_pe_optsz >> 27))); ape_uuid1 = (ape_uuid1 + (ape_pe_optsz >> 000) & 0xFF) * 0x9e3779b9925d4c17; ape_uuid1 = (ape_uuid1 + (ape_pe_optsz >> 010) & 0xFF) * 0x9e3779b9925d4c17; ape_uuid1 = (ape_uuid1 + (ape_pe_optsz >> 020) & 0xFF) * 0x9e3779b9925d4c17; ape_uuid1 = (ape_uuid1 + (ape_pe_optsz >> 030) & 0xFF) * 0x9e3779b9925d4c17; ape_uuid2 = ((ape_uuid2 | (ape_pe_optsz >> 12)) - (ape_uuid2 & (ape_pe_optsz >> 12))); ape_uuid2 = ((ape_uuid2 | (ape_pe_optsz << 25)) - (ape_uuid2 & (ape_pe_optsz << 25))); ape_uuid2 = ((ape_uuid2 | (ape_pe_optsz >> 27)) - (ape_uuid2 & (ape_pe_optsz >> 27))); ape_uuid2 = (ape_uuid2 + (ape_pe_optsz >> 000) & 0xFF) * 0x9e3779b9925d4c17; ape_uuid2 = (ape_uuid2 + (ape_pe_optsz >> 010) & 0xFF) * 0x9e3779b9925d4c17; ape_uuid2 = (ape_uuid2 + (ape_pe_optsz >> 020) & 0xFF) * 0x9e3779b9925d4c17; ape_uuid2 = (ape_uuid2 + (ape_pe_optsz >> 030) & 0xFF) * 0x9e3779b9925d4c17;
ape_uuid1 = ((ape_uuid1 | (ape_pe_sections >> 12)) - (ape_uuid1 & (ape_pe_sections >> 12))); ape_uuid1 = ((ape_uuid1 | (ape_pe_sections << 25)) - (ape_uuid1 & (ape_pe_sections << 25))); ape_uuid1 = ((ape_uuid1 | (ape_pe_sections >> 27)) - (ape_uuid1 & (ape_pe_sections >> 27))); ape_uuid1 = (ape_uuid1 + (ape_pe_sections >> 000) & 0xFF) * 0x9e3779b9925d4c17; ape_uuid1 = (ape_uuid1 + (ape_pe_sections >> 010) & 0xFF) * 0x9e3779b9925d4c17; ape_uuid1 = (ape_uuid1 + (ape_pe_sections >> 020) & 0xFF) * 0x9e3779b9925d4c17; ape_uuid1 = (ape_uuid1 + (ape_pe_sections >> 030) & 0xFF) * 0x9e3779b9925d4c17; ape_uuid2 = ((ape_uuid2 | (ape_pe_sections >> 12)) - (ape_uuid2 & (ape_pe_sections >> 12))); ape_uuid2 = ((ape_uuid2 | (ape_pe_sections << 25)) - (ape_uuid2 & (ape_pe_sections << 25))); ape_uuid2 = ((ape_uuid2 | (ape_pe_sections >> 27)) - (ape_uuid2 & (ape_pe_sections >> 27))); ape_uuid2 = (ape_uuid2 + (ape_pe_sections >> 000) & 0xFF) * 0x9e3779b9925d4c17; ape_uuid2 = (ape_uuid2 + (ape_pe_sections >> 010) & 0xFF) * 0x9e3779b9925d4c17; ape_uuid2 = (ape_uuid2 + (ape_pe_sections >> 020) & 0xFF) * 0x9e3779b9925d4c17; ape_uuid2 = (ape_uuid2 + (ape_pe_sections >> 030) & 0xFF) * 0x9e3779b9925d4c17;
ape_uuid1 = ((ape_uuid1 | (ape_pe_sections_end >> 12)) - (ape_uuid1 & (ape_pe_sections_end >> 12))); ape_uuid1 = ((ape_uuid1 | (ape_pe_sections_end << 25)) - (ape_uuid1 & (ape_pe_sections_end << 25))); ape_uuid1 = ((ape_uuid1 | (ape_pe_sections_end >> 27)) - (ape_uuid1 & (ape_pe_sections_end >> 27))); ape_uuid1 = (ape_uuid1 + (ape_pe_sections_end >> 000) & 0xFF) * 0x9e3779b9925d4c17; ape_uuid1 = (ape_uuid1 + (ape_pe_sections_end >> 010) & 0xFF) * 0x9e3779b9925d4c17; ape_uuid1 = (ape_uuid1 + (ape_pe_sections_end >> 020) & 0xFF) * 0x9e3779b9925d4c17; ape_uuid1 = (ape_uuid1 + (ape_pe_sections_end >> 030) & 0xFF) * 0x9e3779b9925d4c17; ape_uuid2 = ((ape_uuid2 | (ape_pe_sections_end >> 12)) - (ape_uuid2 & (ape_pe_sections_end >> 12))); ape_uuid2 = ((ape_uuid2 | (ape_pe_sections_end << 25)) - (ape_uuid2 & (ape_pe_sections_end << 25))); ape_uuid2 = ((ape_uuid2 | (ape_pe_sections_end >> 27)) - (ape_uuid2 & (ape_pe_sections_end >> 27))); ape_uuid2 = (ape_uuid2 + (ape_pe_sections_end >> 000) & 0xFF) * 0x9e3779b9925d4c17; ape_uuid2 = (ape_uuid2 + (ape_pe_sections_end >> 010) & 0xFF) * 0x9e3779b9925d4c17; ape_uuid2 = (ape_uuid2 + (ape_pe_sections_end >> 020) & 0xFF) * 0x9e3779b9925d4c17; ape_uuid2 = (ape_uuid2 + (ape_pe_sections_end >> 030) & 0xFF) * 0x9e3779b9925d4c17;
ape_uuid1 = ((ape_uuid1 | (ape_pe_shnum >> 12)) - (ape_uuid1 & (ape_pe_shnum >> 12))); ape_uuid1 = ((ape_uuid1 | (ape_pe_shnum << 25)) - (ape_uuid1 & (ape_pe_shnum << 25))); ape_uuid1 = ((ape_uuid1 | (ape_pe_shnum >> 27)) - (ape_uuid1 & (ape_pe_shnum >> 27))); ape_uuid1 = (ape_uuid1 + (ape_pe_shnum >> 000) & 0xFF) * 0x9e3779b9925d4c17; ape_uuid1 = (ape_uuid1 + (ape_pe_shnum >> 010) & 0xFF) * 0x9e3779b9925d4c17; ape_uuid1 = (ape_uuid1 + (ape_pe_shnum >> 020) & 0xFF) * 0x9e3779b9925d4c17; ape_uuid1 = (ape_uuid1 + (ape_pe_shnum >> 030) & 0xFF) * 0x9e3779b9925d4c17; ape_uuid2 = ((ape_uuid2 | (ape_pe_shnum >> 12)) - (ape_uuid2 & (ape_pe_shnum >> 12))); ape_uuid2 = ((ape_uuid2 | (ape_pe_shnum << 25)) - (ape_uuid2 & (ape_pe_shnum << 25))); ape_uuid2 = ((ape_uuid2 | (ape_pe_shnum >> 27)) - (ape_uuid2 & (ape_pe_shnum >> 27))); ape_uuid2 = (ape_uuid2 + (ape_pe_shnum >> 000) & 0xFF) * 0x9e3779b9925d4c17; ape_uuid2 = (ape_uuid2 + (ape_pe_shnum >> 010) & 0xFF) * 0x9e3779b9925d4c17; ape_uuid2 = (ape_uuid2 + (ape_pe_shnum >> 020) & 0xFF) * 0x9e3779b9925d4c17; ape_uuid2 = (ape_uuid2 + (ape_pe_shnum >> 030) & 0xFF) * 0x9e3779b9925d4c17;
ape_uuid1 = ((ape_uuid1 | (ape_phdrs_end >> 12)) - (ape_uuid1 & (ape_phdrs_end >> 12))); ape_uuid1 = ((ape_uuid1 | (ape_phdrs_end << 25)) - (ape_uuid1 & (ape_phdrs_end << 25))); ape_uuid1 = ((ape_uuid1 | (ape_phdrs_end >> 27)) - (ape_uuid1 & (ape_phdrs_end >> 27))); ape_uuid1 = (ape_uuid1 + (ape_phdrs_end >> 000) & 0xFF) * 0x9e3779b9925d4c17; ape_uuid1 = (ape_uuid1 + (ape_phdrs_end >> 010) & 0xFF) * 0x9e3779b9925d4c17; ape_uuid1 = (ape_uuid1 + (ape_phdrs_end >> 020) & 0xFF) * 0x9e3779b9925d4c17; ape_uuid1 = (ape_uuid1 + (ape_phdrs_end >> 030) & 0xFF) * 0x9e3779b9925d4c17; ape_uuid2 = ((ape_uuid2 | (ape_phdrs_end >> 12)) - (ape_uuid2 & (ape_phdrs_end >> 12))); ape_uuid2 = ((ape_uuid2 | (ape_phdrs_end << 25)) - (ape_uuid2 & (ape_phdrs_end << 25))); ape_uuid2 = ((ape_uuid2 | (ape_phdrs_end >> 27)) - (ape_uuid2 & (ape_phdrs_end >> 27))); ape_uuid2 = (ape_uuid2 + (ape_phdrs_end >> 000) & 0xFF) * 0x9e3779b9925d4c17; ape_uuid2 = (ape_uuid2 + (ape_phdrs_end >> 010) & 0xFF) * 0x9e3779b9925d4c17; ape_uuid2 = (ape_uuid2 + (ape_phdrs_end >> 020) & 0xFF) * 0x9e3779b9925d4c17; ape_uuid2 = (ape_uuid2 + (ape_phdrs_end >> 030) & 0xFF) * 0x9e3779b9925d4c17;
ape_uuid1 = ((ape_uuid1 | (WinMain >> 12)) - (ape_uuid1 & (WinMain >> 12))); ape_uuid1 = ((ape_uuid1 | (WinMain << 25)) - (ape_uuid1 & (WinMain << 25))); ape_uuid1 = ((ape_uuid1 | (WinMain >> 27)) - (ape_uuid1 & (WinMain >> 27))); ape_uuid1 = (ape_uuid1 + (WinMain >> 000) & 0xFF) * 0x9e3779b9925d4c17; ape_uuid1 = (ape_uuid1 + (WinMain >> 010) & 0xFF) * 0x9e3779b9925d4c17; ape_uuid1 = (ape_uuid1 + (WinMain >> 020) & 0xFF) * 0x9e3779b9925d4c17; ape_uuid1 = (ape_uuid1 + (WinMain >> 030) & 0xFF) * 0x9e3779b9925d4c17; ape_uuid2 = ((ape_uuid2 | (WinMain >> 12)) - (ape_uuid2 & (WinMain >> 12))); ape_uuid2 = ((ape_uuid2 | (WinMain << 25)) - (ape_uuid2 & (WinMain << 25))); ape_uuid2 = ((ape_uuid2 | (WinMain >> 27)) - (ape_uuid2 & (WinMain >> 27))); ape_uuid2 = (ape_uuid2 + (WinMain >> 000) & 0xFF) * 0x9e3779b9925d4c17; ape_uuid2 = (ape_uuid2 + (WinMain >> 010) & 0xFF) * 0x9e3779b9925d4c17; ape_uuid2 = (ape_uuid2 + (WinMain >> 020) & 0xFF) * 0x9e3779b9925d4c17; ape_uuid2 = (ape_uuid2 + (WinMain >> 030) & 0xFF) * 0x9e3779b9925d4c17;
HIDDEN(ape_pe_offset = (ape_pe - ape_mz)); HIDDEN(ape_pe_offset_bcs0 = (((((((ape_pe - ape_mz) >> ((0)*8)) >> 0)&0x7) + 0x30) << 24) | ((((((ape_pe - ape_mz) >> ((0)*8)) >> 3)&0x7) + 0x30) << 16) | (((((((ape_pe - ape_mz) >> ((0)*8))&0xff) >> 6)&0x7) + 0x30) << 8) | 0x5c)); HIDDEN(ape_pe_offset_bcs1 = (((((((ape_pe - ape_mz) >> ((1)*8)) >> 0)&0x7) + 0x30) << 24) | ((((((ape_pe - ape_mz) >> ((1)*8)) >> 3)&0x7) + 0x30) << 16) | (((((((ape_pe - ape_mz) >> ((1)*8))&0xff) >> 6)&0x7) + 0x30) << 8) | 0x5c)); HIDDEN(ape_pe_offset_bcs2 = (((((((ape_pe - ape_mz) >> ((2)*8)) >> 0)&0x7) + 0x30) << 24) | ((((((ape_pe - ape_mz) >> ((2)*8)) >> 3)&0x7) + 0x30) << 16) | (((((((ape_pe - ape_mz) >> ((2)*8))&0xff) >> 6)&0x7) + 0x30) << 8) | 0x5c)); HIDDEN(ape_pe_offset_bcs3 = (((((((ape_pe - ape_mz) >> ((3)*8)) >> 0)&0x7) + 0x30) << 24) | ((((((ape_pe - ape_mz) >> ((3)*8)) >> 3)&0x7) + 0x30) << 16) | (((((((ape_pe - ape_mz) >> ((3)*8))&0xff) >> 6)&0x7) + 0x30) << 8) | 0x5c));
ape_pe_optsz = ape_pe_sections - (ape_pe + 24);
ASSERT(ape_pe_optsz % 8 == 0, "SizeOfOptionalHeader must be multiple of 8");
ape_pe_shnum = (ape_pe_sections_end - ape_pe_sections) / 40;
ape_pe_base = 0x400000;
ape_idataz = (((255 & 4) == 4) && !DEFINED(EfiMain)) ? ((ape_idata_iat) - (0x400000)) : 0;
ape_idata_iatsize = (((255 & 4) == 4) && !DEFINED(EfiMain)) ? ape_idata_iatend - ape_idata_iat : 0;
ape_idata = (((255 & 4) == 4) && !DEFINED(EfiMain)) ? ((ape_idata_idt) - (0x400000)) : 0;
ape_idata_idtsize = (((255 & 4) == 4) && !DEFINED(EfiMain)) ? ape_idata_idtend - ape_idata_idt : 0;
v_ntversion = (((255 & 4) == 4) && !DEFINED(EfiMain)) ? 6 : 1;
v_ntdllchar = (((255 & 4) == 4) && !DEFINED(EfiMain)) ? 288 : 0;
v_ntsubversion = (((255 & 4) == 4) && !DEFINED(EfiMain)) ? 6 : 5;
v_ntsubsystem = ((((255 & 4) == 4) && !DEFINED(EfiMain))
                 ? (DEFINED(GetMessage)
                    ? 2
                    : 3)
                 : 10);
ape_pe_entry = (((255 & 4) == 4) && !DEFINED(EfiMain)) ? WinMain : EfiMain;
HIDDEN(ape_macho_dd_skip_bcs0 = (((((ape_macho) - (0x400000)) / 8)) < 10000 ? (((((((ape_macho) - (0x400000)) / 8) + (((ape_macho) - (0x400000)) / 8) * 10000))) < 10000 ? 0x20202020 : (((((ape_macho) - (0x400000)) / 8) + (((ape_macho) - (0x400000)) / 8) * 10000)) < 100000 ? 0x20202030 + (((((ape_macho) - (0x400000)) / 8) + (((ape_macho) - (0x400000)) / 8) * 10000)) % 10 : (((((ape_macho) - (0x400000)) / 8) + (((ape_macho) - (0x400000)) / 8) * 10000)) < 1000000 ? 0x20203030 + ((((((ape_macho) - (0x400000)) / 8) + (((ape_macho) - (0x400000)) / 8) * 10000)) / 10) % 10 + (((((ape_macho) - (0x400000)) / 8) + (((ape_macho) - (0x400000)) / 8) * 10000)) % 10 * 0x100 : (((((ape_macho) - (0x400000)) / 8) + (((ape_macho) - (0x400000)) / 8) * 10000)) < 10000000 ? 0x20303030 + ((((((ape_macho) - (0x400000)) / 8) + (((ape_macho) - (0x400000)) / 8) * 10000)) / 100) % 10 + ((((((ape_macho) - (0x400000)) / 8) + (((ape_macho) - (0x400000)) / 8) * 10000)) / 10) % 10 * 0x100 + (((((ape_macho) - (0x400000)) / 8) + (((ape_macho) - (0x400000)) / 8) * 10000)) % 10 * 0x10000 : (((((ape_macho) - (0x400000)) / 8) + (((ape_macho) - (0x400000)) / 8) * 10000)) < 100000000 ? 0x30303030 + ((((((ape_macho) - (0x400000)) / 8) + (((ape_macho) - (0x400000)) / 8) * 10000)) / 1000) % 10 + ((((((ape_macho) - (0x400000)) / 8) + (((ape_macho) - (0x400000)) / 8) * 10000)) / 100) % 10 * 0x100 + ((((((ape_macho) - (0x400000)) / 8) + (((ape_macho) - (0x400000)) / 8) * 10000)) / 10) % 10 * 0x10000 + (((((ape_macho) - (0x400000)) / 8) + (((ape_macho) - (0x400000)) / 8) * 10000)) % 10 * 0x1000000 : 0xffffffffffffffff) | 0x10 : (((ape_macho) - (0x400000)) / 8) < 100000 ? ((((((((ape_macho) - (0x400000)) / 8) / 10) + ((((ape_macho) - (0x400000)) / 8) / 10) * 10000))) < 10000 ? 0x20202020 : ((((((ape_macho) - (0x400000)) / 8) / 10) + ((((ape_macho) - (0x400000)) / 8) / 10) * 10000)) < 100000 ? 0x20202030 + ((((((ape_macho) - (0x400000)) / 8) / 10) + ((((ape_macho) - (0x400000)) / 8) / 10) * 10000)) % 10 : ((((((ape_macho) - (0x400000)) / 8) / 10) + ((((ape_macho) - (0x400000)) / 8) / 10) * 10000)) < 1000000 ? 0x20203030 + (((((((ape_macho) - (0x400000)) / 8) / 10) + ((((ape_macho) - (0x400000)) / 8) / 10) * 10000)) / 10) % 10 + ((((((ape_macho) - (0x400000)) / 8) / 10) + ((((ape_macho) - (0x400000)) / 8) / 10) * 10000)) % 10 * 0x100 : ((((((ape_macho) - (0x400000)) / 8) / 10) + ((((ape_macho) - (0x400000)) / 8) / 10) * 10000)) < 10000000 ? 0x20303030 + (((((((ape_macho) - (0x400000)) / 8) / 10) + ((((ape_macho) - (0x400000)) / 8) / 10) * 10000)) / 100) % 10 + (((((((ape_macho) - (0x400000)) / 8) / 10) + ((((ape_macho) - (0x400000)) / 8) / 10) * 10000)) / 10) % 10 * 0x100 + ((((((ape_macho) - (0x400000)) / 8) / 10) + ((((ape_macho) - (0x400000)) / 8) / 10) * 10000)) % 10 * 0x10000 : ((((((ape_macho) - (0x400000)) / 8) / 10) + ((((ape_macho) - (0x400000)) / 8) / 10) * 10000)) < 100000000 ? 0x30303030 + (((((((ape_macho) - (0x400000)) / 8) / 10) + ((((ape_macho) - (0x400000)) / 8) / 10) * 10000)) / 1000) % 10 + (((((((ape_macho) - (0x400000)) / 8) / 10) + ((((ape_macho) - (0x400000)) / 8) / 10) * 10000)) / 100) % 10 * 0x100 + (((((((ape_macho) - (0x400000)) / 8) / 10) + ((((ape_macho) - (0x400000)) / 8) / 10) * 10000)) / 10) % 10 * 0x10000 + ((((((ape_macho) - (0x400000)) / 8) / 10) + ((((ape_macho) - (0x400000)) / 8) / 10) * 10000)) % 10 * 0x1000000 : 0xffffffffffffffff) : (((ape_macho) - (0x400000)) / 8) < 1000000 ? ((((((((ape_macho) - (0x400000)) / 8) / 100) + ((((ape_macho) - (0x400000)) / 8) / 100) * 10000))) < 10000 ? 0x20202020 : ((((((ape_macho) - (0x400000)) / 8) / 100) + ((((ape_macho) - (0x400000)) / 8) / 100) * 10000)) < 100000 ? 0x20202030 + ((((((ape_macho) - (0x400000)) / 8) / 100) + ((((ape_macho) - (0x400000)) / 8) / 100) * 10000)) % 10 : ((((((ape_macho) - (0x400000)) / 8) / 100) + ((((ape_macho) - (0x400000)) / 8) / 100) * 10000)) < 1000000 ? 0x20203030 + (((((((ape_macho) - (0x400000)) / 8) / 100) + ((((ape_macho) - (0x400000)) / 8) / 100) * 10000)) / 10) % 10 + ((((((ape_macho) - (0x400000)) / 8) / 100) + ((((ape_macho) - (0x400000)) / 8) / 100) * 10000)) % 10 * 0x100 : ((((((ape_macho) - (0x400000)) / 8) / 100) + ((((ape_macho) - (0x400000)) / 8) / 100) * 10000)) < 10000000 ? 0x20303030 + (((((((ape_macho) - (0x400000)) / 8) / 100) + ((((ape_macho) - (0x400000)) / 8) / 100) * 10000)) / 100) % 10 + (((((((ape_macho) - (0x400000)) / 8) / 100) + ((((ape_macho) - (0x400000)) / 8) / 100) * 10000)) / 10) % 10 * 0x100 + ((((((ape_macho) - (0x400000)) / 8) / 100) + ((((ape_macho) - (0x400000)) / 8) / 100) * 10000)) % 10 * 0x10000 : ((((((ape_macho) - (0x400000)) / 8) / 100) + ((((ape_macho) - (0x400000)) / 8) / 100) * 10000)) < 100000000 ? 0x30303030 + (((((((ape_macho) - (0x400000)) / 8) / 100) + ((((ape_macho) - (0x400000)) / 8) / 100) * 10000)) / 1000) % 10 + (((((((ape_macho) - (0x400000)) / 8) / 100) + ((((ape_macho) - (0x400000)) / 8) / 100) * 10000)) / 100) % 10 * 0x100 + (((((((ape_macho) - (0x400000)) / 8) / 100) + ((((ape_macho) - (0x400000)) / 8) / 100) * 10000)) / 10) % 10 * 0x10000 + ((((((ape_macho) - (0x400000)) / 8) / 100) + ((((ape_macho) - (0x400000)) / 8) / 100) * 10000)) % 10 * 0x1000000 : 0xffffffffffffffff) : (((ape_macho) - (0x400000)) / 8) < 10000000 ? ((((((((ape_macho) - (0x400000)) / 8) / 1000) + ((((ape_macho) - (0x400000)) / 8) / 1000) * 10000))) < 10000 ? 0x20202020 : ((((((ape_macho) - (0x400000)) / 8) / 1000) + ((((ape_macho) - (0x400000)) / 8) / 1000) * 10000)) < 100000 ? 0x20202030 + ((((((ape_macho) - (0x400000)) / 8) / 1000) + ((((ape_macho) - (0x400000)) / 8) / 1000) * 10000)) % 10 : ((((((ape_macho) - (0x400000)) / 8) / 1000) + ((((ape_macho) - (0x400000)) / 8) / 1000) * 10000)) < 1000000 ? 0x20203030 + (((((((ape_macho) - (0x400000)) / 8) / 1000) + ((((ape_macho) - (0x400000)) / 8) / 1000) * 10000)) / 10) % 10 + ((((((ape_macho) - (0x400000)) / 8) / 1000) + ((((ape_macho) - (0x400000)) / 8) / 1000) * 10000)) % 10 * 0x100 : ((((((ape_macho) - (0x400000)) / 8) / 1000) + ((((ape_macho) - (0x400000)) / 8) / 1000) * 10000)) < 10000000 ? 0x20303030 + (((((((ape_macho) - (0x400000)) / 8) / 1000) + ((((ape_macho) - (0x400000)) / 8) / 1000) * 10000)) / 100) % 10 + (((((((ape_macho) - (0x400000)) / 8) / 1000) + ((((ape_macho) - (0x400000)) / 8) / 1000) * 10000)) / 10) % 10 * 0x100 + ((((((ape_macho) - (0x400000)) / 8) / 1000) + ((((ape_macho) - (0x400000)) / 8) / 1000) * 10000)) % 10 * 0x10000 : ((((((ape_macho) - (0x400000)) / 8) / 1000) + ((((ape_macho) - (0x400000)) / 8) / 1000) * 10000)) < 100000000 ? 0x30303030 + (((((((ape_macho) - (0x400000)) / 8) / 1000) + ((((ape_macho) - (0x400000)) / 8) / 1000) * 10000)) / 1000) % 10 + (((((((ape_macho) - (0x400000)) / 8) / 1000) + ((((ape_macho) - (0x400000)) / 8) / 1000) * 10000)) / 100) % 10 * 0x100 + (((((((ape_macho) - (0x400000)) / 8) / 1000) + ((((ape_macho) - (0x400000)) / 8) / 1000) * 10000)) / 10) % 10 * 0x10000 + ((((((ape_macho) - (0x400000)) / 8) / 1000) + ((((ape_macho) - (0x400000)) / 8) / 1000) * 10000)) % 10 * 0x1000000 : 0xffffffffffffffff) : (((ape_macho) - (0x400000)) / 8) < 100000000 ? ((((((((ape_macho) - (0x400000)) / 8) / 10000) + ((((ape_macho) - (0x400000)) / 8) / 10000) * 10000))) < 10000 ? 0x20202020 : ((((((ape_macho) - (0x400000)) / 8) / 10000) + ((((ape_macho) - (0x400000)) / 8) / 10000) * 10000)) < 100000 ? 0x20202030 + ((((((ape_macho) - (0x400000)) / 8) / 10000) + ((((ape_macho) - (0x400000)) / 8) / 10000) * 10000)) % 10 : ((((((ape_macho) - (0x400000)) / 8) / 10000) + ((((ape_macho) - (0x400000)) / 8) / 10000) * 10000)) < 1000000 ? 0x20203030 + (((((((ape_macho) - (0x400000)) / 8) / 10000) + ((((ape_macho) - (0x400000)) / 8) / 10000) * 10000)) / 10) % 10 + ((((((ape_macho) - (0x400000)) / 8) / 10000) + ((((ape_macho) - (0x400000)) / 8) / 10000) * 10000)) % 10 * 0x100 : ((((((ape_macho) - (0x400000)) / 8) / 10000) + ((((ape_macho) - (0x400000)) / 8) / 10000) * 10000)) < 10000000 ? 0x20303030 + (((((((ape_macho) - (0x400000)) / 8) / 10000) + ((((ape_macho) - (0x400000)) / 8) / 10000) * 10000)) / 100) % 10 + (((((((ape_macho) - (0x400000)) / 8) / 10000) + ((((ape_macho) - (0x400000)) / 8) / 10000) * 10000)) / 10) % 10 * 0x100 + ((((((ape_macho) - (0x400000)) / 8) / 10000) + ((((ape_macho) - (0x400000)) / 8) / 10000) * 10000)) % 10 * 0x10000 : ((((((ape_macho) - (0x400000)) / 8) / 10000) + ((((ape_macho) - (0x400000)) / 8) / 10000) * 10000)) < 100000000 ? 0x30303030 + (((((((ape_macho) - (0x400000)) / 8) / 10000) + ((((ape_macho) - (0x400000)) / 8) / 10000) * 10000)) / 1000) % 10 + (((((((ape_macho) - (0x400000)) / 8) / 10000) + ((((ape_macho) - (0x400000)) / 8) / 10000) * 10000)) / 100) % 10 * 0x100 + (((((((ape_macho) - (0x400000)) / 8) / 10000) + ((((ape_macho) - (0x400000)) / 8) / 10000) * 10000)) / 10) % 10 * 0x10000 + ((((((ape_macho) - (0x400000)) / 8) / 10000) + ((((ape_macho) - (0x400000)) / 8) / 10000) * 10000)) % 10 * 0x1000000 : 0xffffffffffffffff) : 0xffffffffffffffff)); HIDDEN(ape_macho_dd_skip_bcs1 = (((((ape_macho) - (0x400000)) / 8)) < 10000 ? 0x20202020 : (((ape_macho) - (0x400000)) / 8) < 100000 ? 0x20202030 + (((ape_macho) - (0x400000)) / 8) % 10 : (((ape_macho) - (0x400000)) / 8) < 1000000 ? 0x20203030 + ((((ape_macho) - (0x400000)) / 8) / 10) % 10 + (((ape_macho) - (0x400000)) / 8) % 10 * 0x100 : (((ape_macho) - (0x400000)) / 8) < 10000000 ? 0x20303030 + ((((ape_macho) - (0x400000)) / 8) / 100) % 10 + ((((ape_macho) - (0x400000)) / 8) / 10) % 10 * 0x100 + (((ape_macho) - (0x400000)) / 8) % 10 * 0x10000 : (((ape_macho) - (0x400000)) / 8) < 100000000 ? 0x30303030 + ((((ape_macho) - (0x400000)) / 8) / 1000) % 10 + ((((ape_macho) - (0x400000)) / 8) / 100) % 10 * 0x100 + ((((ape_macho) - (0x400000)) / 8) / 10) % 10 * 0x10000 + (((ape_macho) - (0x400000)) / 8) % 10 * 0x1000000 : 0xffffffffffffffff));
HIDDEN(ape_macho_dd_count_bcs0 = ((((ape_macho_end - ape_macho) / 8)) < 10000 ? ((((((ape_macho_end - ape_macho) / 8) + ((ape_macho_end - ape_macho) / 8) * 10000))) < 10000 ? 0x20202020 : ((((ape_macho_end - ape_macho) / 8) + ((ape_macho_end - ape_macho) / 8) * 10000)) < 100000 ? 0x20202030 + ((((ape_macho_end - ape_macho) / 8) + ((ape_macho_end - ape_macho) / 8) * 10000)) % 10 : ((((ape_macho_end - ape_macho) / 8) + ((ape_macho_end - ape_macho) / 8) * 10000)) < 1000000 ? 0x20203030 + (((((ape_macho_end - ape_macho) / 8) + ((ape_macho_end - ape_macho) / 8) * 10000)) / 10) % 10 + ((((ape_macho_end - ape_macho) / 8) + ((ape_macho_end - ape_macho) / 8) * 10000)) % 10 * 0x100 : ((((ape_macho_end - ape_macho) / 8) + ((ape_macho_end - ape_macho) / 8) * 10000)) < 10000000 ? 0x20303030 + (((((ape_macho_end - ape_macho) / 8) + ((ape_macho_end - ape_macho) / 8) * 10000)) / 100) % 10 + (((((ape_macho_end - ape_macho) / 8) + ((ape_macho_end - ape_macho) / 8) * 10000)) / 10) % 10 * 0x100 + ((((ape_macho_end - ape_macho) / 8) + ((ape_macho_end - ape_macho) / 8) * 10000)) % 10 * 0x10000 : ((((ape_macho_end - ape_macho) / 8) + ((ape_macho_end - ape_macho) / 8) * 10000)) < 100000000 ? 0x30303030 + (((((ape_macho_end - ape_macho) / 8) + ((ape_macho_end - ape_macho) / 8) * 10000)) / 1000) % 10 + (((((ape_macho_end - ape_macho) / 8) + ((ape_macho_end - ape_macho) / 8) * 10000)) / 100) % 10 * 0x100 + (((((ape_macho_end - ape_macho) / 8) + ((ape_macho_end - ape_macho) / 8) * 10000)) / 10) % 10 * 0x10000 + ((((ape_macho_end - ape_macho) / 8) + ((ape_macho_end - ape_macho) / 8) * 10000)) % 10 * 0x1000000 : 0xffffffffffffffff) | 0x10 : ((ape_macho_end - ape_macho) / 8) < 100000 ? (((((((ape_macho_end - ape_macho) / 8) / 10) + (((ape_macho_end - ape_macho) / 8) / 10) * 10000))) < 10000 ? 0x20202020 : (((((ape_macho_end - ape_macho) / 8) / 10) + (((ape_macho_end - ape_macho) / 8) / 10) * 10000)) < 100000 ? 0x20202030 + (((((ape_macho_end - ape_macho) / 8) / 10) + (((ape_macho_end - ape_macho) / 8) / 10) * 10000)) % 10 : (((((ape_macho_end - ape_macho) / 8) / 10) + (((ape_macho_end - ape_macho) / 8) / 10) * 10000)) < 1000000 ? 0x20203030 + ((((((ape_macho_end - ape_macho) / 8) / 10) + (((ape_macho_end - ape_macho) / 8) / 10) * 10000)) / 10) % 10 + (((((ape_macho_end - ape_macho) / 8) / 10) + (((ape_macho_end - ape_macho) / 8) / 10) * 10000)) % 10 * 0x100 : (((((ape_macho_end - ape_macho) / 8) / 10) + (((ape_macho_end - ape_macho) / 8) / 10) * 10000)) < 10000000 ? 0x20303030 + ((((((ape_macho_end - ape_macho) / 8) / 10) + (((ape_macho_end - ape_macho) / 8) / 10) * 10000)) / 100) % 10 + ((((((ape_macho_end - ape_macho) / 8) / 10) + (((ape_macho_end - ape_macho) / 8) / 10) * 10000)) / 10) % 10 * 0x100 + (((((ape_macho_end - ape_macho) / 8) / 10) + (((ape_macho_end - ape_macho) / 8) / 10) * 10000)) % 10 * 0x10000 : (((((ape_macho_end - ape_macho) / 8) / 10) + (((ape_macho_end - ape_macho) / 8) / 10) * 10000)) < 100000000 ? 0x30303030 + ((((((ape_macho_end - ape_macho) / 8) / 10) + (((ape_macho_end - ape_macho) / 8) / 10) * 10000)) / 1000) % 10 + ((((((ape_macho_end - ape_macho) / 8) / 10) + (((ape_macho_end - ape_macho) / 8) / 10) * 10000)) / 100) % 10 * 0x100 + ((((((ape_macho_end - ape_macho) / 8) / 10) + (((ape_macho_end - ape_macho) / 8) / 10) * 10000)) / 10) % 10 * 0x10000 + (((((ape_macho_end - ape_macho) / 8) / 10) + (((ape_macho_end - ape_macho) / 8) / 10) * 10000)) % 10 * 0x1000000 : 0xffffffffffffffff) : ((ape_macho_end - ape_macho) / 8) < 1000000 ? (((((((ape_macho_end - ape_macho) / 8) / 100) + (((ape_macho_end - ape_macho) / 8) / 100) * 10000))) < 10000 ? 0x20202020 : (((((ape_macho_end - ape_macho) / 8) / 100) + (((ape_macho_end - ape_macho) / 8) / 100) * 10000)) < 100000 ? 0x20202030 + (((((ape_macho_end - ape_macho) / 8) / 100) + (((ape_macho_end - ape_macho) / 8) / 100) * 10000)) % 10 : (((((ape_macho_end - ape_macho) / 8) / 100) + (((ape_macho_end - ape_macho) / 8) / 100) * 10000)) < 1000000 ? 0x20203030 + ((((((ape_macho_end - ape_macho) / 8) / 100) + (((ape_macho_end - ape_macho) / 8) / 100) * 10000)) / 10) % 10 + (((((ape_macho_end - ape_macho) / 8) / 100) + (((ape_macho_end - ape_macho) / 8) / 100) * 10000)) % 10 * 0x100 : (((((ape_macho_end - ape_macho) / 8) / 100) + (((ape_macho_end - ape_macho) / 8) / 100) * 10000)) < 10000000 ? 0x20303030 + ((((((ape_macho_end - ape_macho) / 8) / 100) + (((ape_macho_end - ape_macho) / 8) / 100) * 10000)) / 100) % 10 + ((((((ape_macho_end - ape_macho) / 8) / 100) + (((ape_macho_end - ape_macho) / 8) / 100) * 10000)) / 10) % 10 * 0x100 + (((((ape_macho_end - ape_macho) / 8) / 100) + (((ape_macho_end - ape_macho) / 8) / 100) * 10000)) % 10 * 0x10000 : (((((ape_macho_end - ape_macho) / 8) / 100) + (((ape_macho_end - ape_macho) / 8) / 100) * 10000)) < 100000000 ? 0x30303030 + ((((((ape_macho_end - ape_macho) / 8) / 100) + (((ape_macho_end - ape_macho) / 8) / 100) * 10000)) / 1000) % 10 + ((((((ape_macho_end - ape_macho) / 8) / 100) + (((ape_macho_end - ape_macho) / 8) / 100) * 10000)) / 100) % 10 * 0x100 + ((((((ape_macho_end - ape_macho) / 8) / 100) + (((ape_macho_end - ape_macho) / 8) / 100) * 10000)) / 10) % 10 * 0x10000 + (((((ape_macho_end - ape_macho) / 8) / 100) + (((ape_macho_end - ape_macho) / 8) / 100) * 10000)) % 10 * 0x1000000 : 0xffffffffffffffff) : ((ape_macho_end - ape_macho) / 8) < 10000000 ? (((((((ape_macho_end - ape_macho) / 8) / 1000) + (((ape_macho_end - ape_macho) / 8) / 1000) * 10000))) < 10000 ? 0x20202020 : (((((ape_macho_end - ape_macho) / 8) / 1000) + (((ape_macho_end - ape_macho) / 8) / 1000) * 10000)) < 100000 ? 0x20202030 + (((((ape_macho_end - ape_macho) / 8) / 1000) + (((ape_macho_end - ape_macho) / 8) / 1000) * 10000)) % 10 : (((((ape_macho_end - ape_macho) / 8) / 1000) + (((ape_macho_end - ape_macho) / 8) / 1000) * 10000)) < 1000000 ? 0x20203030 + ((((((ape_macho_end - ape_macho) / 8) / 1000) + (((ape_macho_end - ape_macho) / 8) / 1000) * 10000)) / 10) % 10 + (((((ape_macho_end - ape_macho) / 8) / 1000) + (((ape_macho_end - ape_macho) / 8) / 1000) * 10000)) % 10 * 0x100 : (((((ape_macho_end - ape_macho) / 8) / 1000) + (((ape_macho_end - ape_macho) / 8) / 1000) * 10000)) < 10000000 ? 0x20303030 + ((((((ape_macho_end - ape_macho) / 8) / 1000) + (((ape_macho_end - ape_macho) / 8) / 1000) * 10000)) / 100) % 10 + ((((((ape_macho_end - ape_macho) / 8) / 1000) + (((ape_macho_end - ape_macho) / 8) / 1000) * 10000)) / 10) % 10 * 0x100 + (((((ape_macho_end - ape_macho) / 8) / 1000) + (((ape_macho_end - ape_macho) / 8) / 1000) * 10000)) % 10 * 0x10000 : (((((ape_macho_end - ape_macho) / 8) / 1000) + (((ape_macho_end - ape_macho) / 8) / 1000) * 10000)) < 100000000 ? 0x30303030 + ((((((ape_macho_end - ape_macho) / 8) / 1000) + (((ape_macho_end - ape_macho) / 8) / 1000) * 10000)) / 1000) % 10 + ((((((ape_macho_end - ape_macho) / 8) / 1000) + (((ape_macho_end - ape_macho) / 8) / 1000) * 10000)) / 100) % 10 * 0x100 + ((((((ape_macho_end - ape_macho) / 8) / 1000) + (((ape_macho_end - ape_macho) / 8) / 1000) * 10000)) / 10) % 10 * 0x10000 + (((((ape_macho_end - ape_macho) / 8) / 1000) + (((ape_macho_end - ape_macho) / 8) / 1000) * 10000)) % 10 * 0x1000000 : 0xffffffffffffffff) : ((ape_macho_end - ape_macho) / 8) < 100000000 ? (((((((ape_macho_end - ape_macho) / 8) / 10000) + (((ape_macho_end - ape_macho) / 8) / 10000) * 10000))) < 10000 ? 0x20202020 : (((((ape_macho_end - ape_macho) / 8) / 10000) + (((ape_macho_end - ape_macho) / 8) / 10000) * 10000)) < 100000 ? 0x20202030 + (((((ape_macho_end - ape_macho) / 8) / 10000) + (((ape_macho_end - ape_macho) / 8) / 10000) * 10000)) % 10 : (((((ape_macho_end - ape_macho) / 8) / 10000) + (((ape_macho_end - ape_macho) / 8) / 10000) * 10000)) < 1000000 ? 0x20203030 + ((((((ape_macho_end - ape_macho) / 8) / 10000) + (((ape_macho_end - ape_macho) / 8) / 10000) * 10000)) / 10) % 10 + (((((ape_macho_end - ape_macho) / 8) / 10000) + (((ape_macho_end - ape_macho) / 8) / 10000) * 10000)) % 10 * 0x100 : (((((ape_macho_end - ape_macho) / 8) / 10000) + (((ape_macho_end - ape_macho) / 8) / 10000) * 10000)) < 10000000 ? 0x20303030 + ((((((ape_macho_end - ape_macho) / 8) / 10000) + (((ape_macho_end - ape_macho) / 8) / 10000) * 10000)) / 100) % 10 + ((((((ape_macho_end - ape_macho) / 8) / 10000) + (((ape_macho_end - ape_macho) / 8) / 10000) * 10000)) / 10) % 10 * 0x100 + (((((ape_macho_end - ape_macho) / 8) / 10000) + (((ape_macho_end - ape_macho) / 8) / 10000) * 10000)) % 10 * 0x10000 : (((((ape_macho_end - ape_macho) / 8) / 10000) + (((ape_macho_end - ape_macho) / 8) / 10000) * 10000)) < 100000000 ? 0x30303030 + ((((((ape_macho_end - ape_macho) / 8) / 10000) + (((ape_macho_end - ape_macho) / 8) / 10000) * 10000)) / 1000) % 10 + ((((((ape_macho_end - ape_macho) / 8) / 10000) + (((ape_macho_end - ape_macho) / 8) / 10000) * 10000)) / 100) % 10 * 0x100 + ((((((ape_macho_end - ape_macho) / 8) / 10000) + (((ape_macho_end - ape_macho) / 8) / 10000) * 10000)) / 10) % 10 * 0x10000 + (((((ape_macho_end - ape_macho) / 8) / 10000) + (((ape_macho_end - ape_macho) / 8) / 10000) * 10000)) % 10 * 0x1000000 : 0xffffffffffffffff) : 0xffffffffffffffff)); HIDDEN(ape_macho_dd_count_bcs1 = ((((ape_macho_end - ape_macho) / 8)) < 10000 ? 0x20202020 : ((ape_macho_end - ape_macho) / 8) < 100000 ? 0x20202030 + ((ape_macho_end - ape_macho) / 8) % 10 : ((ape_macho_end - ape_macho) / 8) < 1000000 ? 0x20203030 + (((ape_macho_end - ape_macho) / 8) / 10) % 10 + ((ape_macho_end - ape_macho) / 8) % 10 * 0x100 : ((ape_macho_end - ape_macho) / 8) < 10000000 ? 0x20303030 + (((ape_macho_end - ape_macho) / 8) / 100) % 10 + (((ape_macho_end - ape_macho) / 8) / 10) % 10 * 0x100 + ((ape_macho_end - ape_macho) / 8) % 10 * 0x10000 : ((ape_macho_end - ape_macho) / 8) < 100000000 ? 0x30303030 + (((ape_macho_end - ape_macho) / 8) / 1000) % 10 + (((ape_macho_end - ape_macho) / 8) / 100) % 10 * 0x100 + (((ape_macho_end - ape_macho) / 8) / 10) % 10 * 0x10000 + ((ape_macho_end - ape_macho) / 8) % 10 * 0x1000000 : 0xffffffffffffffff));
ASSERT(DEFINED(ape_mz) ? ape_mz == 0x400000 : 1, "linker panic");
ASSERT((DEFINED(__init_bss_end) ? __init_bss_end : 0) % 8 == 0,
       "__init_bss misalign");
ASSERT(((DEFINED(__init_rodata_end) ? __init_rodata_end : 0) %
        8 == 0),
       "__init_rodata misalign");
ASSERT((!DEFINED(ape_grub) ? 1 : ((ape_grub) - (0x400000)) < 8192),
       "grub stub needs to be in first 8kb of image");
ASSERT((!((ape_stack_memsz) & ((ape_stack_memsz)-1))),
       "ape_stack_memsz must be a two power");
ASSERT(ape_stack_vaddr % ape_stack_memsz == 0,
       "ape_stack_vaddr must have ape_stack_memsz alignment; try using STATIC_STACK_ADDR(0x700000040000 & -ape_stack_memsz);");
ASSERT(ALIGNOF(.tdata) <= 64 && ALIGNOF(.tbss) <= 64,
       "_Thread_local _Alignof can't exceed TLS_ALIGNMENT");
ASSERT(DEFINED(main), "main() function not defined");
